[part 9 of 22: package /Cluster]
AUTOSAR XML (schema 4-3-0)
package /Cluster  (continued)
  can cluster E3V_K2CANFD: baudrate=500000, protocol-name=CAN, protocol-version=2.0, bus-off-recovery={bor-counter-l-1-to-l-2=1, bor-time-l-1=0.05, bor-time-l-2=0.2}, can-fd-baudrate=500000  (continued)
    can physical channel CHNL: comm-connectors=CN_E3V_K2CANFD  (continued)
      frame NMH_BCM1_XIX_E3V_K2CANFD: id 0x1B00000E, from SAM, frame-length=8, can-addressing-mode=EXTENDED, can-frame-rx-behavior=CAN-20, can-frame-tx-behavior=CAN-20, rx-identifier-range={lower-can-id=452984832, upper-can-id=452985855}
        nm pdu NMH_BCM1_XIX_E3V_K2CANFD: length=8, unused-bit-pattern=0
          signal NM_BCM1_CBV_AWB_XIX_NMH_BCM1_XIX_E3V_K2CANFD: start 12, 1 bit, little-endian, data-type-policy=OVERRIDE, i-signal-type=PRIMITIVE, init-value=0, base-type=BT_NM_BCM1_CBV_AWB, compu {0=Cx0_Passiver_WakeUp (CM_NM_BCM1_CBV_AWB_Cx0_Passiver_WakeUp), 1=Cx1_Aktiver_WakeUp (CM_NM_BCM1_CBV_AWB_Cx1_Aktiver_WakeUp)}, range raw 0..1, transfer-property=TRIGGERED  # Das Signal ist zu setzen, wenn das SG aktiv den Bus geweckt hat 0 = Passiver_WakeUp = SG hat das Netzwerk nicht aktiv geweckt 1 = Akitiver_WakeUp = SG hat das Netzwerk aktiv geweckt
          signal NM_BCM1_CBV_CRI_XIX_NMH_BCM1_XIX_E3V_K2CANFD: start 14, 1 bit, little-endian, data-type-policy=OVERRIDE, i-signal-type=PRIMITIVE, base-type=BT_NM_BCM1_CBV_CRI, compu {0=Cx0_NM_ohne_Clusteranforderungen (CM_NM_BCM1_CBV_CRI_Cx0_NM_ohne_Clusteranforderungen), 1=Cx1_NM_mit_Clusteranforderungen (CM_NM_BCM1_CBV_CRI_Cx1_NM_mit_Clusteranforderungen)}, range raw 0..1, transfer-property=TRIGGERED  # Das Signal ist dauerhaft gesetzt, wenn das NM-Layout Cluster- Anforderungen enthält
          signal NM_BCM1_NM_State_XIX_NMH_BCM1_XIX_E3V_K2CANFD: start 16, 6 bit, little-endian, data-type-policy=OVERRIDE, i-signal-type=PRIMITIVE, init-value=0, base-type=BT_NM_BCM1_NM_State, compu {0=Cx0_Init (CM_NM_BCM1_NM_State_Cx0_Init), 1=Cx1_NM_RM_aus_BSM (CM_NM_BCM1_NM_State_Cx1_NM_RM_aus_BSM), 2=Cx2_NM_RM_aus_PBSM (CM_NM_BCM1_NM_State_Cx2_NM_RM_aus_PBSM), 4=Cx4_NM_NO_aus_RM (CM_NM_BCM1_NM_State_Cx4_NM_NO_aus_RM), 8=Cx8_NM_NO_aus_RS (CM_NM_BCM1_NM_State_Cx8_NM_NO_aus_RS), 16=Cx10_reserved (CM_NM_BCM1_NM_State_Cx10_reserved), 32=Cx20_reserved (CM_NM_BCM1_NM_State_Cx20_reserved)}, range raw 0..32, transfer-property=TRIGGERED  # 1 = Zustand Repeat Message (<-- Bus-Sleep Mode) 2 = Zustand Repeat Message (<-- Prepare Bus-Sleep Mode) 4 = Zustand Normal Operation (<-- Repeat Message) 8 = Zustand Normal Operation (<-- Ready Sleep)
          signal NM_BCM1_Car_Wakeup_XIX_NMH_BCM1_XIX_E3V_K2CANFD: start 22, 1 bit, little-endian, data-type-policy=OVERRIDE, i-signal-type=PRIMITIVE, init-value=0, base-type=BT_NM_BCM1_Car_Wakeup, compu {0=Cx0_Inaktiv (CM_NM_BCM1_Car_Wakeup_Cx0_Inaktiv), 1=Cx1_Car_Wakeup (CM_NM_BCM1_Car_Wakeup_Cx1_Car_Wakeup)}, range raw 0..1, transfer-property=TRIGGERED  # Car Wakeup (Gateway wertet aus) MQB: -Kl.58xd, Kl.58xs, Kl.58xt eingeschaltet oder ausgeschaltet oder Dimmungssignal wurde vom Kunden geändert (nicht vom Fototransistor) -S-Kontakt wurde ein- oder ausgeschaltet -Remotestartbetrieb -Tankklappe wurde geschlossen (Drucktank) -ValetParking-Taster MQB BEV/PHEV: -Zustandswechsel_ZV -Ladesteckerentriegelung und Ladesteckerverriegelung MQB2020 & MQBw_Baseline: -KL.58x an/aus: Licht ein-/ausschalten -Beleuchtung für Schalter, Displays ein/aus -S-Kontakt an auf aus: Deaktivierung Infotainment, EPB anziehen, u.a. -S-Kontakt aus auf an: Aktivierung Infotainment u.a. - Remotestartbetrieb: angefordert (maximal 2x10 Minuten), mit HW Kl.15 ein und ZAS Kl.15 aus - Einfrierschutz: Einfrierschutz angefordert, mit HW Kl.15 ein und ZAS Kl.15 aus MLBevo: - LIN_1: Drehen Lichtdrehschalter in Stellung Standlicht - LIN_3: Visualisierung Secundärfunktionen - KL58xt Ende
          signal NM_BCM1_UDS_CC_XIX_NMH_BCM1_XIX_E3V_K2CANFD: start 23, 1 bit, little-endian, data-type-policy=OVERRIDE, i-signal-type=PRIMITIVE, init-value=0, base-type=BT_NM_BCM1_UDS_CC, compu {0=Cx0_Inaktiv (CM_NM_BCM1_UDS_CC_Cx0_Inaktiv), 1=Cx1_CC_aktiv (CM_NM_BCM1_UDS_CC_Cx1_CC_aktiv)}, range raw 0..1, transfer-property=TRIGGERED  # Funktionseinschränkung aufgrund aktivem UDS-Communication Control, siehe VW80124
          signal NM_BCM1_NM_aktiv_KL15_XIX_NMH_BCM1_XIX_E3V_K2CANFD: start 24, 1 bit, little-endian, data-type-policy=OVERRIDE, i-signal-type=PRIMITIVE, init-value=0, base-type=BT_NM_BCM1_NM_aktiv_KL15, compu {0=Cx0_Inaktiv (CM_NM_BCM1_NM_aktiv_KL15_Cx0_Inaktiv), 1=Cx1_KL15_EIN (CM_NM_BCM1_NM_aktiv_KL15_Cx1_KL15_EIN)}, range raw 0..1, transfer-property=TRIGGERED  # Steuergerät hat KL15-EIN erkannt
          signal NM_BCM1_NM_aktiv_Diagnose_XIX_NMH_BCM1_XIX_E3V_K2CANFD: start 25, 1 bit, little-endian, data-type-policy=OVERRIDE, i-signal-type=PRIMITIVE, init-value=0, base-type=BT_NM_BCM1_NM_aktiv_Diagnose, compu {0=Cx0_Init (CM_NM_BCM1_NM_aktiv_Diagnose_Cx0_Init), 1=Cx1_Diagnose_aktiv (CM_NM_BCM1_NM_aktiv_Diagnose_Cx1_Diagnose_aktiv)}, range raw 0..1, transfer-property=TRIGGERED  # Diagnose befindet sich nach VW80124 in einer NonDefaultDiagnostic-Session, z.B. ExtendedDiagnostic-Session
          signal NM_BCM1_NM_aktiv_Tmin_XIX_NMH_BCM1_XIX_E3V_K2CANFD: start 26, 1 bit, little-endian, data-type-policy=OVERRIDE, i-signal-type=PRIMITIVE, init-value=0, base-type=BT_NM_BCM1_NM_aktiv_Tmin, compu {0=Cx0_Inaktiv (CM_NM_BCM1_NM_aktiv_Tmin_Cx0_Inaktiv), 1=Cx1_Mindestaktivzeit (CM_NM_BCM1_NM_aktiv_Tmin_Cx1_Mindestaktivzeit)}, range raw 0..1, transfer-property=TRIGGERED  # Mindestaktivzeit ist noch nicht abgelaufen (bei jedem Weckereignis wird die Mindestaktivzeit neu gestartet)
          signal NM_BCM1_NM_aktiv_Aussenlicht_XIX_NMH_BCM1_XIX_E3V_K2CANFD: start 27, 1 bit, little-endian, data-type-policy=OVERRIDE, i-signal-type=PRIMITIVE, init-value=0, base-type=BT_NM_BCM1_NM_aktiv_Aussenlicht, compu {0=Cx0_Init (CM_NM_BCM1_NM_aktiv_Aussenlicht_Cx0_Init), 1=Cx1_Aussenlicht_aktiv (CM_NM_BCM1_NM_aktiv_Aussenlicht_Cx1_Aussenlicht_aktiv)}, range raw 0..1, transfer-property=TRIGGERED  # Funktionsnachlauf Außenlicht (inkl. Blinken, Warnblinken, Lichthupe)
          signal NM_BCM1_NM_aktiv_ZV_XIX_NMH_BCM1_XIX_E3V_K2CANFD: start 28, 1 bit, little-endian, data-type-policy=OVERRIDE, i-signal-type=PRIMITIVE, init-value=0, base-type=BT_NM_BCM1_NM_aktiv_ZV, compu {0=Cx0_Init (CM_NM_BCM1_NM_aktiv_ZV_Cx0_Init), 1=Cx1_ZV_aktiv (CM_NM_BCM1_NM_aktiv_ZV_Cx1_ZV_aktiv)}, range raw 0..1, transfer-property=TRIGGERED  # Funktionsnachlauf Zentralverriegelung
          signal NM_BCM1_NM_aktiv_Heizung_XIX_NMH_BCM1_XIX_E3V_K2CANFD: start 29, 1 bit, little-endian, data-type-policy=OVERRIDE, i-signal-type=PRIMITIVE, init-value=0, base-type=BT_NM_BCM1_NM_aktiv_Heizung, compu {0=Cx0_Init (CM_NM_BCM1_NM_aktiv_Heizung_Cx0_Init), 1=Cx1_Heizung_aktiv (CM_NM_BCM1_NM_aktiv_Heizung_Cx1_Heizung_aktiv)}, range raw 0..1, transfer-property=TRIGGERED  # Funktionsnachlauf Klima/Heizung
          signal NM_BCM1_NM_aktiv_Innenlicht_XIX_NMH_BCM1_XIX_E3V_K2CANFD: start 30, 1 bit, little-endian, data-type-policy=OVERRIDE, i-signal-type=PRIMITIVE, init-value=0, base-type=BT_NM_BCM1_NM_aktiv_Innenlicht, compu {0=Cx0_Init (CM_NM_BCM1_NM_aktiv_Innenlicht_Cx0_Init), 1=Cx1_Innenlicht_aktiv (CM_NM_BCM1_NM_aktiv_Innenlicht_Cx1_Innenlicht_aktiv)}, range raw 0..1, transfer-property=TRIGGERED  # Funktionsnachlauf Innenlicht (inkl. KL 58x)
          signal NM_BCM1_NM_aktiv_DWA_XIX_NMH_BCM1_XIX_E3V_K2CANFD: start 31, 1 bit, little-endian, data-type-policy=OVERRIDE, i-signal-type=PRIMITIVE, init-value=0, base-type=BT_NM_BCM1_NM_aktiv_DWA, compu {0=Cx0_Init (CM_NM_BCM1_NM_aktiv_DWA_Cx0_Init), 1=Cx1_DWA_aktiv (CM_NM_BCM1_NM_aktiv_DWA_Cx1_DWA_aktiv)}, range raw 0..1, transfer-property=TRIGGERED  # Funktionsnachlauf Diebstahlwarnanlage
          signal NM_BCM1_NM_aktiv_Funk_XIX_NMH_BCM1_XIX_E3V_K2CANFD: start 32, 1 bit, little-endian, data-type-policy=OVERRIDE, i-signal-type=PRIMITIVE, init-value=0, base-type=BT_NM_BCM1_NM_aktiv_Funk, compu {0=Cx0_Init (CM_NM_BCM1_NM_aktiv_Funk_Cx0_Init), 1=Cx1_Funk_aktiv (CM_NM_BCM1_NM_aktiv_Funk_Cx1_Funk_aktiv)}, range raw 0..1, transfer-property=TRIGGERED  # Funktionsnachlauf Funk
          signal NM_BCM1_NM_aktiv_Kessy_XIX_NMH_BCM1_XIX_E3V_K2CANFD: start 33, 1 bit, little-endian, data-type-policy=OVERRIDE, i-signal-type=PRIMITIVE, init-value=0, base-type=BT_NM_BCM1_NM_aktiv_Kessy, compu {0=Cx0_Init (CM_NM_BCM1_NM_aktiv_Kessy_Cx0_Init), 1=Cx1_Kessy_Komm_aktiv (CM_NM_BCM1_NM_aktiv_Kessy_Cx1_Kessy_Komm_aktiv)}, range raw 0..1, transfer-property=TRIGGERED  # Funktionsnachlauf Kessy
          signal NM_BCM1_NM_aktiv_TK_geschlossen_XIX_NMH_BCM1_XIX_E3V_K2CANFD: start 34, 1 bit, little-endian, data-type-policy=OVERRIDE, i-signal-type=PRIMITIVE, init-value=0, base-type=BT_NM_BCM1_NM_aktiv_TK_geschlossen, compu {0=Cx0_Init (CM_NM_BCM1_NM_aktiv_TK_geschlossen_Cx0_Init), 1=Cx1_TK_geschlossen_aktiv (CM_NM_BCM1_NM_aktiv_TK_geschlossen_Cx1_TK_geschlossen_aktiv)}, range raw 0..1, transfer-property=TRIGGERED  # Drucktank: Rückmeldung des Tankklappenstatus (Tankklappe wurde geschlossen)
          signal NM_BCM1_NM_aktiv_Applikation_XIX_NMH_BCM1_XIX_E3V_K2CANFD: start 35, 1 bit, little-endian, data-type-policy=OVERRIDE, i-signal-type=PRIMITIVE, init-value=0, base-type=BT_NM_BCM1_NM_aktiv_Applikation, compu {1=Cx1_Applikationsanforderung_CAN (CM_NM_BCM1_NM_aktiv_Applikation_Cx1_Applikationsanforderung_CAN)}, range raw 1, transfer-property=TRIGGERED  # Eine Applikationsanforderung fordert den Bus.
          signal NM_BCM1_NM_aktiv_Remotestart_XIX_NMH_BCM1_XIX_E3V_K2CANFD: start 36, 1 bit, little-endian, data-type-policy=OVERRIDE, i-signal-type=PRIMITIVE, init-value=0, base-type=BT_NM_BCM1_NM_aktiv_Remotestart, compu {0=Cx0_Init (CM_NM_BCM1_NM_aktiv_Remotestart_Cx0_Init), 1=Cx1_Remotestart_aktiv (CM_NM_BCM1_NM_aktiv_Remotestart_Cx1_Remotestart_aktiv)}, range raw 0..1, transfer-property=TRIGGERED  # Funktionsnachlauf Remotestart
          signal NM_BCM1_NM_aktiv_Remot_Door_L_Un_XIX_NMH_BCM1_XIX_E3V_K2CANFD: start 37, 1 bit, little-endian, data-type-policy=OVERRIDE, i-signal-type=PRIMITIVE, init-value=0, base-type=BT_NM_BCM1_NM_aktiv_Remot_Door_L_Un, compu {0=Cx0_Inaktiv (CM_NM_BCM1_NM_aktiv_Remot_Door_L_Un_Cx0_Inaktiv), 1=Cx1_Remote_Door_Lock_Unlock_aktiv (CM_NM_BCM1_NM_aktiv_Remot_Door_L_Un_Cx1_Remote_Door_Lock_Unlock_aktiv)}, range raw 0..1, transfer-property=TRIGGERED  # Remote Door Lock oder Unlock wird ausgefuehrt
          signal NM_BCM1_CAB_V15_XIX_NMH_BCM1_XIX_E3V_K2CANFD: start 40, 24 bit, opaque, data-type-policy=OVERRIDE, i-signal-type=ARRAY, init-value=[0b00000000, 0b00000000, 0b00000000], base-type=BT_NM_BCM1_CAB_V15, compu {0=Cx0_Init (CM_NM_BCM1_CAB_V15_Cx0_Init), 1=Cx1_CAB_01_Antrieb (CM_NM_BCM1_CAB_V15_Cx1_CAB_01_Antrieb), 2=Cx2_CAB_02_Hybrid_Laden (CM_NM_BCM1_CAB_V15_Cx2_CAB_02_Hybrid_Laden), 4=Cx4_CAB_03_Fahrwerk (CM_NM_BCM1_CAB_V15_Cx4_CAB_03_Fahrwerk), 8=Cx8_CAB_04_Fahrerassistenz (CM_NM_BCM1_CAB_V15_Cx8_CAB_04_Fahrerassistenz), 16=Cx10_CAB_05_Komfort (CM_NM_BCM1_CAB_V15_Cx10_CAB_05_Komfort), 32=Cx20_CAB_06_Anzeige (CM_NM_BCM1_CAB_V15_Cx20_CAB_06_Anzeige), 64=Cx40_CAB_07_Connect (CM_NM_BCM1_CAB_V15_Cx40_CAB_07_Connect), 128=Cx80_CAB_08_MIB (CM_NM_BCM1_CAB_V15_Cx80_CAB_08_MIB), 256=Cx100_CAB_09_Standheizung (CM_NM_BCM1_CAB_V15_Cx100_CAB_09_Standheizung), 512=Cx200_CAB_10_MDK (CM_NM_BCM1_CAB_V15_Cx200_CAB_10_MDK), 1024=Cx400_CAB_11_VLAN_Fahrerassistenz (CM_NM_BCM1_CAB_V15_Cx400_CAB_11_VLAN_Fahrerassistenz), 4096=Cx1000_CAB_13_VLAN_Connect (CM_NM_BCM1_CAB_V15_Cx1000_CAB_13_VLAN_Connect), 8192=Cx2000_CAB_14_VLAN_Infotainment (CM_NM_BCM1_CAB_V15_Cx2000_CAB_14_VLAN_Infotainment), 16384=Cx4000_CAB_15_Laden (CM_NM_BCM1_CAB_V15_Cx4000_CAB_15_Laden), 32768=Cx8000_CAB_16_Licht (CM_NM_BCM1_CAB_V15_Cx8000_CAB_16_Licht), 65536=Cx10000_CAB_17_RTM (CM_NM_BCM1_CAB_V15_Cx10000_CAB_17_RTM)}, range raw 0..65536, transfer-property=TRIGGERED  # CAB = Clusteraktivbits (V15) CAB_03_Fahrwerk Änderung Türstatus (ELock Aktivierung ü. Airbag-SG) CAB_04_Fahrerassistenz Änderung Türstatus (weckt CPD)
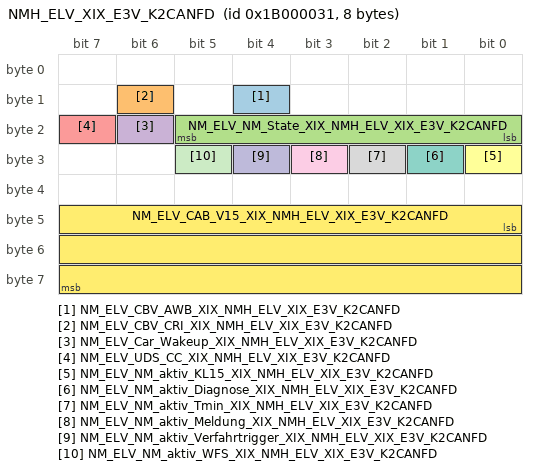
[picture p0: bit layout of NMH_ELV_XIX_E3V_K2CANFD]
      frame NMH_ELV_XIX_E3V_K2CANFD: id 0x1B000031, to SAM, frame-length=8, can-addressing-mode=EXTENDED, can-frame-rx-behavior=CAN-20, can-frame-tx-behavior=CAN-20, rx-identifier-range={lower-can-id=452984832, upper-can-id=452985855}
        nm pdu NMH_ELV_XIX_E3V_K2CANFD: length=8, unused-bit-pattern=0
          signal NM_ELV_CBV_AWB_XIX_NMH_ELV_XIX_E3V_K2CANFD: start 12, 1 bit, little-endian, data-type-policy=OVERRIDE, i-signal-type=PRIMITIVE, init-value=0, base-type=BT_NM_ELV_CBV_AWB, compu {0=Cx0_Passiver_WakeUp (CM_NM_ELV_CBV_AWB_Cx0_Passiver_WakeUp), 1=Cx1_Aktiver_WakeUp (CM_NM_ELV_CBV_AWB_Cx1_Aktiver_WakeUp)}, range raw 0..1, transfer-property=TRIGGERED  # Das Signal ist zu setzen, wenn das SG aktiv den Bus geweckt hat 0 = Passiver_WakeUp = SG hat das Netzwerk nicht aktiv geweckt 1 = Akitiver_WakeUp = SG hat das Netzwerk aktiv geweckt
          signal NM_ELV_CBV_CRI_XIX_NMH_ELV_XIX_E3V_K2CANFD: start 14, 1 bit, little-endian, data-type-policy=OVERRIDE, i-signal-type=PRIMITIVE, base-type=BT_NM_ELV_CBV_CRI, compu {0=Cx0_NM_ohne_Clusteranforderungen (CM_NM_ELV_CBV_CRI_Cx0_NM_ohne_Clusteranforderungen), 1=Cx1_NM_mit_Clusteranforderungen (CM_NM_ELV_CBV_CRI_Cx1_NM_mit_Clusteranforderungen)}, range raw 0..1, transfer-property=TRIGGERED  # Das Signal ist dauerhaft gesetzt, wenn das NM-Layout Cluster- Anforderungen enthält
          signal NM_ELV_NM_State_XIX_NMH_ELV_XIX_E3V_K2CANFD: start 16, 6 bit, little-endian, data-type-policy=OVERRIDE, i-signal-type=PRIMITIVE, init-value=0, base-type=BT_NM_ELV_NM_State, compu {0=Cx0_Init (CM_NM_ELV_NM_State_Cx0_Init), 1=Cx1_NM_RM_aus_BSM (CM_NM_ELV_NM_State_Cx1_NM_RM_aus_BSM), 2=Cx2_NM_RM_aus_PBSM (CM_NM_ELV_NM_State_Cx2_NM_RM_aus_PBSM), 4=Cx4_NM_NO_aus_RM (CM_NM_ELV_NM_State_Cx4_NM_NO_aus_RM), 8=Cx8_NM_NO_aus_RS (CM_NM_ELV_NM_State_Cx8_NM_NO_aus_RS), 16=Cx10_reserved (CM_NM_ELV_NM_State_Cx10_reserved), 32=Cx20_reserved (CM_NM_ELV_NM_State_Cx20_reserved)}, range raw 0..32, transfer-property=TRIGGERED, to SAM(timeout 2 s)  # 1 = Zustand Repeat Message (<-- Bus-Sleep Mode) 2 = Zustand Repeat Message (<-- Prepare Bus-Sleep Mode) 4 = Zustand Normal Operation (<-- Repeat Message) 8 = Zustand Normal Operation (<-- Ready Sleep)
          signal NM_ELV_Car_Wakeup_XIX_NMH_ELV_XIX_E3V_K2CANFD: start 22, 1 bit, little-endian, data-type-policy=OVERRIDE, i-signal-type=PRIMITIVE, init-value=0, base-type=BT_NM_ELV_Car_Wakeup, compu {0=Cx0_Inaktiv (CM_NM_ELV_Car_Wakeup_Cx0_Inaktiv), 1=Cx1_Car_Wakeup (CM_NM_ELV_Car_Wakeup_Cx1_Car_Wakeup)}, range raw 0..1, transfer-property=TRIGGERED  # Car Wakeup (Gateway wertet aus) ELV MQB_Gen1 -Gedrückter ZAT-Startwunsch MSG (für 2 Sekunden) -Verriegelungsbedingungen prüfen -Senden V-Signal (6 - 30 Sekunden) ELV MQB_Gen2 -Verriegelungsbedingungen prüfen -Senden V-Signal (6 - 30 Sekunden) ELV MQB2020: -Verriegelungsbedingungen prüfen -Senden V-Signal (6 - 30 Sekunden) ELV E3_1_1: -Verriegelungsbedingungen prüfen -Senden V-Signal (6 - 30 Sekunden) -Entriegelungs-Retry -bis zu 6 Entriegelungsversuche (ca. 15 Sekunden) mit Text nach 3.Versuch -Steuergerätefehler -SG-defekt, keine Entriegelung, Liegenbleiber ELV E3_1_2: -Verriegelungsbedingungen prüfen -Senden V-Signal (6 - 30 Sekunden) -Entriegelungs-Retry -bis zu 6 Entriegelungsversuche (ca. 15 Sekunden) mit Text nach 3.Versuch -Steuergerätefehler -SG-defekt, keine Entriegelung, Liegenbleiber ELV MLBevo: -Verriegelungsbedingungen prüfen -Meldung bei verspannter Lenksäule ELV MQBw_Baseline: -Verriegelungsbedingungen prüfen -Senden V-Signal (6 - 30 Sekunden) -Entriegelungs-Retry -bis zu 6 Entriegelungsversuche (ca. 15 Sekunden) mit Text nach 3.Versuch -Steuergerätefehler -SG-defekt, keine Entriegelung, Liegenbleiber
          signal NM_ELV_UDS_CC_XIX_NMH_ELV_XIX_E3V_K2CANFD: start 23, 1 bit, little-endian, data-type-policy=OVERRIDE, i-signal-type=PRIMITIVE, init-value=0, base-type=BT_NM_ELV_UDS_CC, compu {0=Cx0_Inaktiv (CM_NM_ELV_UDS_CC_Cx0_Inaktiv), 1=Cx1_CC_aktiv (CM_NM_ELV_UDS_CC_Cx1_CC_aktiv)}, range raw 0..1, transfer-property=TRIGGERED  # Funktionseinschränkung aufgrund aktivem UDS-Communication Control, siehe VW80124
          signal NM_ELV_NM_aktiv_KL15_XIX_NMH_ELV_XIX_E3V_K2CANFD: start 24, 1 bit, little-endian, data-type-policy=OVERRIDE, i-signal-type=PRIMITIVE, init-value=0, base-type=BT_NM_ELV_NM_aktiv_KL15, compu {0=Cx0_Inaktiv (CM_NM_ELV_NM_aktiv_KL15_Cx0_Inaktiv), 1=Cx1_KL15_EIN (CM_NM_ELV_NM_aktiv_KL15_Cx1_KL15_EIN)}, range raw 0..1, transfer-property=TRIGGERED  # Steuergerät hat KL15-EIN erkannt
          signal NM_ELV_NM_aktiv_Diagnose_XIX_NMH_ELV_XIX_E3V_K2CANFD: start 25, 1 bit, little-endian, data-type-policy=OVERRIDE, i-signal-type=PRIMITIVE, init-value=0, base-type=BT_NM_ELV_NM_aktiv_Diagnose, compu {0=Cx0_Init (CM_NM_ELV_NM_aktiv_Diagnose_Cx0_Init), 1=Cx1_Diagnose_aktiv (CM_NM_ELV_NM_aktiv_Diagnose_Cx1_Diagnose_aktiv)}, range raw 0..1, transfer-property=TRIGGERED  # Diagnose befindet sich nach VW80124 in einer NonDefaultDiagnostic-Session, z.B. ExtendedDiagnostic-Session
          signal NM_ELV_NM_aktiv_Tmin_XIX_NMH_ELV_XIX_E3V_K2CANFD: start 26, 1 bit, little-endian, data-type-policy=OVERRIDE, i-signal-type=PRIMITIVE, init-value=0, base-type=BT_NM_ELV_NM_aktiv_Tmin, compu {0=Cx0_Inaktiv (CM_NM_ELV_NM_aktiv_Tmin_Cx0_Inaktiv), 1=Cx1_Mindestaktivzeit (CM_NM_ELV_NM_aktiv_Tmin_Cx1_Mindestaktivzeit)}, range raw 0..1, transfer-property=TRIGGERED  # Mindestaktivzeit ist noch nicht abgelaufen (bei jedem Weckereignis wird die Mindestaktivzeit neu gestartet)
          signal NM_ELV_NM_aktiv_Meldung_XIX_NMH_ELV_XIX_E3V_K2CANFD: start 27, 1 bit, little-endian, data-type-policy=OVERRIDE, i-signal-type=PRIMITIVE, init-value=0, base-type=BT_NM_ELV_NM_aktiv_Meldung, compu {1=Cx1_Meldung_aktiv (CM_NM_ELV_NM_aktiv_Meldung_Cx1_Meldung_aktiv)}, range raw 1, transfer-property=TRIGGERED  # Fahrerinformation aktiv
          signal NM_ELV_NM_aktiv_Verfahrtrigger_XIX_NMH_ELV_XIX_E3V_K2CANFD: start 28, 1 bit, little-endian, data-type-policy=OVERRIDE, i-signal-type=PRIMITIVE, init-value=0, base-type=BT_NM_ELV_NM_aktiv_Verfahrtrigger, compu {1=Cx1_Trigger_aktiv (CM_NM_ELV_NM_aktiv_Verfahrtrigger_Cx1_Trigger_aktiv)}, range raw 1, transfer-property=TRIGGERED  # Aktiver Trigger zum Verfahren der ELV
          signal NM_ELV_NM_aktiv_WFS_XIX_NMH_ELV_XIX_E3V_K2CANFD: start 29, 1 bit, little-endian, data-type-policy=OVERRIDE, i-signal-type=PRIMITIVE, init-value=0, base-type=BT_NM_ELV_NM_aktiv_WFS, compu {1=Cx1_WFS_Komm_aktiv (CM_NM_ELV_NM_aktiv_WFS_Cx1_WFS_Komm_aktiv)}, range raw 1, transfer-property=TRIGGERED  # WFS-Kommunikation aktiv
          signal NM_ELV_CAB_V15_XIX_NMH_ELV_XIX_E3V_K2CANFD: start 40, 24 bit, opaque, data-type-policy=OVERRIDE, i-signal-type=ARRAY, init-value=[0b00000000, 0b00000000, 0b00000000], base-type=BT_NM_ELV_CAB_V15, compu {0=Cx0_Init (CM_NM_ELV_CAB_V15_Cx0_Init), 1=Cx1_CAB_01_Antrieb (CM_NM_ELV_CAB_V15_Cx1_CAB_01_Antrieb), 2=Cx2_CAB_02_Hybrid_Laden (CM_NM_ELV_CAB_V15_Cx2_CAB_02_Hybrid_Laden), 4=Cx4_CAB_03_Fahrwerk (CM_NM_ELV_CAB_V15_Cx4_CAB_03_Fahrwerk), 8=Cx8_CAB_04_Fahrerassistenz (CM_NM_ELV_CAB_V15_Cx8_CAB_04_Fahrerassistenz), 16=Cx10_CAB_05_Komfort (CM_NM_ELV_CAB_V15_Cx10_CAB_05_Komfort), 32=Cx20_CAB_06_Anzeige (CM_NM_ELV_CAB_V15_Cx20_CAB_06_Anzeige), 64=Cx40_CAB_07_Connect (CM_NM_ELV_CAB_V15_Cx40_CAB_07_Connect), 128=Cx80_CAB_08_MIB (CM_NM_ELV_CAB_V15_Cx80_CAB_08_MIB), 256=Cx100_CAB_09_Standheizung (CM_NM_ELV_CAB_V15_Cx100_CAB_09_Standheizung), 512=Cx200_CAB_10_MDK (CM_NM_ELV_CAB_V15_Cx200_CAB_10_MDK), 1024=Cx400_CAB_11_VLAN_Fahrerassistenz (CM_NM_ELV_CAB_V15_Cx400_CAB_11_VLAN_Fahrerassistenz), 4096=Cx1000_CAB_13_VLAN_Connect (CM_NM_ELV_CAB_V15_Cx1000_CAB_13_VLAN_Connect), 8192=Cx2000_CAB_14_VLAN_Infotainment (CM_NM_ELV_CAB_V15_Cx2000_CAB_14_VLAN_Infotainment), 16384=Cx4000_CAB_15_Laden (CM_NM_ELV_CAB_V15_Cx4000_CAB_15_Laden), 32768=Cx8000_CAB_16_Licht (CM_NM_ELV_CAB_V15_Cx8000_CAB_16_Licht), 65536=Cx10000_CAB_17_RTM (CM_NM_ELV_CAB_V15_Cx10000_CAB_17_RTM)}, range raw 0..65536, transfer-property=TRIGGERED  # CAB = Clusteraktivbits (V15)
      frame NMH_Gateway_XIX_E3V_K2CANFD: id 0x1B000010, to SAM, frame-length=8, can-addressing-mode=EXTENDED, can-frame-rx-behavior=CAN-20, can-frame-tx-behavior=CAN-20, rx-identifier-range={lower-can-id=452984832, upper-can-id=452985855}
        nm pdu NMH_Gateway_XIX_E3V_K2CANFD: length=8, unused-bit-pattern=0
          signal NM_Gateway_CBV_AWB_XIX_NMH_Gateway_XIX_E3V_K2CANFD: start 12, 1 bit, little-endian, data-type-policy=OVERRIDE, i-signal-type=PRIMITIVE, init-value=0, base-type=BT_NM_Gateway_CBV_AWB, compu {0=Cx0_Passiver_WakeUp (CM_NM_Gateway_CBV_AWB_Cx0_Passiver_WakeUp), 1=Cx1_Aktiver_WakeUp (CM_NM_Gateway_CBV_AWB_Cx1_Aktiver_WakeUp)}, range raw 0..1, transfer-property=TRIGGERED  # Das Signal ist zu setzen, wenn das SG aktiv den Bus geweckt hat 0 = Passiver_WakeUp = SG hat das Netzwerk nicht aktiv geweckt 1 = Akitiver_WakeUp = SG hat das Netzwerk aktiv geweckt
          signal NM_Gateway_CBV_CRI_XIX_NMH_Gateway_XIX_E3V_K2CANFD: start 14, 1 bit, little-endian, data-type-policy=OVERRIDE, i-signal-type=PRIMITIVE, base-type=BT_NM_Gateway_CBV_CRI, compu {0=Cx0_NM_ohne_Clusteranforderungen (CM_NM_Gateway_CBV_CRI_Cx0_NM_ohne_Clusteranforderungen), 1=Cx1_NM_mit_Clusteranforderungen (CM_NM_Gateway_CBV_CRI_Cx1_NM_mit_Clusteranforderungen)}, range raw 0..1, transfer-property=TRIGGERED  # Das Signal ist dauerhaft gesetzt, wenn das NM-Layout Cluster- Anforderungen enthält
          signal NM_Gateway_NM_State_XIX_NMH_Gateway_XIX_E3V_K2CANFD: start 16, 6 bit, little-endian, data-type-policy=OVERRIDE, i-signal-type=PRIMITIVE, init-value=0, base-type=BT_NM_Gateway_NM_State, compu {0=Cx0_Init (CM_NM_Gateway_NM_State_Cx0_Init), 1=Cx1_NM_RM_aus_BSM (CM_NM_Gateway_NM_State_Cx1_NM_RM_aus_BSM), 2=Cx2_NM_RM_aus_PBSM (CM_NM_Gateway_NM_State_Cx2_NM_RM_aus_PBSM), 4=Cx4_NM_NO_aus_RM (CM_NM_Gateway_NM_State_Cx4_NM_NO_aus_RM), 8=Cx8_NM_NO_aus_RS (CM_NM_Gateway_NM_State_Cx8_NM_NO_aus_RS), 16=Cx10_NM_RM_aus_RS (CM_NM_Gateway_NM_State_Cx10_NM_RM_aus_RS), 32=Cx20_NM_RM_aus_NO (CM_NM_Gateway_NM_State_Cx20_NM_RM_aus_NO)}, range raw 0..32, transfer-property=TRIGGERED, to SAM(timeout 2 s)  # 1 = Zustand Repeat Message (<-- Bus-Sleep Mode) 2 = Zustand Repeat Message (<-- Prepare Bus-Sleep Mode) 4 = Zustand Normal Operation (<-- Repeat Message) 8 = Zustand Normal Operation (<-- Ready Sleep) 16 = Zustand Repeat Message (<-- Ready Sleep) 32 = Zustand Repeat Message (<-- Normal Operation)
          signal NM_Gateway_Car_Wakeup_XIX_NMH_Gateway_XIX_E3V_K2CANFD: start 22, 1 bit, little-endian, data-type-policy=OVERRIDE, i-signal-type=PRIMITIVE, init-value=0, base-type=BT_NM_Gateway_Car_Wakeup, compu {0=Cx0_Inaktiv (CM_NM_Gateway_Car_Wakeup_Cx0_Inaktiv), 1=Cx1_Car_Wakeup (CM_NM_Gateway_Car_Wakeup_Cx1_Car_Wakeup)}, range raw 0..1, transfer-property=TRIGGERED  # Car Wakeup (Subbusmaster wertet aus) MQB: -Diagnose- oder Komponentenschutzmaster-Funktion weckt den schlafenden Subbus (z.B. MOST) E3_Volumen: - Diagnose aktiv -aktive Diagnosekommunikation am OBD-Stecker MQBw_Baseline: - Diagnose aktiv -aktive Diagnosekommunikation am OBD-Stecker
          signal NM_Gateway_UDS_CC_XIX_NMH_Gateway_XIX_E3V_K2CANFD: start 23, 1 bit, little-endian, data-type-policy=OVERRIDE, i-signal-type=PRIMITIVE, init-value=0, base-type=BT_NM_Gateway_UDS_CC, compu {0=Cx0_Inaktiv (CM_NM_Gateway_UDS_CC_Cx0_Inaktiv), 1=Cx1_CC_aktiv (CM_NM_Gateway_UDS_CC_Cx1_CC_aktiv)}, range raw 0..1, transfer-property=TRIGGERED  # Funktionseinschränkung aufgrund aktivem UDS-Communication Control, siehe VW80124
          signal NM_Gateway_NM_aktiv_KL15_XIX_NMH_Gateway_XIX_E3V_K2CANFD: start 24, 1 bit, little-endian, data-type-policy=OVERRIDE, i-signal-type=PRIMITIVE, init-value=0, base-type=BT_NM_Gateway_NM_aktiv_KL15, compu {0=Cx0_Inaktiv (CM_NM_Gateway_NM_aktiv_KL15_Cx0_Inaktiv), 1=Cx1_KL15_EIN (CM_NM_Gateway_NM_aktiv_KL15_Cx1_KL15_EIN)}, range raw 0..1, transfer-property=TRIGGERED  # Steuergerät hat KL15-EIN erkannt
          signal NM_Gateway_NM_aktiv_Diagnose_XIX_NMH_Gateway_XIX_E3V_K2CANFD: start 25, 1 bit, little-endian, data-type-policy=OVERRIDE, i-signal-type=PRIMITIVE, init-value=0, base-type=BT_NM_Gateway_NM_aktiv_Diagnose, compu {0=Cx0_Init (CM_NM_Gateway_NM_aktiv_Diagnose_Cx0_Init), 1=Cx1_Diagnose_aktiv (CM_NM_Gateway_NM_aktiv_Diagnose_Cx1_Diagnose_aktiv)}, range raw 0..1, transfer-property=TRIGGERED  # Diagnose befindet sich nach VW80124 in einer NonDefaultDiagnostic-Session, z.B. ExtendedDiagnostic-Session
          signal NM_Gateway_NM_aktiv_Tmin_XIX_NMH_Gateway_XIX_E3V_K2CANFD: start 26, 1 bit, little-endian, data-type-policy=OVERRIDE, i-signal-type=PRIMITIVE, init-value=0, base-type=BT_NM_Gateway_NM_aktiv_Tmin, compu {0=Cx0_Inaktiv (CM_NM_Gateway_NM_aktiv_Tmin_Cx0_Inaktiv), 1=Cx1_Mindestaktivzeit (CM_NM_Gateway_NM_aktiv_Tmin_Cx1_Mindestaktivzeit)}, range raw 0..1, transfer-property=TRIGGERED  # Mindestaktivzeit ist noch nicht abgelaufen (bei jedem Weckereignis wird die Mindestaktivzeit neu gestartet)
          signal NM_Gateway_NM_aktiv_Kessy_XIX_NMH_Gateway_XIX_E3V_K2CANFD: start 27, 1 bit, little-endian, data-type-policy=OVERRIDE, i-signal-type=PRIMITIVE, init-value=0, base-type=BT_NM_Gateway_NM_aktiv_Kessy, compu {0=Cx0_Inaktiv (CM_NM_Gateway_NM_aktiv_Kessy_Cx0_Inaktiv), 1=Cx1_Kessy_aktiv (CM_NM_Gateway_NM_aktiv_Kessy_Cx1_Kessy_aktiv)}, range raw 0..1, transfer-property=TRIGGERED  # Dieser Bus wird auf Grund einer Aktivität der Funktion Kessy wachgehalten
          signal NM_Gateway_NM_aktiv_Energie_XIX_NMH_Gateway_XIX_E3V_K2CANFD: start 28, 1 bit, little-endian, data-type-policy=OVERRIDE, i-signal-type=PRIMITIVE, init-value=0, base-type=BT_NM_Gateway_NM_aktiv_Energie, compu {0=Cx0_Inaktiv (CM_NM_Gateway_NM_aktiv_Energie_Cx0_Inaktiv), 1=Cx1_Energie_aktiv (CM_NM_Gateway_NM_aktiv_Energie_Cx1_Energie_aktiv)}, range raw 0..1, transfer-property=TRIGGERED  # Dieser Bus wird auf Grund einer Aktivität der Funktion EMHLR, HVEM, Dynamic Charging POI, Charging-Management-Server oder Extended Charging Monitoring wachgehalten
          signal NM_Gateway_NM_aktiv_Licht_XIX_NMH_Gateway_XIX_E3V_K2CANFD: start 29, 1 bit, little-endian, data-type-policy=OVERRIDE, i-signal-type=PRIMITIVE, init-value=0, base-type=BT_NM_Gateway_NM_aktiv_Licht, compu {0=Cx0_Inaktiv (CM_NM_Gateway_NM_aktiv_Licht_Cx0_Inaktiv), 1=Cx1_Licht_aktiv (CM_NM_Gateway_NM_aktiv_Licht_Cx1_Licht_aktiv)}, range raw 0..1, transfer-property=TRIGGERED  # Dieser Bus wird auf Grund einer Aktivität der Funktion Dimmung oder Standard Außenlicht wachgehalten
          signal NM_Gateway_NM_aktiv_USS_XIX_NMH_Gateway_XIX_E3V_K2CANFD: start 30, 1 bit, little-endian, data-type-policy=OVERRIDE, i-signal-type=PRIMITIVE, init-value=0, base-type=BT_NM_Gateway_NM_aktiv_USS, compu {0=Cx0_Inaktiv (CM_NM_Gateway_NM_aktiv_USS_Cx0_Inaktiv), 1=Cx1_USS_aktiv (CM_NM_Gateway_NM_aktiv_USS_Cx1_USS_aktiv)}, range raw 0..1, transfer-property=TRIGGERED  # Dieser Bus wird auf Grund einer Aktivität des User State Servers wachgehalten
          signal NM_Gateway_NM_aktiv_IAA_PSO_XIX_NMH_Gateway_XIX_E3V_K2CANFD: start 31, 1 bit, little-endian, data-type-policy=OVERRIDE, i-signal-type=PRIMITIVE, init-value=0, base-type=BT_NM_Gateway_NM_aktiv_IAA_PSO, compu {0=Cx0_Inaktiv (CM_NM_Gateway_NM_aktiv_IAA_PSO_Cx0_Inaktiv), 1=Cx1_Personalisierung_aktiv (CM_NM_Gateway_NM_aktiv_IAA_PSO_Cx1_Personalisierung_aktiv)}, range raw 0..1, transfer-property=TRIGGERED  # Dieser Bus wird auf Grund einer Aktivität der Personalisierung wachgehalten
          signal NM_Gateway_NM_aktiv_CAB_XIX_NMH_Gateway_XIX_E3V_K2CANFD: start 32, 1 bit, little-endian, data-type-policy=OVERRIDE, i-signal-type=PRIMITIVE, init-value=0, base-type=BT_NM_Gateway_NM_aktiv_CAB, compu {0=Cx0_Inaktiv (CM_NM_Gateway_NM_aktiv_CAB_Cx0_Inaktiv), 1=Cx1_CAB_aktiv (CM_NM_Gateway_NM_aktiv_CAB_Cx1_CAB_aktiv)}, range raw 0..1, transfer-property=TRIGGERED  # Nachlauf aufgrund Kopplung mehrerer Busse. z.B. K-CAN und K2-CAN, Clusteranforderung über CAB und Car Wakeup Anforderung.
          signal NM_Gateway_NM_aktiv_KS_XIX_NMH_Gateway_XIX_E3V_K2CANFD: start 33, 1 bit, little-endian, data-type-policy=OVERRIDE, i-signal-type=PRIMITIVE, init-value=0, base-type=BT_NM_Gateway_NM_aktiv_KS, compu {0=Cx0_Inaktiv (CM_NM_Gateway_NM_aktiv_KS_Cx0_Inaktiv), 1=Cx1_KS_aktiv (CM_NM_Gateway_NM_aktiv_KS_Cx1_KS_aktiv)}, range raw 0..1, transfer-property=TRIGGERED  # Dieser Bus wird auf Grund einer Aktivität des Komponentenschutzes wachgehalten
          signal NM_Gateway_NM_aktiv_PaCo_XIX_NMH_Gateway_XIX_E3V_K2CANFD: start 34, 1 bit, little-endian, data-type-policy=OVERRIDE, i-signal-type=PRIMITIVE, init-value=0, base-type=BT_NM_Gateway_NM_aktiv_PaCo, compu {0=Cx0_Inaktiv (CM_NM_Gateway_NM_aktiv_PaCo_Cx0_Inaktiv), 1=Cx1_PaCo_aktiv (CM_NM_Gateway_NM_aktiv_PaCo_Cx1_PaCo_aktiv)}, range raw 0..1, transfer-property=TRIGGERED  # Dieser Bus wird auf Grund einer Aktivität des Park Koordinators wachgehalten
          signal NM_Gateway_NM_aktiv_Standklima_XIX_NMH_Gateway_XIX_E3V_K2CANFD: start 35, 1 bit, little-endian, data-type-policy=OVERRIDE, i-signal-type=PRIMITIVE, init-value=0, base-type=BT_NM_Gateway_NM_aktiv_Standklima, compu {0=Cx0_Inaktiv (CM_NM_Gateway_NM_aktiv_Standklima_Cx0_Inaktiv), 1=Cx1_STK_aktiv (CM_NM_Gateway_NM_aktiv_Standklima_Cx1_STK_aktiv)}, range raw 0..1, transfer-property=TRIGGERED  # Dieser Bus wird auf Grund einer Aktivität der Standklimatisierung wachgehalten
          signal NM_Gateway_NM_aktiv_ZV_XIX_NMH_Gateway_XIX_E3V_K2CANFD: start 36, 1 bit, little-endian, data-type-policy=OVERRIDE, i-signal-type=PRIMITIVE, init-value=0, base-type=BT_NM_Gateway_NM_aktiv_ZV, compu {0=Cx0_Inaktiv (CM_NM_Gateway_NM_aktiv_ZV_Cx0_Inaktiv), 1=Cx1_ZV_aktiv (CM_NM_Gateway_NM_aktiv_ZV_Cx1_ZV_aktiv)}, range raw 0..1, transfer-property=TRIGGERED  # Dieser Bus wird auf Grund einer Aktivität der Zentralverriegelung wachgehalten
          signal NM_Gateway_NM_aktiv_RTM_XIX_NMH_Gateway_XIX_E3V_K2CANFD: start 37, 1 bit, little-endian, data-type-policy=OVERRIDE, i-signal-type=PRIMITIVE, init-value=0, base-type=BT_NM_Gateway_NM_aktiv_RTM, compu {0=Cx0_Inaktiv (CM_NM_Gateway_NM_aktiv_RTM_Cx0_Inaktiv), 1=Cx1_RTM_aktiv (CM_NM_Gateway_NM_aktiv_RTM_Cx1_RTM_aktiv)}, range raw 0..1, transfer-property=TRIGGERED  # Dieser Bus wird auf Grund einer Aktivität des Real Time Monitors wachgehalten
          signal NM_Gateway_NM_aktiv_ZM_XIX_NMH_Gateway_XIX_E3V_K2CANFD: start 38, 1 bit, little-endian, data-type-policy=OVERRIDE, i-signal-type=PRIMITIVE, init-value=0, base-type=BT_NM_Gateway_NM_aktiv_ZM, compu {0=Cx0_Inaktiv (CM_NM_Gateway_NM_aktiv_ZM_Cx0_Inaktiv), 1=Cx1_ZM_aktiv (CM_NM_Gateway_NM_aktiv_ZM_Cx1_ZM_aktiv)}, range raw 0..1, transfer-property=TRIGGERED  # Dieser Bus wird auf Grund einer Aktivität des Zeitmasters wachgehalten
          signal NM_Gateway_NM_aktiv_FoD_XIX_NMH_Gateway_XIX_E3V_K2CANFD: start 39, 1 bit, little-endian, data-type-policy=OVERRIDE, i-signal-type=PRIMITIVE, init-value=0, base-type=BT_NM_Gateway_NM_aktiv_FoD, compu {0=Cx0_Inaktiv (CM_NM_Gateway_NM_aktiv_FoD_Cx0_Inaktiv), 1=Cx1_FoD_aktiv (CM_NM_Gateway_NM_aktiv_FoD_Cx1_FoD_aktiv)}, range raw 0..1, transfer-property=TRIGGERED  # Dieser Bus wird auf Grund einer Aktivität der Function on Demand wachgehalten
          signal NM_Gateway_CAB_V15_XIX_NMH_Gateway_XIX_E3V_K2CANFD: start 40, 24 bit, opaque, data-type-policy=OVERRIDE, i-signal-type=ARRAY, init-value=[0b00000000, 0b00000000, 0b00000000], base-type=BT_NM_Gateway_CAB_V15, compu {0=Cx0_Init (CM_NM_Gateway_CAB_V15_Cx0_Init), 1=Cx1_CAB_01_Antrieb (CM_NM_Gateway_CAB_V15_Cx1_CAB_01_Antrieb), 2=Cx2_CAB_02_Hybrid_Laden (CM_NM_Gateway_CAB_V15_Cx2_CAB_02_Hybrid_Laden), 4=Cx4_CAB_03_Fahrwerk (CM_NM_Gateway_CAB_V15_Cx4_CAB_03_Fahrwerk), 8=Cx8_CAB_04_Fahrerassistenz (CM_NM_Gateway_CAB_V15_Cx8_CAB_04_Fahrerassistenz), 16=Cx10_CAB_05_Komfort (CM_NM_Gateway_CAB_V15_Cx10_CAB_05_Komfort), 32=Cx20_CAB_06_Anzeige (CM_NM_Gateway_CAB_V15_Cx20_CAB_06_Anzeige), 64=Cx40_CAB_07_Connect (CM_NM_Gateway_CAB_V15_Cx40_CAB_07_Connect), 128=Cx80_CAB_08_MIB (CM_NM_Gateway_CAB_V15_Cx80_CAB_08_MIB), 256=Cx100_CAB_09_Standheizung (CM_NM_Gateway_CAB_V15_Cx100_CAB_09_Standheizung), 512=Cx200_CAB_10_MDK (CM_NM_Gateway_CAB_V15_Cx200_CAB_10_MDK), 1024=Cx400_CAB_11_VLAN_Fahrerassistenz (CM_NM_Gateway_CAB_V15_Cx400_CAB_11_VLAN_Fahrerassistenz), 4096=Cx1000_CAB_13_VLAN_Connect (CM_NM_Gateway_CAB_V15_Cx1000_CAB_13_VLAN_Connect), 8192=Cx2000_CAB_14_VLAN_Infotainment (CM_NM_Gateway_CAB_V15_Cx2000_CAB_14_VLAN_Infotainment), 16384=Cx4000_CAB_15_Laden (CM_NM_Gateway_CAB_V15_Cx4000_CAB_15_Laden), 32768=Cx8000_CAB_16_Licht (CM_NM_Gateway_CAB_V15_Cx8000_CAB_16_Licht), 65536=Cx10000_CAB_17_RTM (CM_NM_Gateway_CAB_V15_Cx10000_CAB_17_RTM)}, range raw 0..65536, transfer-property=TRIGGERED  # CAB = Clusteraktivbits (V15)
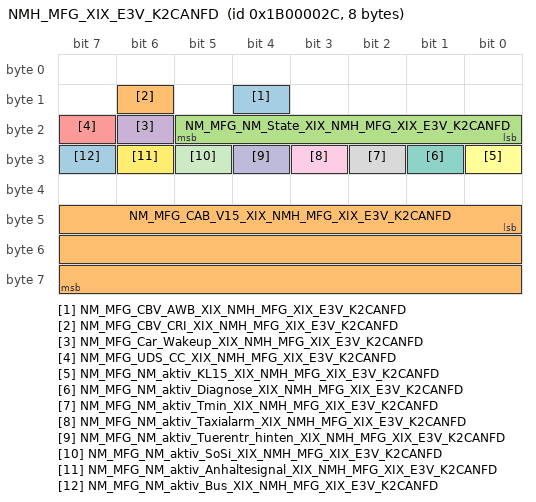
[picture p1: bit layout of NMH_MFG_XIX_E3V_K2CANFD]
      frame NMH_MFG_XIX_E3V_K2CANFD: id 0x1B00002C, to SAM, frame-length=8, can-addressing-mode=EXTENDED, can-frame-rx-behavior=CAN-20, can-frame-tx-behavior=CAN-20, rx-identifier-range={lower-can-id=452984832, upper-can-id=452985855}
        nm pdu NMH_MFG_XIX_E3V_K2CANFD: length=8, unused-bit-pattern=0
          signal NM_MFG_CBV_AWB_XIX_NMH_MFG_XIX_E3V_K2CANFD: start 12, 1 bit, little-endian, data-type-policy=OVERRIDE, i-signal-type=PRIMITIVE, init-value=0, base-type=BT_NM_MFG_CBV_AWB, compu {0=Cx0_Passiver_WakeUp (CM_NM_MFG_CBV_AWB_Cx0_Passiver_WakeUp), 1=Cx1_Aktiver_WakeUp (CM_NM_MFG_CBV_AWB_Cx1_Aktiver_WakeUp)}, range raw 0..1, transfer-property=TRIGGERED  # Das Signal ist zu setzen, wenn das SG aktiv den Bus geweckt hat 0 = Passiver_WakeUp = SG hat das Netzwerk nicht aktiv geweckt 1 = Akitiver_WakeUp = SG hat das Netzwerk aktiv geweckt
          signal NM_MFG_CBV_CRI_XIX_NMH_MFG_XIX_E3V_K2CANFD: start 14, 1 bit, little-endian, data-type-policy=OVERRIDE, i-signal-type=PRIMITIVE, base-type=BT_NM_MFG_CBV_CRI, compu {0=Cx0_NM_ohne_Clusteranforderungen (CM_NM_MFG_CBV_CRI_Cx0_NM_ohne_Clusteranforderungen), 1=Cx1_NM_mit_Clusteranforderungen (CM_NM_MFG_CBV_CRI_Cx1_NM_mit_Clusteranforderungen)}, range raw 0..1, transfer-property=TRIGGERED  # Das Signal ist dauerhaft gesetzt, wenn das NM-Layout Cluster- Anforderungen enthält
          signal NM_MFG_NM_State_XIX_NMH_MFG_XIX_E3V_K2CANFD: start 16, 6 bit, little-endian, data-type-policy=OVERRIDE, i-signal-type=PRIMITIVE, init-value=0, base-type=BT_NM_MFG_NM_State, compu {0=Cx0_Init (CM_NM_MFG_NM_State_Cx0_Init), 1=Cx1_NM_RM_aus_BSM (CM_NM_MFG_NM_State_Cx1_NM_RM_aus_BSM), 2=Cx2_NM_RM_aus_PBSM (CM_NM_MFG_NM_State_Cx2_NM_RM_aus_PBSM), 4=Cx4_NM_NO_aus_RM (CM_NM_MFG_NM_State_Cx4_NM_NO_aus_RM), 8=Cx8_NM_NO_aus_RS (CM_NM_MFG_NM_State_Cx8_NM_NO_aus_RS), 16=Cx10_reserved (CM_NM_MFG_NM_State_Cx10_reserved), 32=Cx20_reserved (CM_NM_MFG_NM_State_Cx20_reserved)}, range raw 0..32, transfer-property=TRIGGERED, to SAM(timeout 2 s)  # 1 = Zustand Repeat Message (<-- Bus-Sleep Mode) 2 = Zustand Repeat Message (<-- Prepare Bus-Sleep Mode) 4 = Zustand Normal Operation (<-- Repeat Message) 8 = Zustand Normal Operation (<-- Ready Sleep)
          signal NM_MFG_Car_Wakeup_XIX_NMH_MFG_XIX_E3V_K2CANFD: start 22, 1 bit, little-endian, data-type-policy=OVERRIDE, i-signal-type=PRIMITIVE, init-value=0, base-type=BT_NM_MFG_Car_Wakeup, compu {0=Cx0_Inaktiv (CM_NM_MFG_Car_Wakeup_Cx0_Inaktiv), 1=Cx1_Car_Wakeup (CM_NM_MFG_Car_Wakeup_Cx1_Car_Wakeup)}, range raw 0..1, transfer-property=TRIGGERED  # MQB: Steckung Ladestecker 230V Zweitbatterie erkannt. 1 sec gesendet
          signal NM_MFG_UDS_CC_XIX_NMH_MFG_XIX_E3V_K2CANFD: start 23, 1 bit, little-endian, data-type-policy=OVERRIDE, i-signal-type=PRIMITIVE, init-value=0, base-type=BT_NM_MFG_UDS_CC, compu {0=Cx0_Inaktiv (CM_NM_MFG_UDS_CC_Cx0_Inaktiv), 1=Cx1_CC_aktiv (CM_NM_MFG_UDS_CC_Cx1_CC_aktiv)}, range raw 0..1, transfer-property=TRIGGERED  # Funktionseinschränkung aufgrund aktivem UDS-Communication Control; siehe VW80124
          signal NM_MFG_NM_aktiv_KL15_XIX_NMH_MFG_XIX_E3V_K2CANFD: start 24, 1 bit, little-endian, data-type-policy=OVERRIDE, i-signal-type=PRIMITIVE, init-value=0, base-type=BT_NM_MFG_NM_aktiv_KL15, compu {0=Cx0_Inaktiv (CM_NM_MFG_NM_aktiv_KL15_Cx0_Inaktiv), 1=Cx1_KL15_EIN (CM_NM_MFG_NM_aktiv_KL15_Cx1_KL15_EIN)}, range raw 0..1, transfer-property=TRIGGERED  # Steuergerät hat KL15-EIN erkannt
          signal NM_MFG_NM_aktiv_Diagnose_XIX_NMH_MFG_XIX_E3V_K2CANFD: start 25, 1 bit, little-endian, data-type-policy=OVERRIDE, i-signal-type=PRIMITIVE, init-value=0, base-type=BT_NM_MFG_NM_aktiv_Diagnose, compu {0=Cx0_Init (CM_NM_MFG_NM_aktiv_Diagnose_Cx0_Init), 1=Cx1_Diagnose_aktiv (CM_NM_MFG_NM_aktiv_Diagnose_Cx1_Diagnose_aktiv)}, range raw 0..1, transfer-property=TRIGGERED  # Diagnose befindet sich nach VW80124 in einer NonDefaultDiagnostic-Session, z.B. ExtendedDiagnostic-Session
          signal NM_MFG_NM_aktiv_Tmin_XIX_NMH_MFG_XIX_E3V_K2CANFD: start 26, 1 bit, little-endian, data-type-policy=OVERRIDE, i-signal-type=PRIMITIVE, init-value=0, base-type=BT_NM_MFG_NM_aktiv_Tmin, compu {0=Cx0_Inaktiv (CM_NM_MFG_NM_aktiv_Tmin_Cx0_Inaktiv), 1=Cx1_Mindestaktivzeit (CM_NM_MFG_NM_aktiv_Tmin_Cx1_Mindestaktivzeit)}, range raw 0..1, transfer-property=TRIGGERED  # Mindestaktivzeit ist noch nicht abgelaufen (bei jedem Weckereignis wird die Mindestaktivzeit neu gestartet)
          signal NM_MFG_NM_aktiv_Taxialarm_XIX_NMH_MFG_XIX_E3V_K2CANFD: start 27, 1 bit, little-endian, data-type-policy=OVERRIDE, i-signal-type=PRIMITIVE, init-value=0, base-type=BT_NM_MFG_NM_aktiv_Taxialarm, compu {1=Cx1_Taxialarm_aktiv (CM_NM_MFG_NM_aktiv_Taxialarm_Cx1_Taxialarm_aktiv)}, range raw 1, transfer-property=TRIGGERED  # Aktiver Taxialarm
          signal NM_MFG_NM_aktiv_Tuerentr_hinten_XIX_NMH_MFG_XIX_E3V_K2CANFD: start 28, 1 bit, little-endian, data-type-policy=OVERRIDE, i-signal-type=PRIMITIVE, init-value=0, base-type=BT_NM_MFG_NM_aktiv_Tuerentr_hinten, compu {1=Cx1_Taster_betaetigt (CM_NM_MFG_NM_aktiv_Tuerentr_hinten_Cx1_Taster_betaetigt)}, range raw 1, transfer-property=TRIGGERED  # Taster Tuerentriegelung hinten betätigt (Taxi)
          signal NM_MFG_NM_aktiv_SoSi_XIX_NMH_MFG_XIX_E3V_K2CANFD: start 29, 1 bit, little-endian, data-type-policy=OVERRIDE, i-signal-type=PRIMITIVE, init-value=0, base-type=BT_NM_MFG_NM_aktiv_SoSi, compu {1=Cx1_SoSi_aktiv (CM_NM_MFG_NM_aktiv_SoSi_Cx1_SoSi_aktiv)}, range raw 1, transfer-property=TRIGGERED  # SoSi Lichtschaltung aktiv
          signal NM_MFG_NM_aktiv_Anhaltesignal_XIX_NMH_MFG_XIX_E3V_K2CANFD: start 30, 1 bit, little-endian, data-type-policy=OVERRIDE, i-signal-type=PRIMITIVE, init-value=0, base-type=BT_NM_MFG_NM_aktiv_Anhaltesignal, compu {1=Cx1_Anhaltesignal_aktiv (CM_NM_MFG_NM_aktiv_Anhaltesignal_Cx1_Anhaltesignal_aktiv)}, range raw 1, transfer-property=TRIGGERED  # Anhaltesignalgeber aktiv
          signal NM_MFG_NM_aktiv_Bus_XIX_NMH_MFG_XIX_E3V_K2CANFD: start 31, 1 bit, little-endian, data-type-policy=OVERRIDE, i-signal-type=PRIMITIVE, init-value=0, base-type=BT_NM_MFG_NM_aktiv_Bus, compu {1=Cx1_externer_Bus_aktiv (CM_NM_MFG_NM_aktiv_Bus_Cx1_externer_Bus_aktiv)}, range raw 1, transfer-property=TRIGGERED  # Aktive Kommunikation auf externen Bus
          signal NM_MFG_CAB_V15_XIX_NMH_MFG_XIX_E3V_K2CANFD: start 40, 24 bit, opaque, data-type-policy=OVERRIDE, i-signal-type=ARRAY, base-type=BT_NM_MFG_CAB_V15, compu {0=Cx0_Init (CM_NM_MFG_CAB_V15_Cx0_Init), 1=Cx1_CAB_01_Antrieb (CM_NM_MFG_CAB_V15_Cx1_CAB_01_Antrieb), 2=Cx2_CAB_02_Hybrid_Laden (CM_NM_MFG_CAB_V15_Cx2_CAB_02_Hybrid_Laden), 4=Cx4_CAB_03_Fahrwerk (CM_NM_MFG_CAB_V15_Cx4_CAB_03_Fahrwerk), 8=Cx8_CAB_04_Fahrerassistenz (CM_NM_MFG_CAB_V15_Cx8_CAB_04_Fahrerassistenz), 16=Cx10_CAB_05_Komfort (CM_NM_MFG_CAB_V15_Cx10_CAB_05_Komfort), 32=Cx20_CAB_06_Anzeige (CM_NM_MFG_CAB_V15_Cx20_CAB_06_Anzeige), 64=Cx40_CAB_07_Connect (CM_NM_MFG_CAB_V15_Cx40_CAB_07_Connect), 128=Cx80_CAB_08_MIB (CM_NM_MFG_CAB_V15_Cx80_CAB_08_MIB), 256=Cx100_CAB_09_Standheizung (CM_NM_MFG_CAB_V15_Cx100_CAB_09_Standheizung), 512=Cx200_CAB_10_MDK (CM_NM_MFG_CAB_V15_Cx200_CAB_10_MDK), 1024=Cx400_CAB_11_VLAN_Fahrerassistenz (CM_NM_MFG_CAB_V15_Cx400_CAB_11_VLAN_Fahrerassistenz), 4096=Cx1000_CAB_13_VLAN_Connect (CM_NM_MFG_CAB_V15_Cx1000_CAB_13_VLAN_Connect), 8192=Cx2000_CAB_14_VLAN_Infotainment (CM_NM_MFG_CAB_V15_Cx2000_CAB_14_VLAN_Infotainment), 16384=Cx4000_CAB_15_Laden (CM_NM_MFG_CAB_V15_Cx4000_CAB_15_Laden), 32768=Cx8000_CAB_16_Licht (CM_NM_MFG_CAB_V15_Cx8000_CAB_16_Licht), 65536=Cx10000_CAB_17_RTM (CM_NM_MFG_CAB_V15_Cx10000_CAB_17_RTM)}, range raw 0..65536, transfer-property=TRIGGERED  # CAB = Clusteraktivbits (V15)
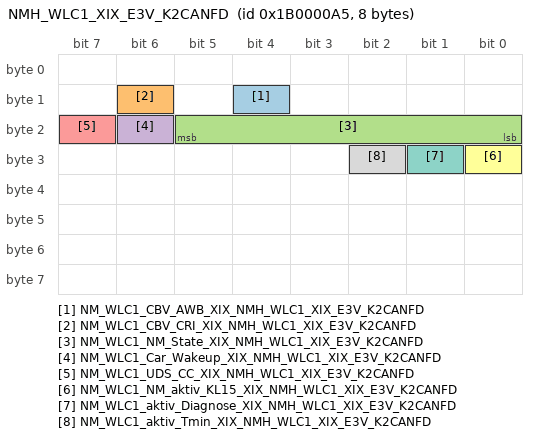
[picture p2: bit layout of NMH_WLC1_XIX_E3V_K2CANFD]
      frame NMH_WLC1_XIX_E3V_K2CANFD: id 0x1B0000A5, to SAM, frame-length=8, can-addressing-mode=EXTENDED, can-frame-rx-behavior=CAN-20, can-frame-tx-behavior=CAN-20, rx-identifier-range={lower-can-id=452984832, upper-can-id=452985855}
        nm pdu NMH_WLC1_XIX_E3V_K2CANFD: length=8, unused-bit-pattern=0
          signal NM_WLC1_CBV_AWB_XIX_NMH_WLC1_XIX_E3V_K2CANFD: start 12, 1 bit, little-endian, data-type-policy=OVERRIDE, i-signal-type=PRIMITIVE, init-value=0, base-type=BT_NM_WLC1_CBV_AWB, compu {0=Cx0_Passiver_WakeUp (CM_NM_WLC1_CBV_AWB_Cx0_Passiver_WakeUp), 1=Cx1_Aktiver_WakeUp (CM_NM_WLC1_CBV_AWB_Cx1_Aktiver_WakeUp)}, range raw 0..1, transfer-property=TRIGGERED  # Das Signal ist zu setzen, wenn das SG aktiv den Bus geweckt hat 0 = Passiver_WakeUp = SG hat das Netzwerk nicht aktiv geweckt 1 = Akitiver_WakeUp = SG hat das Netzwerk aktiv geweckt
          signal NM_WLC1_CBV_CRI_XIX_NMH_WLC1_XIX_E3V_K2CANFD: start 14, 1 bit, little-endian, data-type-policy=OVERRIDE, i-signal-type=PRIMITIVE, base-type=BT_NM_WLC1_CBV_CRI, compu {0=Cx0_NM_ohne_Clusteranforderungen (CM_NM_WLC1_CBV_CRI_Cx0_NM_ohne_Clusteranforderungen), 1=Cx1_NM_mit_Clusteranforderungen (CM_NM_WLC1_CBV_CRI_Cx1_NM_mit_Clusteranforderungen)}, range raw 0..1, transfer-property=TRIGGERED  # Das Signal ist dauerhaft gesetzt, wenn das NM-Layout Cluster- Anforderungen enthält
          signal NM_WLC1_NM_State_XIX_NMH_WLC1_XIX_E3V_K2CANFD: start 16, 6 bit, little-endian, data-type-policy=OVERRIDE, i-signal-type=PRIMITIVE, init-value=0, base-type=BT_NM_WLC1_NM_State, compu {0=Cx0_Init (CM_NM_WLC1_NM_State_Cx0_Init), 1=Cx1_NM_RM_aus_BSM (CM_NM_WLC1_NM_State_Cx1_NM_RM_aus_BSM), 2=Cx2_NM_RM_aus_PBSM (CM_NM_WLC1_NM_State_Cx2_NM_RM_aus_PBSM), 4=Cx4_NM_NO_aus_RM (CM_NM_WLC1_NM_State_Cx4_NM_NO_aus_RM), 8=Cx8_NM_NO_aus_RS (CM_NM_WLC1_NM_State_Cx8_NM_NO_aus_RS), 16=Cx10_reserved (CM_NM_WLC1_NM_State_Cx10_reserved), 32=Cx20_reserved (CM_NM_WLC1_NM_State_Cx20_reserved)}, range raw 0..32, transfer-property=TRIGGERED, to SAM(timeout 2 s)  # 1 = Zustand Repeat Message (<-- Bus-Sleep Mode) 2 = Zustand Repeat Message (<-- Prepare Bus-Sleep Mode) 4 = Zustand Normal Operation (<-- Repeat Message) 8 = Zustand Normal Operation (<-- Ready Sleep)
          signal NM_WLC1_Car_Wakeup_XIX_NMH_WLC1_XIX_E3V_K2CANFD: start 22, 1 bit, little-endian, data-type-policy=OVERRIDE, i-signal-type=PRIMITIVE, init-value=0, base-type=BT_NM_WLC1_Car_Wakeup, compu {0=Cx0_Inaktiv (CM_NM_WLC1_Car_Wakeup_Cx0_Inaktiv), 1=Cx1_Car_Wakeup (CM_NM_WLC1_Car_Wakeup_Cx1_Car_Wakeup)}, range raw 0..1, transfer-property=TRIGGERED  # Car Wakeup (Gateway wertet aus)
          signal NM_WLC1_UDS_CC_XIX_NMH_WLC1_XIX_E3V_K2CANFD: start 23, 1 bit, little-endian, data-type-policy=OVERRIDE, i-signal-type=PRIMITIVE, init-value=0, base-type=BT_NM_WLC1_UDS_CC, compu {0=Cx0_Inaktiv (CM_NM_WLC1_UDS_CC_Cx0_Inaktiv), 1=Cx1_CC_aktiv (CM_NM_WLC1_UDS_CC_Cx1_CC_aktiv)}, range raw 0..1, transfer-property=TRIGGERED  # Funktionseinschränkung aufgrund aktivem UDS-Communication Control, siehe VW80124
          signal NM_WLC1_NM_aktiv_KL15_XIX_NMH_WLC1_XIX_E3V_K2CANFD: start 24, 1 bit, little-endian, data-type-policy=OVERRIDE, i-signal-type=PRIMITIVE, init-value=0, base-type=BT_NM_WLC1_NM_aktiv_KL15, compu {0=Cx0_Inaktiv (CM_NM_WLC1_NM_aktiv_KL15_Cx0_Inaktiv), 1=Cx1_KL15_EIN (CM_NM_WLC1_NM_aktiv_KL15_Cx1_KL15_EIN)}, range raw 0..1, transfer-property=TRIGGERED  # Steuergerät hat KL15-EIN erkannt
          signal NM_WLC1_aktiv_Diagnose_XIX_NMH_WLC1_XIX_E3V_K2CANFD: start 25, 1 bit, little-endian, data-type-policy=OVERRIDE, i-signal-type=PRIMITIVE, init-value=0, base-type=BT_NM_WLC1_aktiv_Diagnose, compu {0=Cx0_Init (CM_NM_WLC1_aktiv_Diagnose_Cx0_Init), 1=Cx1_Diagnose_aktiv (CM_NM_WLC1_aktiv_Diagnose_Cx1_Diagnose_aktiv)}, range raw 0..1, transfer-property=TRIGGERED  # Diagnose befindet sich nach VW80124 in einer NonDefaultDiagnostic-Session, z.B. ExtendedDiagnostic-Session
          signal NM_WLC1_aktiv_Tmin_XIX_NMH_WLC1_XIX_E3V_K2CANFD: start 26, 1 bit, little-endian, data-type-policy=OVERRIDE, i-signal-type=PRIMITIVE, init-value=0, base-type=BT_NM_WLC1_aktiv_Tmin, compu {0=Cx0_Inaktiv (CM_NM_WLC1_aktiv_Tmin_Cx0_Inaktiv), 1=Cx1_Mindestaktivzeit (CM_NM_WLC1_aktiv_Tmin_Cx1_Mindestaktivzeit)}, range raw 0..1, transfer-property=TRIGGERED  # Mindestaktivzeit ist noch nicht abgelaufen (bei jedem Weckereignis wird die Mindestaktivzeit neu gestartet)
      frame OBDC_BCM1_Req_FD_XIX_E3V_K2CANFD: id 0x1C40020E, to SAM, frame-length=64, can-addressing-mode=EXTENDED, can-frame-rx-behavior=CAN-FD, can-frame-tx-behavior=CAN-FD
        n pdu OBDC_BCM1_Req_FD_XIX_E3V_K2CANFD: length=64
      frame OBDC_BCM1_Resp_FD_XIX_E3V_K2CANFD: id 0x1C42020E, from SAM, frame-length=64, can-addressing-mode=EXTENDED, can-frame-rx-behavior=CAN-FD, can-frame-tx-behavior=CAN-FD
        n pdu OBDC_BCM1_Resp_FD_XIX_E3V_K2CANFD: length=64
      frame OBDC_Funktionaler_Req_All_FD_XIX_E3V_K2CANFD: id 0x1C410200, to SAM, frame-length=64, can-addressing-mode=EXTENDED, can-frame-rx-behavior=CAN-FD, can-frame-tx-behavior=CAN-FD
        n pdu OBDC_Funktionaler_Req_All_FD_XIX_E3V_K2CANFD: length=64
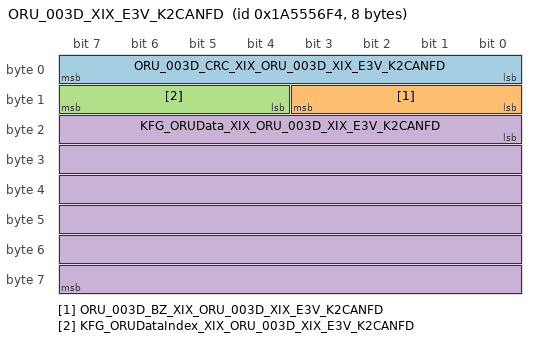
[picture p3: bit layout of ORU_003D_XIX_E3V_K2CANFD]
      frame ORU_003D_XIX_E3V_K2CANFD: id 0x1A5556F4, to SAM, frame-length=8, can-addressing-mode=EXTENDED, can-frame-rx-behavior=CAN-FD, can-frame-tx-behavior=CAN-FD
        pdu ORU_003D_XIX_E3V_K2CANFD_E2E: length=8, transmission-mode-true-timing=event-controlled-timing={number-of-repetitions=0, repetition-period=0.0}, unused-bit-pattern=0  # Fuer die Botschaft ist das Cyclic-Timing 0.5 zu verwenden.
          signal ORU_003D_CRC_XIX_ORU_003D_XIX_E3V_K2CANFD: start 0, 8 bit, little-endian, data-type-policy=OVERRIDE, i-signal-type=PRIMITIVE, init-value=0, base-type=BT_ORU_003D_CRC, compu {phys=raw for raw 0..255}, range phys 0..255, raw 0..255, to SAM(timeout 5 s)  # Für MLB: Berechnung siehe Lastenheft "Kommunikationsabsicherung für FlexRay und CAN" Ab MQB und MLBevo: Berechnung siehe Lastenheft "End-to-End Kommunikationsabsicherung" Endwerte siehe Begleitdokument "S-PDU Kennungsfolgen"
          signal ORU_003D_BZ_XIX_ORU_003D_XIX_E3V_K2CANFD: start 8, 4 bit, little-endian, data-type-policy=OVERRIDE, i-signal-type=PRIMITIVE, init-value=0, base-type=BT_ORU_003D_BZ, compu {phys=raw for raw 0..15}, range phys 0..15, raw 0..15, to SAM(timeout 5 s)  # 4bit Botschaftszähler, wird mit jeder Sendebotschaft inkrementiert
          signal KFG_ORUDataIndex_XIX_ORU_003D_XIX_E3V_K2CANFD: start 12, 4 bit, little-endian, data-type-policy=OVERRIDE, i-signal-type=PRIMITIVE, init-value=0, base-type=BT_KFG_ORUDataIndex, compu {phys=raw for raw 0..15}, range phys 0..15, raw 0..15, to SAM(timeout 5 s)  # Data index of the last 6 Bytes
          signal KFG_ORUData_XIX_ORU_003D_XIX_E3V_K2CANFD: start 16, 48 bit, little-endian, data-type-policy=OVERRIDE, i-signal-type=PRIMITIVE, init-value=0, base-type=BT_KFG_ORUData, compu {phys=raw for raw 0..281474976710655}, range phys 0..281474976710655, raw 0..281474976710655, to SAM(timeout 5 s)  # ORU information multiplexed - diagnostic address (2 bytes) - HW-part no (11 bytes) - HW version no. (3 bytes) - SW version no. (4 bytes) - IVD-P Value (64 bytes) need to be sent in combination with ORUDataIndex
          mapping SG_ORU_003D_XIX_E3V_K2CANFD: i-signal-group=SG_ORU_003D_XIX_E3V_K2CANFD, transfer-property=TRIGGERED-WITHOUT-REPETITION
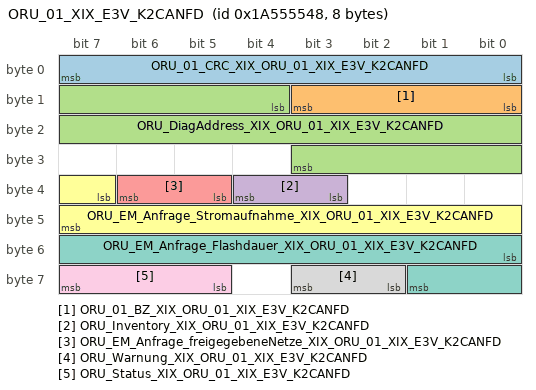
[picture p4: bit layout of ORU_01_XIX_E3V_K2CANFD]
      frame ORU_01_XIX_E3V_K2CANFD: id 0x1A555548, to SAM, frame-length=8, can-addressing-mode=EXTENDED, can-frame-rx-behavior=CAN-FD, can-frame-tx-behavior=CAN-FD
        pdu ORU_01_XIX_E3V_K2CANFD: length=8, minimum-delay=0.1, transmission-mode-true-timing={cyclic-timing={time-offset=0.0, time-period=0.5}, event-controlled-timing={number-of-repetitions=0, repetition-period=0.0}}, unused-bit-pattern=0
          signal ORU_01_CRC_XIX_ORU_01_XIX_E3V_K2CANFD: start 0, 8 bit, little-endian, data-type-policy=OVERRIDE, i-signal-type=PRIMITIVE, base-type=BT_ORU_01_CRC, compu {phys=raw for raw 0..255}, range phys 0..255, raw 0..255, transfer-property=PENDING
          signal ORU_01_BZ_XIX_ORU_01_XIX_E3V_K2CANFD: start 8, 4 bit, little-endian, data-type-policy=OVERRIDE, i-signal-type=PRIMITIVE, base-type=BT_ORU_01_BZ, compu {phys=raw for raw 0..15}, range phys 0..15, raw 0..15, transfer-property=PENDING
          signal ORU_DiagAddress_XIX_ORU_01_XIX_E3V_K2CANFD: start 12, 16 bit, little-endian, data-type-policy=OVERRIDE, i-signal-type=PRIMITIVE, init-value=0, base-type=BT_ORU_DiagAddress, compu {phys=raw for raw 0..65535}, range phys 0..65535, raw 0..65535, transfer-property=PENDING, to SAM(timeout 5 s)  # Diagnostic address of next ECU to be updated
          signal ORU_Inventory_XIX_ORU_01_XIX_E3V_K2CANFD: start 35, 2 bit, little-endian, data-type-policy=OVERRIDE, i-signal-type=PRIMITIVE, init-value=0, base-type=BT_ORU_Inventory, compu {0=Cx0_Init (CM_ORU_Inventory_Cx0_Init), 1=Cx1_Inventory_Erstellung_nicht_aktiv (CM_ORU_Inventory_Cx1_Inventory_Erstellung_nicht_aktiv), 2=Cx2_Inventory_Erstellung_aktiv (CM_ORU_Inventory_Cx2_Inventory_Erstellung_aktiv)}, range raw 0..2, transfer-property=PENDING  # Signal zur Anzeige, ob die Inventory Erstellung durch ORU aktiv ist. 0 = Init 1 = ORU Inventory Erstellung ist nicht aktiv 2 = ORU Inventory Erstellung ist aktiv
          signal ORU_EM_Anfrage_freigegebeneNetze_XIX_ORU_01_XIX_E3V_K2CANFD: start 37, 2 bit, little-endian, data-type-policy=OVERRIDE, i-signal-type=PRIMITIVE, init-value=0, base-type=BT_ORU_EM_Anfrage_freigegebeneNetze, compu {0=Cx0_only_12V (CM_ORU_EM_Anfrage_freigegebeneNetze_Cx0_only_12V), 1=Cx1_networks_48V_and_12V (CM_ORU_EM_Anfrage_freigegebeneNetze_Cx1_networks_48V_and_12V), 2=Cx2_networks_HV_and_12V (CM_ORU_EM_Anfrage_freigegebeneNetze_Cx2_networks_HV_and_12V), 3=Cx3_networks_HV_and_48V_and_12V (CM_ORU_EM_Anfrage_freigegebeneNetze_Cx3_networks_HV_and_48V_and_12V)}, range raw 0..3, transfer-property=TRIGGERED-ON-CHANGE-WITHOUT-REPETITION  # Meldung der während eines konkreten Online Remote Updates freigegebenen Netze (12V, 48V, HV)
          signal ORU_EM_Anfrage_Stromaufnahme_XIX_ORU_01_XIX_E3V_K2CANFD: start 39, 9 bit, little-endian, data-type-policy=OVERRIDE, i-signal-type=PRIMITIVE, init-value=0, base-type=BT_ORU_EM_Anfrage_Stromaufnahme, compu {phys=raw*0.1 for raw 0..511; unit Unit_Amper}, range phys 0..51.1 Unit_Amper, raw 0..511, unit=Unit_Amper, transfer-property=TRIGGERED-ON-CHANGE-WITHOUT-REPETITION  # Meldung der voraussichtlichen durchschnittlichen Stromaufnahme eines konkreten Online Remote Updates an das NVEM
          signal ORU_EM_Anfrage_Flashdauer_XIX_ORU_01_XIX_E3V_K2CANFD: start 48, 10 bit, little-endian, data-type-policy=OVERRIDE, i-signal-type=PRIMITIVE, init-value=0, base-type=BT_ORU_EM_Anfrage_Flashdauer, compu {phys=raw*10 for raw 0..1023; unit Unit_Secon}, range phys 0..10230 Unit_Secon, raw 0..1023, unit=Unit_Secon, transfer-property=TRIGGERED-ON-CHANGE-WITHOUT-REPETITION  # Anfrage an das Energiemanagement, ob ein konkretes Online Remote Update durchgeführt werden kann - Flashdauer in 10s.
          signal ORU_Warnung_XIX_ORU_01_XIX_E3V_K2CANFD: start 58, 2 bit, little-endian, data-type-policy=OVERRIDE, i-signal-type=PRIMITIVE, init-value=0, base-type=BT_ORU_Warnung, compu {0=Cx0_keine_Anzeige (CM_ORU_Warnung_Cx0_keine_Anzeige), 1=Cx1_Update_unvollstaendig_Prio1 (CM_ORU_Warnung_Cx1_Update_unvollstaendig_Prio1), 2=Cx2_Update_fehlgeschlagen_Prio1 (CM_ORU_Warnung_Cx2_Update_fehlgeschlagen_Prio1), 3=Cx3_reserviert (CM_ORU_Warnung_Cx3_reserviert)}, range raw 0..3, transfer-property=TRIGGERED-ON-CHANGE-WITHOUT-REPETITION  # Wenn durch Störungen der Funktion Online Remote Update nicht sichergestellt ist, dass vor Kunde keine Funktionseinschränkungen auftreten, muss der Benutzer des Fahrzeugs entsprechend gewarnt werden.
          signal ORU_Status_XIX_ORU_01_XIX_E3V_K2CANFD: start 61, 3 bit, little-endian, data-type-policy=OVERRIDE, i-signal-type=PRIMITIVE, init-value=0, base-type=BT_ORU_Status, compu {0=Cx0_IDLE (CM_ORU_Status_Cx0_IDLE), 1=Cx1_PENDING (CM_ORU_Status_Cx1_PENDING), 2=Cx2_PREPARATION (CM_ORU_Status_Cx2_PREPARATION), 3=Cx3_PREPARATION_HV (CM_ORU_Status_Cx3_PREPARATION_HV), 4=Cx4_RUNNING (CM_ORU_Status_Cx4_RUNNING), 5=Cx5_RUNNING_HV (CM_ORU_Status_Cx5_RUNNING_HV), 6=Cx6_PENDING_NOTREADY (CM_ORU_Status_Cx6_PENDING_NOTREADY), 7=Cx7_FAILURE_POWERTRAIN_DISABLED (CM_ORU_Status_Cx7_FAILURE_POWERTRAIN_DISABLED)}, range raw 0..7, transfer-property=TRIGGERED-ON-CHANGE-WITHOUT-REPETITION, to SAM(timeout 5 s)  # Verteilung des internen ORU Zustandes
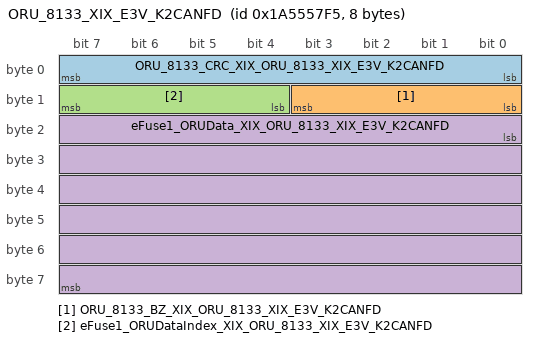
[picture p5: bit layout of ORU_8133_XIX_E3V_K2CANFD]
      frame ORU_8133_XIX_E3V_K2CANFD: id 0x1A5557F5, to SAM, frame-length=8, can-addressing-mode=EXTENDED, can-frame-rx-behavior=CAN-FD, can-frame-tx-behavior=CAN-FD
        pdu ORU_8133_XIX_E3V_K2CANFD_E2E: length=8, transmission-mode-true-timing=event-controlled-timing={number-of-repetitions=0, repetition-period=0.0}, unused-bit-pattern=0  # Fuer die Botschaft ist das Cyclic-Timing 0.5 zu verwenden.
          signal ORU_8133_CRC_XIX_ORU_8133_XIX_E3V_K2CANFD: start 0, 8 bit, little-endian, data-type-policy=OVERRIDE, i-signal-type=PRIMITIVE, init-value=0, base-type=BT_ORU_8133_CRC, compu {phys=raw for raw 0..255}, range phys 0..255, raw 0..255, to SAM(timeout 5 s)  # Für MLB: Berechnung siehe Lastenheft "Kommunikationsabsicherung für FlexRay und CAN" Ab MQB und MLBevo: Berechnung siehe Lastenheft "End-to-End Kommunikationsabsicherung" Endwerte siehe Begleitdokument "S-PDU Kennungsfolgen"
          signal ORU_8133_BZ_XIX_ORU_8133_XIX_E3V_K2CANFD: start 8, 4 bit, little-endian, data-type-policy=OVERRIDE, i-signal-type=PRIMITIVE, init-value=0, base-type=BT_ORU_8133_BZ, compu {phys=raw for raw 0..15}, range phys 0..15, raw 0..15, to SAM(timeout 5 s)  # 4bit Botschaftszähler, wird mit jeder Sendebotschaft inkrementiert
          signal eFuse1_ORUDataIndex_XIX_ORU_8133_XIX_E3V_K2CANFD: start 12, 4 bit, little-endian, data-type-policy=OVERRIDE, i-signal-type=PRIMITIVE, base-type=BT_eFuse1_ORUDataIndex, compu {phys=raw for raw 0..15}, range phys 0..15, raw 0..15, to SAM(timeout 5 s)  # Data index of the last 6 Bytes
          signal eFuse1_ORUData_XIX_ORU_8133_XIX_E3V_K2CANFD: start 16, 48 bit, little-endian, data-type-policy=OVERRIDE, i-signal-type=PRIMITIVE, base-type=BT_eFuse1_ORUData, compu {phys=raw for raw 0..281474976710655}, range phys 0..281474976710655, raw 0..281474976710655, to SAM(timeout 5 s)  # "ORU information multiplexed - diagnostic address (2 bytes) - HW-part no (11 bytes) - HW version no. (3 bytes) - SW version no. (4 bytes) - IVD-P Value (64 bytes) need to be sent in combination with ORUDataIndex"
          mapping SG_ORU_8133_XIX_E3V_K2CANFD: i-signal-group=SG_ORU_8133_XIX_E3V_K2CANFD, transfer-property=TRIGGERED-WITHOUT-REPETITION
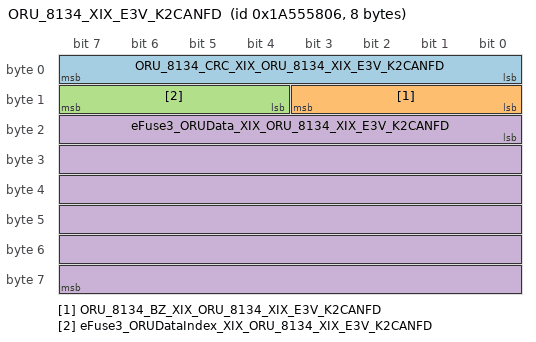
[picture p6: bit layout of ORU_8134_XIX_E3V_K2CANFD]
      frame ORU_8134_XIX_E3V_K2CANFD: id 0x1A555806, to SAM, frame-length=8, can-addressing-mode=EXTENDED, can-frame-rx-behavior=CAN-FD, can-frame-tx-behavior=CAN-FD
        pdu ORU_8134_XIX_E3V_K2CANFD_E2E: length=8, transmission-mode-true-timing=event-controlled-timing={number-of-repetitions=0, repetition-period=0.0}, unused-bit-pattern=0  # Fuer die Botschaft ist das Cyclic-Timing 0.5 zu verwenden.
          signal ORU_8134_CRC_XIX_ORU_8134_XIX_E3V_K2CANFD: start 0, 8 bit, little-endian, data-type-policy=OVERRIDE, i-signal-type=PRIMITIVE, init-value=0, base-type=BT_ORU_8134_CRC, compu {phys=raw for raw 0..255}, range phys 0..255, raw 0..255, to SAM(timeout 5 s)  # Für MLB: Berechnung siehe Lastenheft "Kommunikationsabsicherung für FlexRay und CAN" Ab MQB und MLBevo: Berechnung siehe Lastenheft "End-to-End Kommunikationsabsicherung" Endwerte siehe Begleitdokument "S-PDU Kennungsfolgen"
          signal ORU_8134_BZ_XIX_ORU_8134_XIX_E3V_K2CANFD: start 8, 4 bit, little-endian, data-type-policy=OVERRIDE, i-signal-type=PRIMITIVE, init-value=0, base-type=BT_ORU_8134_BZ, compu {phys=raw for raw 0..15}, range phys 0..15, raw 0..15, to SAM(timeout 5 s)  # 4bit Botschaftszähler, wird mit jeder Sendebotschaft inkrementiert
          signal eFuse3_ORUDataIndex_XIX_ORU_8134_XIX_E3V_K2CANFD: start 12, 4 bit, little-endian, data-type-policy=OVERRIDE, i-signal-type=PRIMITIVE, base-type=BT_eFuse3_ORUDataIndex, compu {phys=raw for raw 0..15}, range phys 0..15, raw 0..15, to SAM(timeout 5 s)  # Data index of the last 6 Bytes
          signal eFuse3_ORUData_XIX_ORU_8134_XIX_E3V_K2CANFD: start 16, 48 bit, little-endian, data-type-policy=OVERRIDE, i-signal-type=PRIMITIVE, base-type=BT_eFuse3_ORUData, compu {phys=raw for raw 0..281474976710655}, range phys 0..281474976710655, raw 0..281474976710655, to SAM(timeout 5 s)  # "ORU information multiplexed - diagnostic address (2 bytes) - HW-part no (11 bytes) - HW version no. (3 bytes) - SW version no. (4 bytes) - IVD-P Value (64 bytes) need to be sent in combination with ORUDataIndex"
          mapping SG_ORU_8134_XIX_E3V_K2CANFD: i-signal-group=SG_ORU_8134_XIX_E3V_K2CANFD, transfer-property=TRIGGERED-WITHOUT-REPETITION
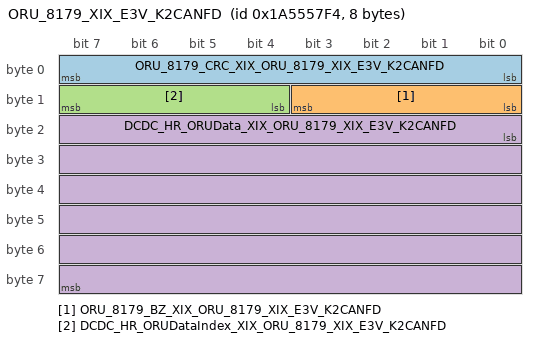
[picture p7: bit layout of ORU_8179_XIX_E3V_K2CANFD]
      frame ORU_8179_XIX_E3V_K2CANFD: id 0x1A5557F4, to SAM, frame-length=8, can-addressing-mode=EXTENDED, can-frame-rx-behavior=CAN-FD, can-frame-tx-behavior=CAN-FD
        pdu ORU_8179_XIX_E3V_K2CANFD_E2E: length=8, transmission-mode-true-timing=event-controlled-timing={number-of-repetitions=0, repetition-period=0.0}, unused-bit-pattern=0  # Fuer die Botschaft ist das Cyclic-Timing 0.5 zu verwenden.
          signal ORU_8179_CRC_XIX_ORU_8179_XIX_E3V_K2CANFD: start 0, 8 bit, little-endian, data-type-policy=OVERRIDE, i-signal-type=PRIMITIVE, init-value=0, base-type=BT_ORU_8179_CRC, compu {phys=raw for raw 0..255}, range phys 0..255, raw 0..255, to SAM(timeout 5 s)  # Für MLB: Berechnung siehe Lastenheft "Kommunikationsabsicherung für FlexRay und CAN" Ab MQB und MLBevo: Berechnung siehe Lastenheft "End-to-End Kommunikationsabsicherung" Endwerte siehe Begleitdokument "S-PDU Kennungsfolgen"
          signal ORU_8179_BZ_XIX_ORU_8179_XIX_E3V_K2CANFD: start 8, 4 bit, little-endian, data-type-policy=OVERRIDE, i-signal-type=PRIMITIVE, init-value=0, base-type=BT_ORU_8179_BZ, compu {phys=raw for raw 0..15}, range phys 0..15, raw 0..15, to SAM(timeout 5 s)  # 4bit Botschaftszähler, wird mit jeder Sendebotschaft inkrementiert
          signal DCDC_HR_ORUDataIndex_XIX_ORU_8179_XIX_E3V_K2CANFD: start 12, 4 bit, little-endian, data-type-policy=OVERRIDE, i-signal-type=PRIMITIVE, init-value=0, base-type=BT_DCDC_HR_ORUDataIndex, compu {phys=raw for raw 0..15}, range phys 0..15, raw 0..15, to SAM(timeout 5 s)  # Data index of the last 6 Bytes
          signal DCDC_HR_ORUData_XIX_ORU_8179_XIX_E3V_K2CANFD: start 16, 48 bit, little-endian, data-type-policy=OVERRIDE, i-signal-type=PRIMITIVE, init-value=0, base-type=BT_DCDC_HR_ORUData, compu {phys=raw for raw 0..281474976710655}, range phys 0..281474976710655, raw 0..281474976710655, to SAM(timeout 5 s)  # ORU information multiplexed - diagnostic address (2 bytes) - HW-part no (11 bytes) - HW version no. (3 bytes) - SW version no. (4 bytes) - IVD-P Value (64 bytes) need to be sent in combination with ORUDataIndex
          mapping SG_ORU_8179_XIX_E3V_K2CANFD: i-signal-group=SG_ORU_8179_XIX_E3V_K2CANFD, transfer-property=TRIGGERED-WITHOUT-REPETITION
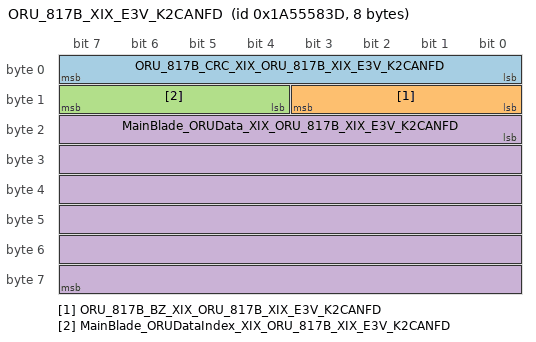
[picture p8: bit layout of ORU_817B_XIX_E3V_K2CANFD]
      frame ORU_817B_XIX_E3V_K2CANFD: id 0x1A55583D, to SAM, frame-length=8, can-addressing-mode=EXTENDED, can-frame-rx-behavior=CAN-FD, can-frame-tx-behavior=CAN-FD
        pdu ORU_817B_XIX_E3V_K2CANFD_E2E: length=8, transmission-mode-true-timing=event-controlled-timing={number-of-repetitions=0, repetition-period=0.0}, unused-bit-pattern=0  # Fuer die Botschaft ist das Cyclic-Timing 0.5 zu verwenden.
          signal ORU_817B_CRC_XIX_ORU_817B_XIX_E3V_K2CANFD: start 0, 8 bit, little-endian, data-type-policy=OVERRIDE, i-signal-type=PRIMITIVE, init-value=0, base-type=BT_ORU_817B_CRC, compu {phys=raw for raw 0..255}, range phys 0..255, raw 0..255, to SAM(timeout 5 s)  # Für MLB: Berechnung siehe Lastenheft "Kommunikationsabsicherung für FlexRay und CAN" Ab MQB und MLBevo: Berechnung siehe Lastenheft "End-to-End Kommunikationsabsicherung" Endwerte siehe Begleitdokument "S-PDU Kennungsfolgen"
          signal ORU_817B_BZ_XIX_ORU_817B_XIX_E3V_K2CANFD: start 8, 4 bit, little-endian, data-type-policy=OVERRIDE, i-signal-type=PRIMITIVE, init-value=0, base-type=BT_ORU_817B_BZ, compu {phys=raw for raw 0..15}, range phys 0..15, raw 0..15, to SAM(timeout 5 s)  # 4bit Botschaftszähler, wird mit jeder Sendebotschaft inkrementiert
          signal MainBlade_ORUDataIndex_XIX_ORU_817B_XIX_E3V_K2CANFD: start 12, 4 bit, little-endian, data-type-policy=OVERRIDE, i-signal-type=PRIMITIVE, init-value=0, base-type=BT_MainBlade_ORUDataIndex, compu {phys=raw for raw 0..15}, range phys 0..15, raw 0..15, to SAM(timeout 5 s)  # Data index of the last 6 Bytes
          signal MainBlade_ORUData_XIX_ORU_817B_XIX_E3V_K2CANFD: start 16, 48 bit, little-endian, data-type-policy=OVERRIDE, i-signal-type=PRIMITIVE, init-value=0, base-type=BT_MainBlade_ORUData, compu {phys=raw for raw 0..281474976710655}, range phys 0..281474976710655, raw 0..281474976710655, to SAM(timeout 5 s)  # "ORU information multiplexed - diagnostic address (2 bytes) - HW-part no (11 bytes) - HW version no. (3 bytes) - SW version no. (4 bytes) - IVD-P Value (64 bytes) need to be sent in combination with ORUDataIndex"
          mapping SG_ORU_817B_XIX_E3V_K2CANFD: i-signal-group=SG_ORU_817B_XIX_E3V_K2CANFD, transfer-property=TRIGGERED-WITHOUT-REPETITION
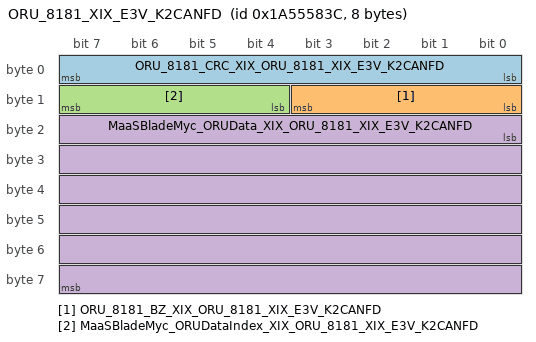
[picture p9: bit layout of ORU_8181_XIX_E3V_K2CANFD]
      frame ORU_8181_XIX_E3V_K2CANFD: id 0x1A55583C, to SAM, frame-length=8, can-addressing-mode=EXTENDED, can-frame-rx-behavior=CAN-FD, can-frame-tx-behavior=CAN-FD
        pdu ORU_8181_XIX_E3V_K2CANFD_E2E: length=8, transmission-mode-true-timing=event-controlled-timing={number-of-repetitions=0, repetition-period=0.0}, unused-bit-pattern=0  # Fuer die Botschaft ist das Cyclic-Timing 0.5 zu verwenden.
          signal ORU_8181_CRC_XIX_ORU_8181_XIX_E3V_K2CANFD: start 0, 8 bit, little-endian, data-type-policy=OVERRIDE, i-signal-type=PRIMITIVE, init-value=0, base-type=BT_ORU_8181_CRC, compu {phys=raw for raw 0..255}, range phys 0..255, raw 0..255, to SAM(timeout 5 s)  # Für MLB: Berechnung siehe Lastenheft "Kommunikationsabsicherung für FlexRay und CAN" Ab MQB und MLBevo: Berechnung siehe Lastenheft "End-to-End Kommunikationsabsicherung" Endwerte siehe Begleitdokument "S-PDU Kennungsfolgen"
          signal ORU_8181_BZ_XIX_ORU_8181_XIX_E3V_K2CANFD: start 8, 4 bit, little-endian, data-type-policy=OVERRIDE, i-signal-type=PRIMITIVE, init-value=0, base-type=BT_ORU_8181_BZ, compu {phys=raw for raw 0..15}, range phys 0..15, raw 0..15, to SAM(timeout 5 s)  # 4bit Botschaftszähler, wird mit jeder Sendebotschaft inkrementiert
          signal MaaSBladeMyc_ORUDataIndex_XIX_ORU_8181_XIX_E3V_K2CANFD: start 12, 4 bit, little-endian, data-type-policy=OVERRIDE, i-signal-type=PRIMITIVE, init-value=0, base-type=BT_MaaSBladeMyc_ORUDataIndex, compu {phys=raw for raw 0..15}, range phys 0..15, raw 0..15, to SAM(timeout 5 s)  # Data index of the last 6 Bytes
          signal MaaSBladeMyc_ORUData_XIX_ORU_8181_XIX_E3V_K2CANFD: start 16, 48 bit, little-endian, data-type-policy=OVERRIDE, i-signal-type=PRIMITIVE, init-value=0, base-type=BT_MaaSBladeMyc_ORUData, compu {phys=raw for raw 0..281474976710655}, range phys 0..281474976710655, raw 0..281474976710655, to SAM(timeout 5 s)  # "ORU information multiplexed - diagnostic address (2 bytes) - HW-part no (11 bytes) - HW version no. (3 bytes) - SW version no. (4 bytes) - IVD-P Value (64 bytes) need to be sent in combination with ORUDataIndex"
          mapping SG_ORU_8181_XIX_E3V_K2CANFD: i-signal-group=SG_ORU_8181_XIX_E3V_K2CANFD, transfer-property=TRIGGERED-WITHOUT-REPETITION
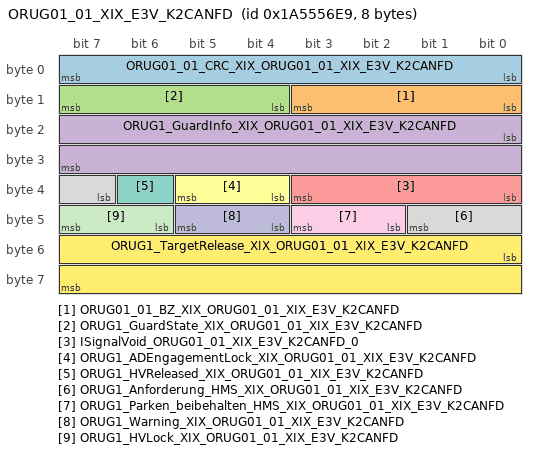
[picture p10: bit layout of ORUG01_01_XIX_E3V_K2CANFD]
      frame ORUG01_01_XIX_E3V_K2CANFD: id 0x1A5556E9, to SAM, frame-length=8, can-addressing-mode=EXTENDED, can-frame-rx-behavior=CAN-FD, can-frame-tx-behavior=CAN-FD
        pdu ORUG01_01_XIX_E3V_K2CANFD_E2E: length=8, transmission-mode-true-timing=event-controlled-timing={number-of-repetitions=0, repetition-period=0.0}, unused-bit-pattern=0  # Fuer die Botschaft ist das Cyclic-Timing 0.5 zu verwenden.
          signal ORUG01_01_CRC_XIX_ORUG01_01_XIX_E3V_K2CANFD: start 0, 8 bit, little-endian, data-type-policy=OVERRIDE, i-signal-type=PRIMITIVE, base-type=BT_ORUG01_01_CRC, compu {phys=raw for raw 0..255}, range phys 0..255, raw 0..255, to SAM(timeout 5 s)  # Für MLB: Berechnung siehe Lastenheft "Kommunikationsabsicherung für FlexRay und CAN" Ab MQB und MLBevo: Berechnung siehe Lastenheft "End-to-End Kommunikationsabsicherung" Endwerte siehe Begleitdokument "S-PDU Kennungsfolgen"
          signal ORUG01_01_BZ_XIX_ORUG01_01_XIX_E3V_K2CANFD: start 8, 4 bit, little-endian, data-type-policy=OVERRIDE, i-signal-type=PRIMITIVE, init-value=0, base-type=BT_ORUG01_01_BZ, compu {phys=raw for raw 0..15}, range phys 0..15, raw 0..15, to SAM(timeout 5 s)  # 4bit Botschaftszähler, wird mit jeder Sendebotschaft inkrementiert
          signal ORUG1_GuardState_XIX_ORUG01_01_XIX_E3V_K2CANFD: start 12, 4 bit, little-endian, data-type-policy=OVERRIDE, i-signal-type=PRIMITIVE, init-value=0, base-type=BT_ORUG1_GuardState, compu {0=Cx0_Idle (CM_ORUG1_GuardState_Cx0_Idle), 1=Cx1_DataErr (CM_ORUG1_GuardState_Cx1_DataErr), 2=Cx2_CountErr (CM_ORUG1_GuardState_Cx2_CountErr), 3=Cx3_Collecting (CM_ORUG1_GuardState_Cx3_Collecting), 4=Cx4_HwVerErr (CM_ORUG1_GuardState_Cx4_HwVerErr), 5=Cx5_Waiting (CM_ORUG1_GuardState_Cx5_Waiting), 6=Cx6_Ready (CM_ORUG1_GuardState_Cx6_Ready)}, range raw 0..6  # Idle = ORU guards are in Idle state DataErr = check of Metadata not succsessful CountErr = no. of ECUs differs between data and vehicle Collecting = data collection from ECUs is incomplete HwVerErr = wrong HW version foundWaiting = one or more ECU needs to be updated Ready = all safety rel ECUs reached their target SW
          signal ORUG1_GuardInfo_XIX_ORUG01_01_XIX_E3V_K2CANFD: start 16, 16 bit, little-endian, data-type-policy=OVERRIDE, i-signal-type=PRIMITIVE, init-value=0, base-type=BT_ORUG1_GuardInfo, compu {0=Cx0_Idle (CM_ORUG1_GuardInfo_Cx0_Idle), 1=Cx1_VehicleLockActive (CM_ORUG1_GuardInfo_Cx1_VehicleLockActive), 2=Cx2_HMSLocked (CM_ORUG1_GuardInfo_Cx2_HMSLocked), 4=Cx4_KLSLocked (CM_ORUG1_GuardInfo_Cx4_KLSLocked), 8=Cx8_PWRaLocked (CM_ORUG1_GuardInfo_Cx8_PWRaLocked), 16=Cx10_PWRcLocked (CM_ORUG1_GuardInfo_Cx10_PWRcLocked), 32=Cx20_HVLockActive (CM_ORUG1_GuardInfo_Cx20_HVLockActive), 64=Cx40_BCMeLocked (CM_ORUG1_GuardInfo_Cx40_BCMeLocked), 128=Cx80_OCCLocked (CM_ORUG1_GuardInfo_Cx80_OCCLocked), 256=Cx100_DCDCLocked (CM_ORUG1_GuardInfo_Cx100_DCDCLocked), 512=Cx200_WarningsSuppressed (CM_ORUG1_GuardInfo_Cx200_WarningsSuppressed), 1024=Cx400_CrashDetected (CM_ORUG1_GuardInfo_Cx400_CrashDetected), 2048=Cx800_Buffer1Blocked (CM_ORUG1_GuardInfo_Cx800_Buffer1Blocked), 4096=Cx1000_Buffer2Blocked (CM_ORUG1_GuardInfo_Cx1000_Buffer2Blocked), 8192=Cx2000_Buffer3Blocked (CM_ORUG1_GuardInfo_Cx2000_Buffer3Blocked), 16384=Cx4000_reserved (CM_ORUG1_GuardInfo_Cx4000_reserved)}, range raw 0..16384  # Information on locking failures
          signal ISignalVoid_ORUG01_01_XIX_E3V_K2CANFD_0: start 32, 4 bit, little-endian, system signal SignalVoid_ORUG01_01_0, data-type-policy=OVERRIDE, i-signal-type=PRIMITIVE, base-type=BT_SignalVoid
          signal ORUG1_ADEngagementLock_XIX_ORUG01_01_XIX_E3V_K2CANFD: start 36, 2 bit, little-endian, data-type-policy=OVERRIDE, i-signal-type=PRIMITIVE, init-value=0, base-type=BT_ORUG1_ADEngagementLock, invalid-value=Invalid_ORUG1_ADEngagementLock_XIX_ORUG01_01_XIX_E3V_K2CANFD:3, compu {0=Cx0_Idle (CM_ORUG1_ADEngagementLock_Cx0_Idle), 1=Cx1_ActiveLock (CM_ORUG1_ADEngagementLock_Cx1_ActiveLock), 2=Cx2_ReleaseLock (CM_ORUG1_ADEngagementLock_Cx2_ReleaseLock), 3=Cx3_Fehler (CM_ORUG1_ADEngagementLock_Cx3_Fehler)}, range raw 0..3  # Request to lock disengaged AD-system
          signal ORUG1_HVReleased_XIX_ORUG01_01_XIX_E3V_K2CANFD: start 38, 1 bit, little-endian, data-type-policy=OVERRIDE, i-signal-type=PRIMITIVE, init-value=0, base-type=BT_ORUG1_HVReleased, compu {0=Cx0_HVECUNotReleased (CM_ORUG1_HVReleased_Cx0_HVECUNotReleased), 1=Cx1_HVECUReleased (CM_ORUG1_HVReleased_Cx1_HVECUReleased)}, range raw 0..1, to SAM(timeout 5 s)  # Combination of the two status fixation state of HV to be de-energized is active and no crash has occured.
          signal ORUG1_Anforderung_HMS_XIX_ORUG01_01_XIX_E3V_K2CANFD: start 39, 3 bit, little-endian, data-type-policy=OVERRIDE, i-signal-type=PRIMITIVE, init-value=0, base-type=BT_ORUG1_Anforderung_HMS, compu {0=Cx0_keine_Anforderung (CM_ORUG1_Anforderung_HMS_Cx0_keine_Anforderung), 1=Cx1_halten (CM_ORUG1_Anforderung_HMS_Cx1_halten), 2=Cx2_parken (CM_ORUG1_Anforderung_HMS_Cx2_parken), 3=Cx3_halten_Standby (CM_ORUG1_Anforderung_HMS_Cx3_halten_Standby), 4=Cx4_anfahren (CM_ORUG1_Anforderung_HMS_Cx4_anfahren), 5=Cx5_Loesen_ueber_Rampe (CM_ORUG1_Anforderung_HMS_Cx5_Loesen_ueber_Rampe), 6=Cx6_Parken_mit_P (CM_ORUG1_Anforderung_HMS_Cx6_Parken_mit_P), 7=Cx7_HMS_uebernehmen (CM_ORUG1_Anforderung_HMS_Cx7_HMS_uebernehmen)}, range raw 0..7  # Request to gain park status to HMS
          signal ORUG1_Parken_beibehalten_HMS_XIX_ORUG01_01_XIX_E3V_K2CANFD: start 42, 2 bit, little-endian, data-type-policy=OVERRIDE, i-signal-type=PRIMITIVE, init-value=0, base-type=BT_ORUG1_Parken_beibehalten_HMS, invalid-value=Invalid_ORUG1_Parken_beibehalten_HMS_XIX_ORUG01_01_XIX_E3V_K2CANFD:3, compu {0=Cx0_Parken_nicht_beibehalten (CM_ORUG1_Parken_beibehalten_HMS_Cx0_Parken_nicht_beibehalten), 1=Cx1_Parken_beibehalten (CM_ORUG1_Parken_beibehalten_HMS_Cx1_Parken_beibehalten), 2=Cx2_Init (CM_ORUG1_Parken_beibehalten_HMS_Cx2_Init), 3=Cx3_Fehler (CM_ORUG1_Parken_beibehalten_HMS_Cx3_Fehler)}, range raw 0..3  # Request to keep park status to HMS
          signal ORUG1_Warning_XIX_ORUG01_01_XIX_E3V_K2CANFD: start 44, 2 bit, little-endian, data-type-policy=OVERRIDE, i-signal-type=PRIMITIVE, init-value=0, base-type=BT_ORUG1_Warning, compu {0=Cx0_Idle (CM_ORUG1_Warning_Cx0_Idle), 1=Cx1_Yellow (CM_ORUG1_Warning_Cx1_Yellow), 2=Cx2_Red (CM_ORUG1_Warning_Cx2_Red), 3=Cx3_Suppress (CM_ORUG1_Warning_Cx3_Suppress)}, range raw 0..3  # Suppress warning on HMI during ORU update
          signal ORUG1_HVLock_XIX_ORUG01_01_XIX_E3V_K2CANFD: start 46, 2 bit, little-endian, data-type-policy=OVERRIDE, i-signal-type=PRIMITIVE, init-value=0, base-type=BT_ORUG1_HVLock, compu {0=Cx0_Idle (CM_ORUG1_HVLock_Cx0_Idle), 1=Cx1_ActivateLock (CM_ORUG1_HVLock_Cx1_ActivateLock), 2=Cx2_ReleaseLock (CM_ORUG1_HVLock_Cx2_ReleaseLock)}, range raw 0..2  # Request to lock HV-System to be de-energized
          signal ORUG1_TargetRelease_XIX_ORUG01_01_XIX_E3V_K2CANFD: start 48, 16 bit, little-endian, data-type-policy=OVERRIDE, i-signal-type=PRIMITIVE, init-value=0, base-type=BT_ORUG1_TargetRelease, compu {phys=raw for raw 0..65535}, range phys 0..65535, raw 0..65535, to SAM(timeout 5 s)  # Diagnostic address of ECU released to be updated
          mapping SG_ORUG01_01_XIX_E3V_K2CANFD: i-signal-group=SG_ORUG01_01_XIX_E3V_K2CANFD, transfer-property=TRIGGERED-WITHOUT-REPETITION
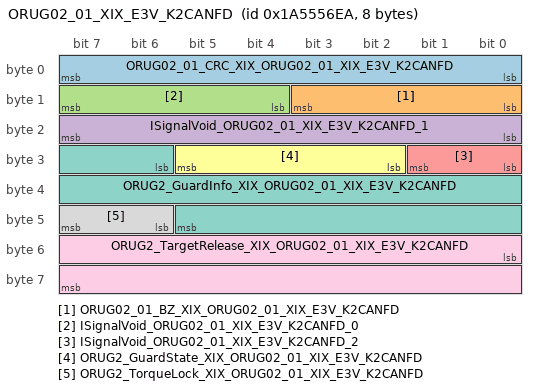
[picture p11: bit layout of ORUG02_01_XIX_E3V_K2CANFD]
      frame ORUG02_01_XIX_E3V_K2CANFD: id 0x1A5556EA, from SAM, frame-length=8, can-addressing-mode=EXTENDED, can-frame-rx-behavior=CAN-FD, can-frame-tx-behavior=CAN-FD
        pdu ORUG02_01_XIX_E3V_K2CANFD_E2E: length=8, transmission-mode-true-timing=event-controlled-timing={number-of-repetitions=0, repetition-period=0.0}, unused-bit-pattern=0  # Fuer die Botschaft ist das Cyclic-Timing 0.5 zu verwenden.
          signal ORUG02_01_CRC_XIX_ORUG02_01_XIX_E3V_K2CANFD: start 0, 8 bit, little-endian, data-type-policy=OVERRIDE, i-signal-type=PRIMITIVE, init-value=0, base-type=BT_ORUG02_01_CRC, compu {phys=raw for raw 0..255}, range phys 0..255, raw 0..255  # Für MLB: Berechnung siehe Lastenheft "Kommunikationsabsicherung für FlexRay und CAN" Ab MQB und MLBevo: Berechnung siehe Lastenheft "End-to-End Kommunikationsabsicherung" Endwerte siehe Begleitdokument "S-PDU Kennungsfolgen"
          signal ORUG02_01_BZ_XIX_ORUG02_01_XIX_E3V_K2CANFD: start 8, 4 bit, little-endian, data-type-policy=OVERRIDE, i-signal-type=PRIMITIVE, init-value=0, base-type=BT_ORUG02_01_BZ, compu {phys=raw for raw 0..15}, range phys 0..15, raw 0..15  # 4bit Botschaftszähler, wird mit jeder Sendebotschaft inkrementiert
          signal ISignalVoid_ORUG02_01_XIX_E3V_K2CANFD_0: start 12, 4 bit, little-endian, system signal SignalVoid_ORUG02_01_0, data-type-policy=OVERRIDE, i-signal-type=PRIMITIVE, base-type=BT_SignalVoid
          signal ISignalVoid_ORUG02_01_XIX_E3V_K2CANFD_1: start 16, 8 bit, little-endian, system signal SignalVoid_ORUG02_01_1, data-type-policy=OVERRIDE, i-signal-type=PRIMITIVE, base-type=BT_SignalVoid
          signal ISignalVoid_ORUG02_01_XIX_E3V_K2CANFD_2: start 24, 2 bit, little-endian, system signal SignalVoid_ORUG02_01_2, data-type-policy=OVERRIDE, i-signal-type=PRIMITIVE, base-type=BT_SignalVoid
          signal ORUG2_GuardState_XIX_ORUG02_01_XIX_E3V_K2CANFD: start 26, 4 bit, little-endian, data-type-policy=OVERRIDE, i-signal-type=PRIMITIVE, init-value=0, base-type=BT_ORUG2_GuardState, compu {0=Cx0_Idle (CM_ORUG2_GuardState_Cx0_Idle), 1=Cx1_DataErr (CM_ORUG2_GuardState_Cx1_DataErr), 2=Cx2_CountErr (CM_ORUG2_GuardState_Cx2_CountErr), 3=Cx3_Collecting (CM_ORUG2_GuardState_Cx3_Collecting), 4=Cx4_HwVerErr (CM_ORUG2_GuardState_Cx4_HwVerErr), 5=Cx5_Waiting (CM_ORUG2_GuardState_Cx5_Waiting), 6=Cx6_Ready (CM_ORUG2_GuardState_Cx6_Ready)}, range raw 0..6  # Idle = ORU guards are in Idle state DataErr = check of Metadata not succsessful CountErr = no. of ECUs differs between data and vehicle Collecting = data collection from ECUs is incomplete HwVerErr = wrong HW version found Waiting = one or more ECU needs to be updated Ready = all safety rel. ECUs reached their target SW
          signal ORUG2_GuardInfo_XIX_ORUG02_01_XIX_E3V_K2CANFD: start 30, 16 bit, little-endian, data-type-policy=OVERRIDE, i-signal-type=PRIMITIVE, init-value=0, base-type=BT_ORUG2_GuardInfo, compu {0=Cx0_Idle (CM_ORUG2_GuardInfo_Cx0_Idle), 1=Cx1_VehicleLockActive (CM_ORUG2_GuardInfo_Cx1_VehicleLockActive), 2=Cx2_HMSLocked (CM_ORUG2_GuardInfo_Cx2_HMSLocked), 4=Cx4_KLSLocked (CM_ORUG2_GuardInfo_Cx4_KLSLocked), 8=Cx8_PWRaLocked (CM_ORUG2_GuardInfo_Cx8_PWRaLocked), 16=Cx10_PWRcLocked (CM_ORUG2_GuardInfo_Cx10_PWRcLocked), 32=Cx20_HVLockActive (CM_ORUG2_GuardInfo_Cx20_HVLockActive), 64=Cx40_BCMeLocked (CM_ORUG2_GuardInfo_Cx40_BCMeLocked), 128=Cx80_OCCLocked (CM_ORUG2_GuardInfo_Cx80_OCCLocked), 256=Cx100_DCDCLocked (CM_ORUG2_GuardInfo_Cx100_DCDCLocked), 512=Cx200_WarningsSuppressed (CM_ORUG2_GuardInfo_Cx200_WarningsSuppressed), 1024=Cx400_CrashDetected (CM_ORUG2_GuardInfo_Cx400_CrashDetected), 2048=Cx800_Buffer1Blocked (CM_ORUG2_GuardInfo_Cx800_Buffer1Blocked), 4096=Cx1000_Buffer2Blocked (CM_ORUG2_GuardInfo_Cx1000_Buffer2Blocked), 8192=Cx2000_Buffer3Blocked (CM_ORUG2_GuardInfo_Cx2000_Buffer3Blocked), 16384=Cx4000_reserved (CM_ORUG2_GuardInfo_Cx4000_reserved)}, range raw 0..16384  # Released = no lock is active VehLocked = vehicle lock is active HVVehLocked = HV-System is locked
          signal ORUG2_TorqueLock_XIX_ORUG02_01_XIX_E3V_K2CANFD: start 46, 2 bit, little-endian, data-type-policy=OVERRIDE, i-signal-type=PRIMITIVE, init-value=0, base-type=BT_ORUG2_TorqueLock, compu {0=Cx0_Idle (CM_ORUG2_TorqueLock_Cx0_Idle), 1=Cx1_ActivateLock (CM_ORUG2_TorqueLock_Cx1_ActivateLock), 2=Cx2_ReleaseLock (CM_ORUG2_TorqueLock_Cx2_ReleaseLock)}, range raw 0..2  # Request HV system to prevent bringing torque on the EMotor
          signal ORUG2_TargetRelease_XIX_ORUG02_01_XIX_E3V_K2CANFD: start 48, 16 bit, little-endian, data-type-policy=OVERRIDE, i-signal-type=PRIMITIVE, init-value=0, base-type=BT_ORUG2_TargetRelease, compu {phys=raw for raw 0..65535}, range phys 0..65535, raw 0..65535  # Diagnostic address of ECU released to be updated
          mapping SG_ORUG02_01_XIX_E3V_K2CANFD: i-signal-group=SG_ORUG02_01_XIX_E3V_K2CANFD, transfer-property=TRIGGERED-WITHOUT-REPETITION
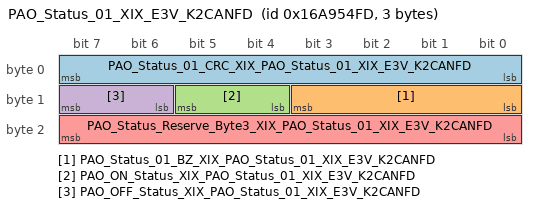
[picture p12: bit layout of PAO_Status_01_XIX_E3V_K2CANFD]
      frame PAO_Status_01_XIX_E3V_K2CANFD: id 0x16A954FD, from SAM, frame-length=3, can-addressing-mode=EXTENDED, can-frame-rx-behavior=CAN-FD, can-frame-tx-behavior=CAN-FD
        pdu PAO_Status_01_XIX_E3V_K2CANFD: length=3, transmission-mode-true-timing=cyclic-timing={time-offset=0.0, time-period=0.24}, unused-bit-pattern=0
          signal PAO_Status_01_CRC_XIX_PAO_Status_01_XIX_E3V_K2CANFD: start 0, 8 bit, little-endian, data-type-policy=OVERRIDE, i-signal-type=PRIMITIVE, base-type=BT_PAO_Status_01_CRC, compu {phys=raw for raw 0..255}, range phys 0..255, raw 0..255, transfer-property=PENDING  # Für MLB: Berechnung siehe Lastenheft "Kommunikationsabsicherung für FlexRay und CAN" Ab MQB und MLBevo: Berechnung siehe Lastenheft "End-to-End Kommunikationsabsicherung" Endwerte siehe Begleitdokument "S-PDU Kennungsfolgen"
          signal PAO_Status_01_BZ_XIX_PAO_Status_01_XIX_E3V_K2CANFD: start 8, 4 bit, little-endian, data-type-policy=OVERRIDE, i-signal-type=PRIMITIVE, base-type=BT_PAO_Status_01_BZ, compu {phys=raw for raw 0..15}, range phys 0..15, raw 0..15, transfer-property=PENDING  # 4bit Botschaftszähler, wird mit jeder Sendebotschaft inkrementiert
          signal PAO_ON_Status_XIX_PAO_Status_01_XIX_E3V_K2CANFD: start 12, 2 bit, little-endian, data-type-policy=OVERRIDE, i-signal-type=PRIMITIVE, init-value=0, base-type=BT_PAO_ON_Status, compu {0=Cx0_LED_aus (CM_PAO_ON_Status_Cx0_LED_aus), 1=Cx1_LED_an (CM_PAO_ON_Status_Cx1_LED_an), 2=Cx2_LED_blinkt (CM_PAO_ON_Status_Cx2_LED_blinkt), 3=Cx3_LED_defekt (CM_PAO_ON_Status_Cx3_LED_defekt)}, range raw 0..3, transfer-property=PENDING  # Istwert für LED "ON" in Anzeige Passenger Airbag On/Off
          signal PAO_OFF_Status_XIX_PAO_Status_01_XIX_E3V_K2CANFD: start 14, 2 bit, little-endian, data-type-policy=OVERRIDE, i-signal-type=PRIMITIVE, init-value=0, base-type=BT_PAO_OFF_Status, compu {0=Cx0_LED_aus (CM_PAO_OFF_Status_Cx0_LED_aus), 1=Cx1_LED_an (CM_PAO_OFF_Status_Cx1_LED_an), 2=Cx2_LED_blinkt (CM_PAO_OFF_Status_Cx2_LED_blinkt), 3=Cx3_LED_defekt (CM_PAO_OFF_Status_Cx3_LED_defekt)}, range raw 0..3, transfer-property=PENDING  # Istwert für LED "OFF" in Anzeige Passenger Airbag On/Off
          signal PAO_Status_Reserve_Byte3_XIX_PAO_Status_01_XIX_E3V_K2CANFD: start 16, 8 bit, little-endian, data-type-policy=OVERRIDE, i-signal-type=PRIMITIVE, init-value=0, base-type=BT_PAO_Status_Reserve_Byte3, transfer-property=PENDING  # Zweck: Befüllen der reservierten Bitpositionen mit 0 (wg. LIN-Teilnehmer)
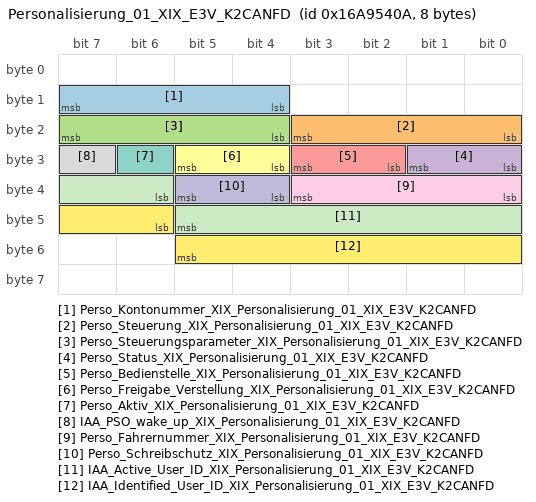
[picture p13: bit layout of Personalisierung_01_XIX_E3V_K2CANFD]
      frame Personalisierung_01_XIX_E3V_K2CANFD: id 0x16A9540A, to SAM, frame-length=8, can-addressing-mode=EXTENDED, can-frame-rx-behavior=CAN-FD, can-frame-tx-behavior=CAN-FD
        pdu Personalisierung_01_XIX_E3V_K2CANFD: length=8, minimum-delay=0.05, transmission-mode-true-timing={cyclic-timing={time-offset=0.0, time-period=1.0}, event-controlled-timing={number-of-repetitions=3, repetition-period=0.2}}, unused-bit-pattern=0
          signal Perso_Kontonummer_XIX_Personalisierung_01_XIX_E3V_K2CANFD: start 12, 4 bit, little-endian, data-type-policy=OVERRIDE, i-signal-type=PRIMITIVE, init-value=0, base-type=BT_Perso_Kontonummer, compu {0=Cx0_kein_Benutzerkonto (CM_Perso_Kontonummer_Cx0_kein_Benutzerkonto), 1=Cx1_Benutzerkonto_1 (CM_Perso_Kontonummer_Cx1_Benutzerkonto_1), 2=Cx2_Benutzerkonto_2 (CM_Perso_Kontonummer_Cx2_Benutzerkonto_2), 3=Cx3_Benutzerkonto_3 (CM_Perso_Kontonummer_Cx3_Benutzerkonto_3), 4=Cx4_Benutzerkonto_4 (CM_Perso_Kontonummer_Cx4_Benutzerkonto_4), 5=Cx5_Benutzerkonto_5 (CM_Perso_Kontonummer_Cx5_Benutzerkonto_5), 6=Cx6_Benutzerkonto_6 (CM_Perso_Kontonummer_Cx6_Benutzerkonto_6), 7=Cx7_Benutzerkonto_7 (CM_Perso_Kontonummer_Cx7_Benutzerkonto_7)}, range raw 0..7, transfer-property=TRIGGERED-ON-CHANGE, to SAM(timeout 5 s)  # Signal gibt die jewels aktuelle Kontonummer für die Personalisierung an. Nicht für AU736 und AU48x.
          signal Perso_Steuerung_XIX_Personalisierung_01_XIX_E3V_K2CANFD: start 16, 4 bit, little-endian, data-type-policy=OVERRIDE, i-signal-type=PRIMITIVE, init-value=0, base-type=BT_Perso_Steuerung, compu {0=Cx0_keine_Steuerung (CM_Perso_Steuerung_Cx0_keine_Steuerung), 1=Cx1_Reset_alle_Konten (CM_Perso_Steuerung_Cx1_Reset_alle_Konten), 2=Cx2_Reset_aktives_Konto (CM_Perso_Steuerung_Cx2_Reset_aktives_Konto), 3=Cx3_Kopiere_aktives_Konto_nach (CM_Perso_Steuerung_Cx3_Kopiere_aktives_Konto_nach), 4=Cx4_Wiederherstellen_aktives_Konto (CM_Perso_Steuerung_Cx4_Wiederherstellen_aktives_Konto), 5=Cx5_Aktivieren_aktives_Konto (CM_Perso_Steuerung_Cx5_Aktivieren_aktives_Konto), 6=Cx6_Reset_Konto (CM_Perso_Steuerung_Cx6_Reset_Konto), 7=Cx7_Reset_alle_Fahrer (CM_Perso_Steuerung_Cx7_Reset_alle_Fahrer), 8=Cx8_Reset_aktiver_Fahrer (CM_Perso_Steuerung_Cx8_Reset_aktiver_Fahrer), 9=Cx9_Reset_Fahrer (CM_Perso_Steuerung_Cx9_Reset_Fahrer)}, range raw 0..9, transfer-property=TRIGGERED-ON-CHANGE, to SAM(timeout 5 s)  # Signal gibt einen Steuerungsbefehl an die Funktionsteilnehmer der Personalisierung. Nicht für AU736 und AU49x.
          signal Perso_Steuerungsparameter_XIX_Personalisierung_01_XIX_E3V_K2CANFD: start 20, 4 bit, little-endian, data-type-policy=OVERRIDE, i-signal-type=PRIMITIVE, init-value=0, base-type=BT_Perso_Steuerungsparameter, compu {0=Cx0_kein_Parameter (CM_Perso_Steuerungsparameter_Cx0_kein_Parameter), 1=Cx1_Benutzerkonto_1 (CM_Perso_Steuerungsparameter_Cx1_Benutzerkonto_1), 2=Cx2_Benutzerkonto_2 (CM_Perso_Steuerungsparameter_Cx2_Benutzerkonto_2), 3=Cx3_Benutzerkonto_3 (CM_Perso_Steuerungsparameter_Cx3_Benutzerkonto_3), 4=Cx4_Benutzerkonto_4 (CM_Perso_Steuerungsparameter_Cx4_Benutzerkonto_4), 5=Cx5_Benutzerkonto_5 (CM_Perso_Steuerungsparameter_Cx5_Benutzerkonto_5), 6=Cx6_Benutzerkonto_6 (CM_Perso_Steuerungsparameter_Cx6_Benutzerkonto_6), 7=Cx7_Benutzerkonto_7 (CM_Perso_Steuerungsparameter_Cx7_Benutzerkonto_7)}, range raw 0..7, transfer-property=TRIGGERED-ON-CHANGE, to SAM(timeout 5 s)  # Signal gibt einen Parameter zum Steuerungsbefehl (Signal Perso_Steuerung) für die Personalisierung an. Nicht für AU736 und AU49x.
          signal Perso_Status_XIX_Personalisierung_01_XIX_E3V_K2CANFD: start 24, 2 bit, little-endian, data-type-policy=OVERRIDE, i-signal-type=PRIMITIVE, init-value=0, base-type=BT_Perso_Status, compu {0=Cx0_deaktiviert (CM_Perso_Status_Cx0_deaktiviert), 1=Cx1_PSO_1x_aktiviert (CM_Perso_Status_Cx1_PSO_1x_aktiviert), 2=Cx2_PSO_2x_aktiviert (CM_Perso_Status_Cx2_PSO_2x_aktiviert)}, range raw 0..2, transfer-property=TRIGGERED-WITHOUT-REPETITION, to SAM(timeout 5 s)  # Codierstatus der Personalisierung Nicht für AU736 und AU49x.
          signal Perso_Bedienstelle_XIX_Personalisierung_01_XIX_E3V_K2CANFD: start 26, 2 bit, little-endian, data-type-policy=OVERRIDE, i-signal-type=PRIMITIVE, init-value=0, base-type=BT_Perso_Bedienstelle, compu {0=Cx0_Init (CM_Perso_Bedienstelle_Cx0_Init), 1=Cx1_Kombiinstrument (CM_Perso_Bedienstelle_Cx1_Kombiinstrument), 2=Cx2_ABT (CM_Perso_Bedienstelle_Cx2_ABT)}, range raw 0..2, transfer-property=TRIGGERED-ON-CHANGE  # Signal zeigt an, über welche Bedienstelle die Umschaltung des Benutzerkontos gestartet wurden.
          signal Perso_Freigabe_Verstellung_XIX_Personalisierung_01_XIX_E3V_K2CANFD: start 28, 2 bit, little-endian, data-type-policy=OVERRIDE, i-signal-type=PRIMITIVE, init-value=0, base-type=BT_Perso_Freigabe_Verstellung, compu {0=Cx0_Init (CM_Perso_Freigabe_Verstellung_Cx0_Init), 1=Cx1_freigegeben (CM_Perso_Freigabe_Verstellung_Cx1_freigegeben)}, range raw 0..1, transfer-property=TRIGGERED-ON-CHANGE  # Signal zeigt an, ob die Ergonomiefunktionen nach Umschaltung des Benutzerkontos verfahren dürfen.
          signal Perso_Aktiv_XIX_Personalisierung_01_XIX_E3V_K2CANFD: start 30, 1 bit, little-endian, data-type-policy=OVERRIDE, i-signal-type=PRIMITIVE, init-value=0, base-type=BT_Perso_Aktiv, compu {0=Cx0_deaktiviert (CM_Perso_Aktiv_Cx0_deaktiviert), 1=Cx1_aktiviert (CM_Perso_Aktiv_Cx1_aktiviert)}, range raw 0..1, transfer-property=TRIGGERED-ON-CHANGE  # Status Personalisierung für den Fahrer aktiviert/ deaktiviert (via HMI)
          signal IAA_PSO_wake_up_XIX_Personalisierung_01_XIX_E3V_K2CANFD: start 31, 1 bit, little-endian, data-type-policy=OVERRIDE, i-signal-type=PRIMITIVE, init-value=0, base-type=BT_IAA_PSO_wake_up, compu {0=Cx0_wake_up_inactive (CM_IAA_PSO_wake_up_Cx0_wake_up_inactive), 1=Cx1_wake_up_active (CM_IAA_PSO_wake_up_Cx1_wake_up_active)}, range raw 0..1, transfer-property=TRIGGERED-ON-CHANGE  # Signal zum Wake_up der IAA und PSO Komponenten im Kombi und in der OCU
          signal Perso_Fahrernummer_XIX_Personalisierung_01_XIX_E3V_K2CANFD: start 32, 4 bit, little-endian, data-type-policy=OVERRIDE, i-signal-type=PRIMITIVE, init-value=0, base-type=BT_Perso_Fahrernummer, compu {0=Cx0_kein_Fahrer (CM_Perso_Fahrernummer_Cx0_kein_Fahrer), 1=Cx1_Fahrer_1 (CM_Perso_Fahrernummer_Cx1_Fahrer_1), 2=Cx2_Fahrer_2 (CM_Perso_Fahrernummer_Cx2_Fahrer_2), 3=Cx3_Fahrer_3 (CM_Perso_Fahrernummer_Cx3_Fahrer_3), 4=Cx4_Fahrer_4 (CM_Perso_Fahrernummer_Cx4_Fahrer_4), 5=Cx5_Fahrer_5 (CM_Perso_Fahrernummer_Cx5_Fahrer_5), 6=Cx6_Fahrer_6 (CM_Perso_Fahrernummer_Cx6_Fahrer_6), 7=Cx7_Fahrer_7 (CM_Perso_Fahrernummer_Cx7_Fahrer_7)}, range raw 0..7, transfer-property=TRIGGERED-ON-CHANGE  # Signal gibt die jewels aktuelle Nummer des Fahrers für die Personalisierung an. Nicht für AU736 und AU48x.
          signal Perso_Schreibschutz_XIX_Personalisierung_01_XIX_E3V_K2CANFD: start 36, 2 bit, little-endian, data-type-policy=OVERRIDE, i-signal-type=PRIMITIVE, init-value=0, base-type=BT_Perso_Schreibschutz, compu {0=Cx0_Schreibschutz_deaktiviert (CM_Perso_Schreibschutz_Cx0_Schreibschutz_deaktiviert), 1=Cx1_Schreibschutz_aktiviert (CM_Perso_Schreibschutz_Cx1_Schreibschutz_aktiviert)}, range raw 0..1, transfer-property=TRIGGERED-ON-CHANGE  # Signal zeigt an, ob der Schreibschutz der Personalisierung aktiv ist.
          signal IAA_Active_User_ID_XIX_Personalisierung_01_XIX_E3V_K2CANFD: start 38, 8 bit, little-endian, data-type-policy=OVERRIDE, i-signal-type=PRIMITIVE, init-value=0, base-type=BT_IAA_Active_User_ID, compu {phys=raw for raw 0..255; unit Unit_None}, range phys 0..255 Unit_None, raw 0..255, unit=Unit_None, transfer-property=TRIGGERED-ON-CHANGE  # Signal gibt die IAA Nutzer ID des aktiven IAA Nutzers an.
          signal IAA_Identified_User_ID_XIX_Personalisierung_01_XIX_E3V_K2CANFD: start 46, 8 bit, little-endian, data-type-policy=OVERRIDE, i-signal-type=PRIMITIVE, init-value=0, base-type=BT_IAA_Identified_User_ID, compu {phys=raw for raw 0..255; unit Unit_None}, range phys 0..255 Unit_None, raw 0..255, unit=Unit_None, transfer-property=TRIGGERED-ON-CHANGE  # Signal gibt die IAA Nutzer ID des vom BCM identifizierten IAA Nutzers an
      frame PreCrash_02_XIX_E3V_K2CANFD: id 0x13F, to SAM, frame-length=8, can-addressing-mode=STANDARD, can-frame-rx-behavior=CAN-FD, can-frame-tx-behavior=CAN-FD
        pdu PreCrash_02_XIX_E3V_K2CANFD: length=8, minimum-delay=0.02, transmission-mode-true-timing={cyclic-timing={time-offset=0.0, time-period=0.2}, event-controlled-timing={number-of-repetitions=0, repetition-period=0.0}}, unused-bit-pattern=0
          signal PreCrash_Charisma_FahrPr_XIX_PreCrash_02_XIX_E3V_K2CANFD: start 12, 4 bit, little-endian, data-type-policy=OVERRIDE, i-signal-type=PRIMITIVE, init-value=0, base-type=BT_PreCrash_Charisma_FahrPr, compu {0=Cx0_keine_Funktion (CM_PreCrash_Charisma_FahrPr_Cx0_keine_Funktion), 1=Cx1_Programm_1 (CM_PreCrash_Charisma_FahrPr_Cx1_Programm_1), 2=Cx2_Programm_2 (CM_PreCrash_Charisma_FahrPr_Cx2_Programm_2), 3=Cx3_Programm_3 (CM_PreCrash_Charisma_FahrPr_Cx3_Programm_3), 4=Cx4_Programm_4 (CM_PreCrash_Charisma_FahrPr_Cx4_Programm_4), 5=Cx5_Programm_5 (CM_PreCrash_Charisma_FahrPr_Cx5_Programm_5), 6=Cx6_Programm_6 (CM_PreCrash_Charisma_FahrPr_Cx6_Programm_6), 7=Cx7_Programm_7 (CM_PreCrash_Charisma_FahrPr_Cx7_Programm_7), 8=Cx8_Programm_8 (CM_PreCrash_Charisma_FahrPr_Cx8_Programm_8), 9=Cx9_Programm_9 (CM_PreCrash_Charisma_FahrPr_Cx9_Programm_9), 10=Cxa_Programm_10 (CM_PreCrash_Charisma_FahrPr_Cxa_Programm_10), 11=Cxb_Programm_11 (CM_PreCrash_Charisma_FahrPr_Cxb_Programm_11), 12=Cxc_Programm_12 (CM_PreCrash_Charisma_FahrPr_Cxc_Programm_12), 13=Cxd_Programm_13 (CM_PreCrash_Charisma_FahrPr_Cxd_Programm_13), 14=Cxe_Programm_14 (CM_PreCrash_Charisma_FahrPr_Cxe_Programm_14), 15=Cxf_Programm_15 (CM_PreCrash_Charisma_FahrPr_Cxf_Programm_15)}, range raw 0..15, transfer-property=PENDING  # Aktuell eingestelltes Fahrprogramm der Funktion PreCrash
          signal PreCrash_Charisma_Status_XIX_PreCrash_02_XIX_E3V_K2CANFD: start 16, 2 bit, little-endian, data-type-policy=OVERRIDE, i-signal-type=PRIMITIVE, init-value=0, base-type=BT_PreCrash_Charisma_Status, compu {0=Cx0_Init (CM_PreCrash_Charisma_Status_Cx0_Init), 1=Cx1_verfuegbar (CM_PreCrash_Charisma_Status_Cx1_verfuegbar), 2=Cx2_nicht_verfuegbar (CM_PreCrash_Charisma_Status_Cx2_nicht_verfuegbar), 3=Cx3_asynchron_durch_Fahrerwunsch (CM_PreCrash_Charisma_Status_Cx3_asynchron_durch_Fahrerwunsch)}, range raw 0..3, transfer-property=PENDING  # Verfügbarkeit der Funktion PreCrash für die Ansteuerung durch den Charisma_Koordinator
          signal PreCrash_Schiebedach_schliessen_XIX_PreCrash_02_XIX_E3V_K2CANFD: start 18, 1 bit, little-endian, data-type-policy=OVERRIDE, i-signal-type=PRIMITIVE, init-value=0, base-type=BT_PreCrash_Schiebedach_schliessen, compu {0=Cx0_keine_Schliessung (CM_PreCrash_Schiebedach_schliessen_Cx0_keine_Schliessung), 1=Cx1_Schliessung_angefordert (CM_PreCrash_Schiebedach_schliessen_Cx1_Schliessung_angefordert)}, range raw 0..1, transfer-property=TRIGGERED-ON-CHANGE-WITHOUT-REPETITION  # Anforderung Schiebedach schließen durch die Funktion PreCrash
          signal PreCrash_Fenster_schliessen_XIX_PreCrash_02_XIX_E3V_K2CANFD: start 19, 1 bit, little-endian, data-type-policy=OVERRIDE, i-signal-type=PRIMITIVE, init-value=0, base-type=BT_PreCrash_Fenster_schliessen, compu {0=Cx0_keine_Schliessung (CM_PreCrash_Fenster_schliessen_Cx0_keine_Schliessung), 1=Cx1_Schliessung_angefordert (CM_PreCrash_Fenster_schliessen_Cx1_Schliessung_angefordert)}, range raw 0..1, transfer-property=TRIGGERED-ON-CHANGE-WITHOUT-REPETITION, to SAM(timeout 2 s)  # Anforderung Seitenscheiben schließen durch die Funktion PreCrash
          signal PreCrash_Blinken_XIX_PreCrash_02_XIX_E3V_K2CANFD: start 20, 3 bit, little-endian, data-type-policy=OVERRIDE, i-signal-type=PRIMITIVE, init-value=0, base-type=BT_PreCrash_Blinken, compu {0=Cx0_keine_Blinkanforderung (CM_PreCrash_Blinken_Cx0_keine_Blinkanforderung), 1=Cx1_Warnblinken (CM_PreCrash_Blinken_Cx1_Warnblinken), 2=Cx2_RECAS_Blinken (CM_PreCrash_Blinken_Cx2_RECAS_Blinken), 3=Cx3_Notbremsblinken (CM_PreCrash_Blinken_Cx3_Notbremsblinken)}, range raw 0..3, transfer-property=TRIGGERED-ON-CHANGE-WITHOUT-REPETITION  # Safety Computer übermittelt Blinkverhalten bei einer PreCrash-Auslösung an den BCM2
          signal SC_PreSense_FCWP_XIX_PreCrash_02_XIX_E3V_K2CANFD: start 23, 1 bit, little-endian, data-type-policy=OVERRIDE, i-signal-type=PRIMITIVE, init-value=0, base-type=BT_SC_PreSense_FCWP, compu {0=Cx0_Warnung_gilt_fuer_Objekte (CM_SC_PreSense_FCWP_Cx0_Warnung_gilt_fuer_Objekte), 1=Cx1_Warnung_gitl_fuer_Fussgaenger (CM_SC_PreSense_FCWP_Cx1_Warnung_gitl_fuer_Fussgaenger)}, range raw 0..1, transfer-property=TRIGGERED-ON-CHANGE-WITHOUT-REPETITION  # Mitteilung an das NightVision, auf welche Art von Objekt eine Warnung angefordert wird
          signal PreCrash_Tueren_Verriegeln_XIX_PreCrash_02_XIX_E3V_K2CANFD: start 24, 1 bit, little-endian, data-type-policy=OVERRIDE, i-signal-type=PRIMITIVE, init-value=0, base-type=BT_PreCrash_Tueren_Verriegeln, compu {0=Cx0_keine_Anforderung (CM_PreCrash_Tueren_Verriegeln_Cx0_keine_Anforderung), 1=Cx1_Tueren_Verriegeln (CM_PreCrash_Tueren_Verriegeln_Cx1_Tueren_Verriegeln)}, range raw 0..1, transfer-property=TRIGGERED-ON-CHANGE-WITHOUT-REPETITION  # Anforderung Türen Verriegeln durch die Funktion PreCrash
          signal PreCrash_FS_Laengsverstellung_XIX_PreCrash_02_XIX_E3V_K2CANFD: start 25, 1 bit, little-endian, data-type-policy=OVERRIDE, i-signal-type=PRIMITIVE, init-value=0, base-type=BT_PreCrash_FS_Laengsverstellung, compu {0=Cx0_nicht_angefordert (CM_PreCrash_FS_Laengsverstellung_Cx0_nicht_angefordert), 1=Cx1_angefordert (CM_PreCrash_FS_Laengsverstellung_Cx1_angefordert)}, range raw 0..1, transfer-property=TRIGGERED-ON-CHANGE-WITHOUT-REPETITION  # Ansteuerung der Laengsverstellung des Fahrersitzes durch die PreCrash-Funktionen
          signal PreCrash_Anforderung_AFR_XIX_PreCrash_02_XIX_E3V_K2CANFD: start 26, 3 bit, little-endian, data-type-policy=OVERRIDE, i-signal-type=PRIMITIVE, init-value=7, base-type=BT_PreCrash_Anforderung_AFR, compu {0=Cx0_keine_Anforderung (CM_PreCrash_Anforderung_AFR_Cx0_keine_Anforderung), 1=Cx1_linke_Seite (CM_PreCrash_Anforderung_AFR_Cx1_linke_Seite), 2=Cx2_rechte_Seite (CM_PreCrash_Anforderung_AFR_Cx2_rechte_Seite), 3=Cx3_Vorderachse (CM_PreCrash_Anforderung_AFR_Cx3_Vorderachse), 4=Cx4_Hinterachse (CM_PreCrash_Anforderung_AFR_Cx4_Hinterachse), 5=Cx5_Vorwarnung (CM_PreCrash_Anforderung_AFR_Cx5_Vorwarnung), 7=Cx7_Init (CM_PreCrash_Anforderung_AFR_Cx7_Init)}, range raw 0..7, transfer-property=TRIGGERED-ON-CHANGE-WITHOUT-REPETITION  # Anforderungen der Funktion PrecrashSeite an Fahrwerksregelung
          signal SC_PreCrash_LED_XIX_PreCrash_02_XIX_E3V_K2CANFD: start 29, 2 bit, little-endian, data-type-policy=OVERRIDE, i-signal-type=PRIMITIVE, init-value=0, base-type=BT_SC_PreCrash_LED, compu {0=Cx0_keine_Anzeige (CM_SC_PreCrash_LED_Cx0_keine_Anzeige), 1=Cx1_Stufe_1_glimmen (CM_SC_PreCrash_LED_Cx1_Stufe_1_glimmen), 2=Cx2_Stufe_2_leuchten (CM_SC_PreCrash_LED_Cx2_Stufe_2_leuchten), 3=Cx3_Stufe_3_blinken (CM_SC_PreCrash_LED_Cx3_Stufe_3_blinken)}, range raw 0..3, transfer-property=TRIGGERED-ON-CHANGE-WITHOUT-REPETITION  # Ansteuerung LED-Leiste im Kombi durch SC
          signal PreCrash_FS_Pneumatik_ansteuern_XIX_PreCrash_02_XIX_E3V_K2CANFD: start 31, 1 bit, little-endian, data-type-policy=OVERRIDE, i-signal-type=PRIMITIVE, init-value=0, base-type=BT_PreCrash_FS_Pneumatik_ansteuern, compu {0=Cx0_keine_Anforderung (CM_PreCrash_FS_Pneumatik_ansteuern_Cx0_keine_Anforderung), 1=Cx1_Pneumatik_ansteuern (CM_PreCrash_FS_Pneumatik_ansteuern_Cx1_Pneumatik_ansteuern)}, range raw 0..1, transfer-property=TRIGGERED-ON-CHANGE-WITHOUT-REPETITION, to SAM(timeout 2 s)  # Ansteuerung des Fahrersitzes durch die PreCrash-Funktionen
          signal PreCrash_BFS_Pneumatik_ansteuern_XIX_PreCrash_02_XIX_E3V_K2CANFD: start 32, 1 bit, little-endian, data-type-policy=OVERRIDE, i-signal-type=PRIMITIVE, init-value=0, base-type=BT_PreCrash_BFS_Pneumatik_ansteuern, compu {0=Cx0_keine_Anforderung (CM_PreCrash_BFS_Pneumatik_ansteuern_Cx0_keine_Anforderung), 1=Cx1_Pneumatik_ansteuern (CM_PreCrash_BFS_Pneumatik_ansteuern_Cx1_Pneumatik_ansteuern)}, range raw 0..1, transfer-property=TRIGGERED-ON-CHANGE-WITHOUT-REPETITION, to SAM(timeout 2 s)  # Ansteuerung des Beifahrersitzes durch die PreCrash-Funktionen
          signal PreCrash_Fo_Pneumatik_ansteuern_XIX_PreCrash_02_XIX_E3V_K2CANFD: start 33, 1 bit, little-endian, data-type-policy=OVERRIDE, i-signal-type=PRIMITIVE, init-value=0, base-type=BT_PreCrash_Fo_Pneumatik_ansteuern, compu {0=Cx0_keine_Anforderung (CM_PreCrash_Fo_Pneumatik_ansteuern_Cx0_keine_Anforderung), 1=Cx1_Pneumatik_ansteuern (CM_PreCrash_Fo_Pneumatik_ansteuern_Cx1_Pneumatik_ansteuern)}, range raw 0..1, transfer-property=TRIGGERED-ON-CHANGE-WITHOUT-REPETITION  # Ansteuerung der Fondsitze durch die PreCrash-Funktionen
          signal PreCrash_FS_Sitzlehne_verfahren_XIX_PreCrash_02_XIX_E3V_K2CANFD: start 34, 3 bit, little-endian, data-type-policy=OVERRIDE, i-signal-type=PRIMITIVE, init-value=0, base-type=BT_PreCrash_FS_Sitzlehne_verfahren, compu {0=Cx0_keine_Anforderung (CM_PreCrash_FS_Sitzlehne_verfahren_Cx0_keine_Anforderung), 1=Cx1_reserviert (CM_PreCrash_FS_Sitzlehne_verfahren_Cx1_reserviert), 2=Cx2_reserviert (CM_PreCrash_FS_Sitzlehne_verfahren_Cx2_reserviert), 3=Cx3_Sitzlehnenkopf_in_pos_xRichtung_verfahrenvor (CM_PreCrash_FS_Sitzlehne_verfahren_Cx3_Sitzlehnenkopf_in_pos_xRichtung_verfahrenvor), 4=Cx4_Sitzlehnenkopf_in_neg_xRichtung_verfahrenzurueck (CM_PreCrash_FS_Sitzlehne_verfahren_Cx4_Sitzlehnenkopf_in_neg_xRichtung_verfahrenzurueck), 6=Cx6_reserviert (CM_PreCrash_FS_Sitzlehne_verfahren_Cx6_reserviert), 7=Cx7_Lehnenkopfverstellung_ansteuern (CM_PreCrash_FS_Sitzlehne_verfahren_Cx7_Lehnenkopfverstellung_ansteuern)}, range raw 0..7, transfer-property=TRIGGERED-ON-CHANGE-WITHOUT-REPETITION  # Ansteuerung des Fahrersitzes durch die PreCrash-Funktionen Wert 0x06 und 0x07 für vereinfachte Ansteuerung Sitzlehne
          signal PreCrash_BFS_Sitzlehne_verfahren_XIX_PreCrash_02_XIX_E3V_K2CANFD: start 37, 3 bit, little-endian, data-type-policy=OVERRIDE, i-signal-type=PRIMITIVE, init-value=0, base-type=BT_PreCrash_BFS_Sitzlehne_verfahren, compu {0=Cx0_keine_Anforderung (CM_PreCrash_BFS_Sitzlehne_verfahren_Cx0_keine_Anforderung), 1=Cx1_reserviert (CM_PreCrash_BFS_Sitzlehne_verfahren_Cx1_reserviert), 2=Cx2_reserviert (CM_PreCrash_BFS_Sitzlehne_verfahren_Cx2_reserviert), 3=Cx3_Sitzlehnenkopf_in_pos_xRichtung_verfahrenvor (CM_PreCrash_BFS_Sitzlehne_verfahren_Cx3_Sitzlehnenkopf_in_pos_xRichtung_verfahrenvor), 4=Cx4_Sitzlehnenkopf_in_neg_xRichtung_verfahrenzurueck (CM_PreCrash_BFS_Sitzlehne_verfahren_Cx4_Sitzlehnenkopf_in_neg_xRichtung_verfahrenzurueck), 6=Cx6_reserviert (CM_PreCrash_BFS_Sitzlehne_verfahren_Cx6_reserviert), 7=Cx7_Lehnenkopfverstellung_ansteuern (CM_PreCrash_BFS_Sitzlehne_verfahren_Cx7_Lehnenkopfverstellung_ansteuern)}, range raw 0..7, transfer-property=TRIGGERED-ON-CHANGE-WITHOUT-REPETITION  # Ansteuerung des Beifahrersitzes durch die PreCrash-Funktionen Wert 0x06 und 0x07 für vereinfachte Ansteuerung Sitzlehne
          signal PreCrash_Fo_Sitzlehne_verfahren_XIX_PreCrash_02_XIX_E3V_K2CANFD: start 40, 3 bit, little-endian, data-type-policy=OVERRIDE, i-signal-type=PRIMITIVE, init-value=0, base-type=BT_PreCrash_Fo_Sitzlehne_verfahren, compu {0=Cx0_keine_Anforderung (CM_PreCrash_Fo_Sitzlehne_verfahren_Cx0_keine_Anforderung), 1=Cx1_reserviert (CM_PreCrash_Fo_Sitzlehne_verfahren_Cx1_reserviert), 2=Cx2_reserviert (CM_PreCrash_Fo_Sitzlehne_verfahren_Cx2_reserviert), 3=Cx3_Sitzlehnenkopf_in_pos_xRichtung_verfahrenvor (CM_PreCrash_Fo_Sitzlehne_verfahren_Cx3_Sitzlehnenkopf_in_pos_xRichtung_verfahrenvor), 4=Cx4_Sitzlehnenkopf_in_neg_xRichtung_verfahrenzurueck (CM_PreCrash_Fo_Sitzlehne_verfahren_Cx4_Sitzlehnenkopf_in_neg_xRichtung_verfahrenzurueck)}, range raw 0..4, transfer-property=TRIGGERED-ON-CHANGE-WITHOUT-REPETITION  # Ansteuerung des Fondsitzes durch die PreCrash-Funktionen
          signal PreCrash_FS_KSV_verfahren_XIX_PreCrash_02_XIX_E3V_K2CANFD: start 43, 4 bit, little-endian, data-type-policy=OVERRIDE, i-signal-type=PRIMITIVE, init-value=0, base-type=BT_PreCrash_FS_KSV_verfahren, compu {0=Cx0_keine_Anforderung (CM_PreCrash_FS_KSV_verfahren_Cx0_keine_Anforderung), 1=Cx1_in_pos_xRichtung_verfahren (CM_PreCrash_FS_KSV_verfahren_Cx1_in_pos_xRichtung_verfahren), 2=Cx2_in_neg_xRichung_verfahren (CM_PreCrash_FS_KSV_verfahren_Cx2_in_neg_xRichung_verfahren), 3=Cx3_in_pos_zRichtung_verfahren (CM_PreCrash_FS_KSV_verfahren_Cx3_in_pos_zRichtung_verfahren), 4=Cx4_in_neg_zRichtung_verfahren (CM_PreCrash_FS_KSV_verfahren_Cx4_in_neg_zRichtung_verfahren), 5=Cx5_in_pos_xRichtung_und_neg_zRichtung_verfahren (CM_PreCrash_FS_KSV_verfahren_Cx5_in_pos_xRichtung_und_neg_zRichtung_verfahren), 6=Cx6_in_pos_x_Richtung_und_pos_zRichtung_verfahren (CM_PreCrash_FS_KSV_verfahren_Cx6_in_pos_x_Richtung_und_pos_zRichtung_verfahren), 7=Cx7_in_neg_xRichtung_und_neg_zRichtung_verfahren (CM_PreCrash_FS_KSV_verfahren_Cx7_in_neg_xRichtung_und_neg_zRichtung_verfahren), 8=Cx8_in_neg_xRichtung_und_pos_zRichtung_verfahren (CM_PreCrash_FS_KSV_verfahren_Cx8_in_neg_xRichtung_und_pos_zRichtung_verfahren), 9=Cx9_Kopfstuetze_ansteuern (CM_PreCrash_FS_KSV_verfahren_Cx9_Kopfstuetze_ansteuern)}, range raw 0..9, transfer-property=TRIGGERED-ON-CHANGE-WITHOUT-REPETITION  # Ansteuerung der Kopfstuetze Fahrerseite durch die PreCrash-Funktionen Signalwert 0x09 für vereinfachte Ansteuerung mit Logik im Sitz-SG (MQB37W)
          signal PreCrash_BFS_KSV_verfahren_XIX_PreCrash_02_XIX_E3V_K2CANFD: start 47, 4 bit, little-endian, data-type-policy=OVERRIDE, i-signal-type=PRIMITIVE, init-value=0, base-type=BT_PreCrash_BFS_KSV_verfahren, compu {0=Cx0_keine_Anforderung (CM_PreCrash_BFS_KSV_verfahren_Cx0_keine_Anforderung), 1=Cx1_in_pos_xRichtung_verfahren (CM_PreCrash_BFS_KSV_verfahren_Cx1_in_pos_xRichtung_verfahren), 2=Cx2_in_neg_xRichung_verfahren (CM_PreCrash_BFS_KSV_verfahren_Cx2_in_neg_xRichung_verfahren), 3=Cx3_in_pos_zRichtung_verfahren (CM_PreCrash_BFS_KSV_verfahren_Cx3_in_pos_zRichtung_verfahren), 4=Cx4_in_neg_zRichtung_verfahren (CM_PreCrash_BFS_KSV_verfahren_Cx4_in_neg_zRichtung_verfahren), 5=Cx5_in_pos_xRichtung_und_neg_zRichtung_verfahren (CM_PreCrash_BFS_KSV_verfahren_Cx5_in_pos_xRichtung_und_neg_zRichtung_verfahren), 6=Cx6_in_pos_x_Richtung_und_pos_zRichtung_verfahren (CM_PreCrash_BFS_KSV_verfahren_Cx6_in_pos_x_Richtung_und_pos_zRichtung_verfahren), 7=Cx7_in_neg_xRichtung_und_neg_zRichtung_verfahren (CM_PreCrash_BFS_KSV_verfahren_Cx7_in_neg_xRichtung_und_neg_zRichtung_verfahren), 8=Cx8_in_neg_xRichtung_und_pos_zRichtung_verfahren (CM_PreCrash_BFS_KSV_verfahren_Cx8_in_neg_xRichtung_und_pos_zRichtung_verfahren), 9=Cx9_Kopfstuetze_ansteuern (CM_PreCrash_BFS_KSV_verfahren_Cx9_Kopfstuetze_ansteuern)}, range raw 0..9, transfer-property=TRIGGERED-ON-CHANGE-WITHOUT-REPETITION  # Ansteuerung der Kopfstuetze Beifahrerseite durch die Funktion PreCrash Signalwert 0x09 für vereinfachte Ansteuerung mit Logik im Sitz-SG (MQB37W)
          signal PreCrash_Fo_KSV_verfahren_XIX_PreCrash_02_XIX_E3V_K2CANFD: start 51, 4 bit, little-endian, data-type-policy=OVERRIDE, i-signal-type=PRIMITIVE, init-value=0, base-type=BT_PreCrash_Fo_KSV_verfahren, compu {0=Cx0_keine_Anforderung (CM_PreCrash_Fo_KSV_verfahren_Cx0_keine_Anforderung), 1=Cx1_in_pos_xRichtung_verfahren (CM_PreCrash_Fo_KSV_verfahren_Cx1_in_pos_xRichtung_verfahren), 2=Cx2_in_neg_xRichung_verfahren (CM_PreCrash_Fo_KSV_verfahren_Cx2_in_neg_xRichung_verfahren), 3=Cx3_in_pos_zRichtung_verfahren (CM_PreCrash_Fo_KSV_verfahren_Cx3_in_pos_zRichtung_verfahren), 4=Cx4_in_neg_zRichtung_verfahren (CM_PreCrash_Fo_KSV_verfahren_Cx4_in_neg_zRichtung_verfahren), 5=Cx5_in_pos_xRichtung_und_neg_zRichtung_verfahren (CM_PreCrash_Fo_KSV_verfahren_Cx5_in_pos_xRichtung_und_neg_zRichtung_verfahren), 6=Cx6_in_pos_x_Richtung_und_pos_zRichtung_verfahren (CM_PreCrash_Fo_KSV_verfahren_Cx6_in_pos_x_Richtung_und_pos_zRichtung_verfahren), 7=Cx7_in_neg_xRichtung_und_neg_zRichtung_verfahren (CM_PreCrash_Fo_KSV_verfahren_Cx7_in_neg_xRichtung_und_neg_zRichtung_verfahren), 8=Cx8_in_neg_xRichtung_und_pos_zRichtung_verfahren (CM_PreCrash_Fo_KSV_verfahren_Cx8_in_neg_xRichtung_und_pos_zRichtung_verfahren)}, range raw 0..8, transfer-property=TRIGGERED-ON-CHANGE-WITHOUT-REPETITION  # Ansteuerung der Kopfstuetzen im Fond durch die PreCrash-Funktionen
          signal PreCrash_BFS_Laengsverstellung_XIX_PreCrash_02_XIX_E3V_K2CANFD: start 55, 1 bit, little-endian, data-type-policy=OVERRIDE, i-signal-type=PRIMITIVE, init-value=0, base-type=BT_PreCrash_BFS_Laengsverstellung, compu {0=Cx0_nicht_angefordert (CM_PreCrash_BFS_Laengsverstellung_Cx0_nicht_angefordert), 1=Cx1_angefordert (CM_PreCrash_BFS_Laengsverstellung_Cx1_angefordert)}, range raw 0..1, transfer-property=TRIGGERED-ON-CHANGE-WITHOUT-REPETITION  # Ansteuerung der Laengsverstellung des Beifahrersitzes durch die PreCrash-Funktionen
          signal SC_PreCrash_Warnung_XIX_PreCrash_02_XIX_E3V_K2CANFD: start 56, 4 bit, little-endian, data-type-policy=OVERRIDE, i-signal-type=PRIMITIVE, init-value=0, base-type=BT_SC_PreCrash_Warnung, compu {0=Cx0_keine_Anzeige (CM_SC_PreCrash_Warnung_Cx0_keine_Anzeige), 1=Cx1_latente_Vorwarnung (CM_SC_PreCrash_Warnung_Cx1_latente_Vorwarnung), 2=Cx2_Vorwarnung (CM_SC_PreCrash_Warnung_Cx2_Vorwarnung), 3=Cx3_Akutwarnung (CM_SC_PreCrash_Warnung_Cx3_Akutwarnung), 4=Cx4_Eingriff (CM_SC_PreCrash_Warnung_Cx4_Eingriff), 5=Cx5_Fahreruebernahmeaufforderung (CM_SC_PreCrash_Warnung_Cx5_Fahreruebernahmeaufforderung), 6=Cx6_Abbiegewarnung (CM_SC_PreCrash_Warnung_Cx6_Abbiegewarnung), 7=Cx7_Basiseingriff (CM_SC_PreCrash_Warnung_Cx7_Basiseingriff), 8=Cx8_Heckeingriff (CM_SC_PreCrash_Warnung_Cx8_Heckeingriff)}, range raw 0..8, transfer-property=TRIGGERED-ON-CHANGE-WITHOUT-REPETITION  # Safety Computer übermittelt Warnung der PreCrash Funktionen an Kombi
          signal SC_PreCrash_Texte_XIX_PreCrash_02_XIX_E3V_K2CANFD: start 60, 4 bit, little-endian, data-type-policy=OVERRIDE, i-signal-type=PRIMITIVE, init-value=0, base-type=BT_SC_PreCrash_Texte, compu {0=Cx0_keine_Anzeige (CM_SC_PreCrash_Texte_Cx0_keine_Anzeige), 1=Cx1_Systemstoerung (CM_SC_PreCrash_Texte_Cx1_Systemstoerung), 2=Cx2_keine_Sensorsicht (CM_SC_PreCrash_Texte_Cx2_keine_Sensorsicht), 3=Cx3_Demomodus (CM_SC_PreCrash_Texte_Cx3_Demomodus), 4=Cx4_System_aus (CM_SC_PreCrash_Texte_Cx4_System_aus), 5=Cx5_Anhaengerbetrieb (CM_SC_PreCrash_Texte_Cx5_Anhaengerbetrieb), 6=Cx6_ESC_aus (CM_SC_PreCrash_Texte_Cx6_ESC_aus), 7=Cx7_zurzeit_eingeschraenkt (CM_SC_PreCrash_Texte_Cx7_zurzeit_eingeschraenkt), 8=Cx8_zurzeit_eingeschraenkt_ESP_Aus (CM_SC_PreCrash_Texte_Cx8_zurzeit_eingeschraenkt_ESP_Aus), 9=Cx9_Initialisierung (CM_SC_PreCrash_Texte_Cx9_Initialisierung)}, range raw 0..9, transfer-property=TRIGGERED-ON-CHANGE-WITHOUT-REPETITION  # Safety Computer übermittelt Systemstatus der PreCrash Funktionen an Kombi
      frame RCTA_01_XIX_E3V_K2CANFD: id 0x2B7, to SAM, frame-length=8, can-addressing-mode=STANDARD, can-frame-rx-behavior=CAN-FD, can-frame-tx-behavior=CAN-FD
        pdu RCTA_01_XIX_E3V_K2CANFD: length=8, transmission-mode-true-timing=cyclic-timing={time-offset=0.0, time-period=0.3}, unused-bit-pattern=0  # Rear Cross Traffic Assist
          signal RCTA_01_CRC_XIX_RCTA_01_XIX_E3V_K2CANFD: start 0, 8 bit, little-endian, data-type-policy=OVERRIDE, i-signal-type=PRIMITIVE, base-type=BT_RCTA_01_CRC, compu {phys=raw for raw 0..255}, range phys 0..255, raw 0..255, transfer-property=PENDING  # Für MLB: "Berechnung siehe Lastenheft "Kommunikationsabsicherung für FlexRay und CAN"" Ab MQB und MLBevo: "Berechnung siehe Lastenheft "End-to-End Kommunikationsabsicherung"" Endwerte siehe Begleitdokument "S-PDU Kennungsfolgen"
          signal RCTA_01_BZ_XIX_RCTA_01_XIX_E3V_K2CANFD: start 8, 4 bit, little-endian, data-type-policy=OVERRIDE, i-signal-type=PRIMITIVE, base-type=BT_RCTA_01_BZ, compu {phys=raw for raw 0..15}, range phys 0..15, raw 0..15, transfer-property=PENDING  # 4bit-Botschaftszaehler, wird in jeder Sendebotschaft inkrementiert
          signal RCTA_PaCo_MainState_XIX_RCTA_01_XIX_E3V_K2CANFD: start 12, 3 bit, little-endian, data-type-policy=OVERRIDE, i-signal-type=PRIMITIVE, init-value=0, base-type=BT_RCTA_PaCo_MainState, invalid-value=Invalid_RCTA_PaCo_MainState_XIX_RCTA_01_XIX_E3V_K2CANFD:7, compu {0=Cx0_Init (CM_RCTA_PaCo_MainState_Cx0_Init), 1=Cx1_InOperation_NoError (CM_RCTA_PaCo_MainState_Cx1_InOperation_NoError), 7=Cx7_Fehler (CM_RCTA_PaCo_MainState_Cx7_Fehler)}, range raw 0..7, transfer-property=PENDING  # Hauptzustand der Kundenfunktion RCTA 0 Init: RCTA befindet sich in der Initialisierung 1 InOperation_NoError: RCTA befindet sich im Betrieb ohne Fehler 7 Fehler: RCTA befindet sich im Fehlerzustand
          signal RCTA_Status_FoD_XIX_RCTA_01_XIX_E3V_K2CANFD: start 22, 2 bit, little-endian, data-type-policy=OVERRIDE, i-signal-type=PRIMITIVE, init-value=0, base-type=BT_RCTA_Status_FoD, compu {0=Cx0_Init (CM_RCTA_Status_FoD_Cx0_Init), 1=Cx1_keine_FoD_Freischaltung (CM_RCTA_Status_FoD_Cx1_keine_FoD_Freischaltung), 2=Cx2_FoD_Freischaltung (CM_RCTA_Status_FoD_Cx2_FoD_Freischaltung)}, range raw 0..2, transfer-property=PENDING  # RCTA Funktionsstatus für FoD
          signal RCTA_PaCo_BrakeIntervention_XIX_RCTA_01_XIX_E3V_K2CANFD: start 24, 2 bit, little-endian, data-type-policy=OVERRIDE, i-signal-type=PRIMITIVE, init-value=0, base-type=BT_RCTA_PaCo_BrakeIntervention, compu {0=Cx0_Inactive (CM_RCTA_PaCo_BrakeIntervention_Cx0_Inactive), 1=Cx1_Active (CM_RCTA_PaCo_BrakeIntervention_Cx1_Active)}, range raw 0..1, transfer-property=PENDING  # Signalisierung, ob die Kundenfunktion RCTA einen Bremseingriff ansteuert. 0 Inactive: RCTA steuert derzeit keinen Bremseingriff an 1 Active: RCTA steuert derzeit einen Bremseingriff an
          signal RCTA_PaCo_UnavailableReason_XIX_RCTA_01_XIX_E3V_K2CANFD: start 26, 3 bit, little-endian, data-type-policy=OVERRIDE, i-signal-type=PRIMITIVE, init-value=0, base-type=BT_RCTA_PaCo_UnavailableReason, compu {0=Cx0_No_Reason (CM_RCTA_PaCo_UnavailableReason_Cx0_No_Reason), 1=Cx1_Trailer_Hitched (CM_RCTA_PaCo_UnavailableReason_Cx1_Trailer_Hitched)}, range raw 0..1, transfer-property=PENDING  # Signalisierung der Ursachen für die Nicht-Verfügbarkeit von RCTA 0 No_Reason: Die RCTA-Funktion steht zur Verfügung oder es gibt keinen spezifischen Grund für die Nicht-Verfügbarkeit 1 Trailer_Hitched: Die RCTA-Funktion steht derzeit nicht zur Verfügung, weil ein Anhänger gesteckt ist
          signal RCTA_Modus_XIX_RCTA_01_XIX_E3V_K2CANFD: start 31, 3 bit, little-endian, data-type-policy=OVERRIDE, i-signal-type=PRIMITIVE, init-value=0, base-type=BT_RCTA_Modus, compu {0=Cx0_kein_Fehler_verfuegbar (CM_RCTA_Modus_Cx0_kein_Fehler_verfuegbar), 1=Cx1_Eingriffsmute (CM_RCTA_Modus_Cx1_Eingriffsmute), 2=Cx2_eingeschraenkt_Verfuegbar_pata2_Warnruck_etc (CM_RCTA_Modus_Cx2_eingeschraenkt_Verfuegbar_pata2_Warnruck_etc), 3=Cx3_Anhaengerbetrieb (CM_RCTA_Modus_Cx3_Anhaengerbetrieb), 4=Cx4_Init_nicht_codiert (CM_RCTA_Modus_Cx4_Init_nicht_codiert), 5=Cx5_keine_Sensorsicht_Blindheit (CM_RCTA_Modus_Cx5_keine_Sensorsicht_Blindheit), 6=Cx6_zur_Zeit_nicht_verfuegbar_temp_Fehler (CM_RCTA_Modus_Cx6_zur_Zeit_nicht_verfuegbar_temp_Fehler), 7=Cx7_Systemstoerung_dauer_Fehler (CM_RCTA_Modus_Cx7_Systemstoerung_dauer_Fehler)}, range raw 0..7, transfer-property=PENDING  # gibt die Verfügbarkeit der RCTA Modus an
          signal RCTA_Kritikalitaetslevel_rechts_XIX_RCTA_01_XIX_E3V_K2CANFD: start 34, 3 bit, little-endian, data-type-policy=OVERRIDE, i-signal-type=PRIMITIVE, init-value=0, base-type=BT_RCTA_Kritikalitaetslevel_rechts, compu {0=Cx0_unkritisch (CM_RCTA_Kritikalitaetslevel_rechts_Cx0_unkritisch), 1=Cx1_Kritikalitaetslevel_1 (CM_RCTA_Kritikalitaetslevel_rechts_Cx1_Kritikalitaetslevel_1), 2=Cx2_Kritikalitaetslevel_2 (CM_RCTA_Kritikalitaetslevel_rechts_Cx2_Kritikalitaetslevel_2), 3=Cx3_Kritikalitaetslevel_3 (CM_RCTA_Kritikalitaetslevel_rechts_Cx3_Kritikalitaetslevel_3), 4=Cx4_Kritikalitaetslevel_4 (CM_RCTA_Kritikalitaetslevel_rechts_Cx4_Kritikalitaetslevel_4), 5=Cx5_Kritikalitaetslevel_5 (CM_RCTA_Kritikalitaetslevel_rechts_Cx5_Kritikalitaetslevel_5), 6=Cx6_reserviert (CM_RCTA_Kritikalitaetslevel_rechts_Cx6_reserviert), 7=Cx7_nicht_bewertbar (CM_RCTA_Kritikalitaetslevel_rechts_Cx7_nicht_bewertbar)}, range raw 0..7, transfer-property=PENDING, to SAM(timeout 3 s)  # Mit dem Signal wird das Kritikalitätslevel der Funktion RCTA dargestellt. Je höher das Kritikalitätslevel ist, je höher die Crashwahrscheinlichkeit. Die Kritikalität ist nicht bewertbar, wenn - die Funktion im Anhängerbetrieb ist - die Sensorsicht blockiert ist - das System im Fehler ist
          signal RCTA_Kritikalitaetslevel_links_XIX_RCTA_01_XIX_E3V_K2CANFD: start 37, 3 bit, little-endian, data-type-policy=OVERRIDE, i-signal-type=PRIMITIVE, init-value=0, base-type=BT_RCTA_Kritikalitaetslevel_links, compu {0=Cx0_unkritisch (CM_RCTA_Kritikalitaetslevel_links_Cx0_unkritisch), 1=Cx1_Kritikalitaetslevel_1 (CM_RCTA_Kritikalitaetslevel_links_Cx1_Kritikalitaetslevel_1), 2=Cx2_Kritikalitaetslevel_2 (CM_RCTA_Kritikalitaetslevel_links_Cx2_Kritikalitaetslevel_2), 3=Cx3_Kritikalitaetslevel_3 (CM_RCTA_Kritikalitaetslevel_links_Cx3_Kritikalitaetslevel_3), 4=Cx4_Kritikalitaetslevel_4 (CM_RCTA_Kritikalitaetslevel_links_Cx4_Kritikalitaetslevel_4), 5=Cx5_Kritikalitaetslevel_5 (CM_RCTA_Kritikalitaetslevel_links_Cx5_Kritikalitaetslevel_5), 6=Cx6_reserviert (CM_RCTA_Kritikalitaetslevel_links_Cx6_reserviert), 7=Cx7_nicht_bewertbar (CM_RCTA_Kritikalitaetslevel_links_Cx7_nicht_bewertbar)}, range raw 0..7, transfer-property=PENDING, to SAM(timeout 3 s)  # Mit dem Signal wird das Kritikalitätslevel der Funktion RCTA dargestellt. Je höher das Kritikalitätslevel ist, je höher die Crashwahrscheinlichkeit. Die Kritikalität ist nicht bewertbar, wenn - die Funktion im Anhängerbetrieb ist - die Sensorsicht blockiert ist - das System im Fehler ist
          signal RCTA_Info_rechts_XIX_RCTA_01_XIX_E3V_K2CANFD: start 40, 3 bit, little-endian, data-type-policy=OVERRIDE, i-signal-type=PRIMITIVE, init-value=0, base-type=BT_RCTA_Info_rechts, compu {0=Cx0_RCTA_hat_rechts_nichts_erkannt (CM_RCTA_Info_rechts_Cx0_RCTA_hat_rechts_nichts_erkannt), 1=Cx1_RCTA_hat_rechts_blind_erkannt (CM_RCTA_Info_rechts_Cx1_RCTA_hat_rechts_blind_erkannt), 2=Cx2_RCTA_hat_rechts_frei_erkannt (CM_RCTA_Info_rechts_Cx2_RCTA_hat_rechts_frei_erkannt), 3=Cx3_RCTA_hat_rechts_unkritisch_erkannt (CM_RCTA_Info_rechts_Cx3_RCTA_hat_rechts_unkritisch_erkannt), 4=Cx4_RCTA_hat_rechts_relevant_aber_unkritisch_erkannt (CM_RCTA_Info_rechts_Cx4_RCTA_hat_rechts_relevant_aber_unkritisch_erkannt), 5=Cx5_RCTA_hat_rechts_kritisch_erkannt (CM_RCTA_Info_rechts_Cx5_RCTA_hat_rechts_kritisch_erkannt), 6=Cx6_RCTA_hat_rechts_sehr_kritisch_erkannt (CM_RCTA_Info_rechts_Cx6_RCTA_hat_rechts_sehr_kritisch_erkannt), 7=Cx7_RCTA_meldet_rechts_Kollision_steht_bevor (CM_RCTA_Info_rechts_Cx7_RCTA_meldet_rechts_Kollision_steht_bevor)}, range raw 0..7, transfer-property=PENDING  # Hinweis: In Zukunft das Signal RCTA_Kritikalitätslevel_rechts anstatt RCTA_Info_rechts verwenden! Das alte RCTA_Info wird aufgeteilt in RCTA_Info_links und RCTA_Info_rechts. Damit sollen Richtungsblinken oder ähnliches aufgrund der RCTA-Funtkion möglich gemacht werden. Dieser Parameter ist eine zusätzliche Information zu RCTA. Andere Systeme können hier Informationen aus RCTA erlangen. Hier ist kodiert, ob RCTA eine Gefahr erkennt und wie gefährdend die erkannte Situation ist. Es ist hier nicht kodiert, ob die Gefahr von links oder von rechts droht. Sondern die höchste Gefahr links oder rechts bestimmt die höchste Gefahr für das Gesamtfahrzeug. Die Informationen gliedern sich in folgende Stufen: - nichts erkannt - blind erkannt - frei erkannt. - unkritisch erkannt - relevant erkannt - kritisch erkannt - sehr kritisch erkannt - Kollision steht bevor
          signal RCTA_Anforderung_HMS_XIX_RCTA_01_XIX_E3V_K2CANFD: start 43, 3 bit, little-endian, data-type-policy=OVERRIDE, i-signal-type=PRIMITIVE, init-value=0, base-type=BT_RCTA_Anforderung_HMS, compu {0=Cx0_keine_Anforderung (CM_RCTA_Anforderung_HMS_Cx0_keine_Anforderung) (keine Anforderung), 1=Cx1_halten (CM_RCTA_Anforderung_HMS_Cx1_halten), 2=Cx2_parken (CM_RCTA_Anforderung_HMS_Cx2_parken), 3=Cx3_Halten_Standby (CM_RCTA_Anforderung_HMS_Cx3_Halten_Standby) (Halten Standby), 4=Cx4_anfahren (CM_RCTA_Anforderung_HMS_Cx4_anfahren), 5=Cx5_loesen_ueber_Rampe (CM_RCTA_Anforderung_HMS_Cx5_loesen_ueber_Rampe)}, range raw 0..5, transfer-property=PENDING  # Nach einer Notbremsung durch RCTA muss das Fahrzeug halten. Deshalb ist eine HMS-Anforderung mit der Notbremsung erforderlich.
          signal RCTA_Bremsruck_Anforderung_XIX_RCTA_01_XIX_E3V_K2CANFD: start 46, 1 bit, little-endian, data-type-policy=OVERRIDE, i-signal-type=PRIMITIVE, init-value=0, base-type=BT_RCTA_Bremsruck_Anforderung, compu {0=Cx0_nicht_angefordert (CM_RCTA_Bremsruck_Anforderung_Cx0_nicht_angefordert), 1=Cx1_angefordert (CM_RCTA_Bremsruck_Anforderung_Cx1_angefordert)}, range raw 0..1, transfer-property=PENDING  # Hinweis: In Zukunft das Signal RCTA_Anf_Warnruck anstatt RCTA_Bremsruck_Anforderung verwenden! RCTA_Bremsruck_Anforderung ist die Anforderung an das Bremssystem einen kurzen Bremsruck auszuführen. Mit dem Signal "RCTA_Bremsruck_Freigabe" zusammen wird der Ruck ausgeführt. Dadurch soll der Fahrer auf eine mögliche Kollision hingewiesen und zum Bremsen animiert werden.
          signal RCTA_Bremsruck_Freigabe_XIX_RCTA_01_XIX_E3V_K2CANFD: start 47, 1 bit, little-endian, data-type-policy=OVERRIDE, i-signal-type=PRIMITIVE, init-value=0, base-type=BT_RCTA_Bremsruck_Freigabe, compu {0=Cx0_keine_Freigabe (CM_RCTA_Bremsruck_Freigabe_Cx0_keine_Freigabe), 1=Cx1_Freigabe (CM_RCTA_Bremsruck_Freigabe_Cx1_Freigabe)}, range raw 0..1, transfer-property=PENDING  # Hinweis: In Zukunft das Signal RCTA_Anf_Warnruck anstatt RCTA_Bremsruck_Freigabe verwenden! RCTA_Bremsruck_Freigabe ist die eigentliche Auforderung (mit dem Signal "RCTA_Bremsruck_Anforderung") an das Bremssystem einen kurzen Bremsruck auszuführen. Dadurch soll der Fahrer auf eine mögliche Kollision hingewiesen und zum Bremsen animiert werden.
          signal RCTA_Info_links_XIX_RCTA_01_XIX_E3V_K2CANFD: start 48, 3 bit, little-endian, data-type-policy=OVERRIDE, i-signal-type=PRIMITIVE, init-value=0, base-type=BT_RCTA_Info_links, compu {0=Cx0_RCTA_hat_links_nichts_erkannt (CM_RCTA_Info_links_Cx0_RCTA_hat_links_nichts_erkannt), 1=Cx1_RCTA_hat_links_blind_erkannt (CM_RCTA_Info_links_Cx1_RCTA_hat_links_blind_erkannt), 2=Cx2_RCTA_hat_links_frei_erkannt (CM_RCTA_Info_links_Cx2_RCTA_hat_links_frei_erkannt), 3=Cx3_RCTA_hat_links_unkritisch_erkannt (CM_RCTA_Info_links_Cx3_RCTA_hat_links_unkritisch_erkannt), 4=Cx4_RCTA_hat_links_relevant_aber_unkritisch_erkannt (CM_RCTA_Info_links_Cx4_RCTA_hat_links_relevant_aber_unkritisch_erkannt), 5=Cx5_RCTA_hat_links_kritisch_erkannt (CM_RCTA_Info_links_Cx5_RCTA_hat_links_kritisch_erkannt), 6=Cx6_RCTA_hat_links_sehr_kritisch_erkannt (CM_RCTA_Info_links_Cx6_RCTA_hat_links_sehr_kritisch_erkannt), 7=Cx7_RCTA_meldet_links_Kollision_steht_bevor (CM_RCTA_Info_links_Cx7_RCTA_meldet_links_Kollision_steht_bevor)}, range raw 0..7, transfer-property=PENDING  # Hinweis: In Zukunft das Signal RCTA_Kritikalitätslevel_links anstatt RCTA_Info_links verwenden! Das alte RCTA_Info wird aufgeteilt in RCTA_Info_links und RCTA_Info_rechts. Damit sollen Richtungsblinken oder ähnliches aufgrund der RCTA-Funtkion möglich gemacht werden. Dieser Parameter ist eine zusätzliche Information zu RCTA. Andere Systeme können hier Informationen aus RCTA erlangen. Hier ist kodiert, ob RCTA eine Gefahr erkennt und wie gefährdend die erkannte Situation ist. Es ist hier nicht kodiert, ob die Gefahr von links oder von rechts droht. Sondern die höchste Gefahr links oder rechts bestimmt die höchste Gefahr für das Gesamtfahrzeug. Die Informationen gliedern sich in folgende Stufen: - nichts erkannt - blind erkannt - frei erkannt. - unkritisch erkannt - relevant erkannt - kritisch erkannt - sehr kritisch erkannt - Kollision steht bevor
          signal RCTA_PaCo_BrakingPossible_XIX_RCTA_01_XIX_E3V_K2CANFD: start 51, 1 bit, little-endian, data-type-policy=OVERRIDE, i-signal-type=PRIMITIVE, init-value=0, base-type=BT_RCTA_PaCo_BrakingPossible, compu {0=Cx0_Not_Possible (CM_RCTA_PaCo_BrakingPossible_Cx0_Not_Possible), 1=Cx1_Possible (CM_RCTA_PaCo_BrakingPossible_Cx1_Possible)}, range raw 0..1, transfer-property=PENDING  # Signalisierung, ob ein Bremseingriff seitens der Kundenfunktion RCTA möglich ist 0 Not_Possible: Aus Sicht von RCTA ist derzeit keine Unterstützung des Fahrers durch Bremseingriff möglich 1 Possible: Aus Sicht von RCTA ist derzeit eine Unterstützung des Fahrers durch Bremseingriff möglich
          signal RCTA_Status_XIX_RCTA_01_XIX_E3V_K2CANFD: start 52, 2 bit, little-endian, data-type-policy=OVERRIDE, i-signal-type=PRIMITIVE, init-value=0, base-type=BT_RCTA_Status, invalid-value=Invalid_RCTA_Status_XIX_RCTA_01_XIX_E3V_K2CANFD:3, compu {0=Cx0_Aus (CM_RCTA_Status_Cx0_Aus), 1=Cx1_Passiv (CM_RCTA_Status_Cx1_Passiv), 2=Cx2_Aktiv (CM_RCTA_Status_Cx2_Aktiv), 3=Cx3_Fehler (CM_RCTA_Status_Cx3_Fehler)}, range raw 0..3, transfer-property=PENDING  # RCTA_Status ist die Rückmeldung, ob das System überhaupt aktiv ist. Mögliche Zustände sind: Das System ist aus; Das System ist nur passiv (läuft, ist aber ohne Funktionalität); Das System ist aktiv; Das System ist fehlerhaft
          signal RCTA_Warnton_XIX_RCTA_01_XIX_E3V_K2CANFD: start 54, 1 bit, little-endian, data-type-policy=OVERRIDE, i-signal-type=PRIMITIVE, init-value=0, base-type=BT_RCTA_Warnton, compu {0=Cx0_Aus (CM_RCTA_Warnton_Cx0_Aus), 1=Cx1_Ein (CM_RCTA_Warnton_Cx1_Ein)}, range raw 0..1, transfer-property=PENDING  # Ansteuerung APS Tongeber für Warnton von RCTA. (Dauerton)
          signal RCTA_Notbremsung_Freigabe_XIX_RCTA_01_XIX_E3V_K2CANFD: start 55, 1 bit, little-endian, data-type-policy=OVERRIDE, i-signal-type=PRIMITIVE, init-value=0, base-type=BT_RCTA_Notbremsung_Freigabe, compu {0=Cx0_keine_Freigabe (CM_RCTA_Notbremsung_Freigabe_Cx0_keine_Freigabe), 1=Cx1_Freigabe (CM_RCTA_Notbremsung_Freigabe_Cx1_Freigabe)}, range raw 0..1, transfer-property=PENDING  # RCTA_Notbremsung_Freigabe ist die eigentliche Auforderung (mit dem Signal "Notbremsung_Anforderung_Wert") an das Bremssystem eine Notfallbremsung einzuleiten. Dadurch sollen größere Schäden am Fahrzeug vermieden werden.
          signal RCTA_Notbremsung_Anforderung_XIX_RCTA_01_XIX_E3V_K2CANFD: start 56, 8 bit, little-endian, data-type-policy=OVERRIDE, i-signal-type=PRIMITIVE, init-value=0, base-type=BT_RCTA_Notbremsung_Anforderung, invalid-value=Invalid_RCTA_Notbremsung_Anforderung_XIX_RCTA_01_XIX_E3V_K2CANFD:255, compu {0=Cx0_Init (CM_RCTA_Notbremsung_Anforderung_Cx0_Init), phys=raw*0.078-19.812 for raw 1..254, 255=Cxff_Fehler (CM_RCTA_Notbremsung_Anforderung_Cxff_Fehler); unit Unit_MeterPerSeconSquar}, range phys -19.734..0 Unit_MeterPerSeconSquar, raw 0..255, unit=Unit_MeterPerSeconSquar, transfer-property=PENDING  # RCTA_Notbremsung_Anforderung ist die Anforderung der Funktion RCTA an das Bremssystem. Mit dem Signal "Notbremsung_Freigabe" zusammen wird die Bremsung eingeleitet. Dadurch sollen größere Schäden am Fahrzeug verhindert werden.
      frame Rear_View_01_XIX_E3V_K2CANFD: id 0x6AF, to SAM, frame-length=8, can-addressing-mode=STANDARD, can-frame-rx-behavior=CAN-FD, can-frame-tx-behavior=CAN-FD
        pdu Rear_View_01_XIX_E3V_K2CANFD: length=8, minimum-delay=0.05, transmission-mode-true-timing={cyclic-timing={time-offset=0.0, time-period=1.0}, event-controlled-timing={number-of-repetitions=0, repetition-period=0.0}}, unused-bit-pattern=0
          signal RV_Video_on_XIX_Rear_View_01_XIX_E3V_K2CANFD: start 0, 1 bit, little-endian, data-type-policy=OVERRIDE, i-signal-type=PRIMITIVE, init-value=0, base-type=BT_RV_Video_on, compu {0=Cx0_Kamerabild_wird_nicht_angezeigt (CM_RV_Video_on_Cx0_Kamerabild_wird_nicht_angezeigt) (Kamerabild wird nicht angezeigt), 1=Cx1_Kamerabild_wird_angezeigt (CM_RV_Video_on_Cx1_Kamerabild_wird_angezeigt) (Kamerabild wird angezeigt)}, range raw 0..1, transfer-property=TRIGGERED-ON-CHANGE-WITHOUT-REPETITION  # Anzeige Kamerabild
          signal RV_Dark_Screen_XIX_Rear_View_01_XIX_E3V_K2CANFD: start 1, 1 bit, little-endian, data-type-policy=OVERRIDE, i-signal-type=PRIMITIVE, init-value=0, base-type=BT_RV_Dark_Screen, compu {0=Cx0_Kamerabild_nicht_verdunkeln (CM_RV_Dark_Screen_Cx0_Kamerabild_nicht_verdunkeln) (Kamerabild nicht verdunkeln), 1=Cx1_Kamerabild_verdunkeln (CM_RV_Dark_Screen_Cx1_Kamerabild_verdunkeln) (Kamerabild verdunkeln)}, range raw 0..1, transfer-property=TRIGGERED-ON-CHANGE-WITHOUT-REPETITION  # Verdunkelungsanforderung Kamerabild
          signal RV_HMI_Mode_XIX_Rear_View_01_XIX_E3V_K2CANFD: start 2, 2 bit, little-endian, data-type-policy=OVERRIDE, i-signal-type=PRIMITIVE, init-value=0, base-type=BT_RV_HMI_Mode, compu {0=Cx0_Parkluecke_Modus_1 (CM_RV_HMI_Mode_Cx0_Parkluecke_Modus_1) (Parkluecke (Modus 1)), 1=Cx1_Parallel_zur_Strasse_Modus_2 (CM_RV_HMI_Mode_Cx1_Parallel_zur_Strasse_Modus_2) (Parallel zur Straße (Modus 2)), 2=Cx2_reserviert (CM_RV_HMI_Mode_Cx2_reserviert), 3=Cx3_Kalibrierung_nur_Diagnose (CM_RV_HMI_Mode_Cx3_Kalibrierung_nur_Diagnose) (Kalibrierung (nur Diagnose))}, range raw 0..3, transfer-property=TRIGGERED-ON-CHANGE-WITHOUT-REPETITION  # Aktueller Wert für den HMI-Modus
          signal RV_GL_side_XIX_Rear_View_01_XIX_E3V_K2CANFD: start 4, 2 bit, little-endian, data-type-policy=OVERRIDE, i-signal-type=PRIMITIVE, init-value=0, base-type=BT_RV_GL_side, compu {0=Cx0_Guidelines_abgeschaltet (CM_RV_GL_side_Cx0_Guidelines_abgeschaltet), 1=Cx1_Guidelines_Anzeige_rechte_Seite (CM_RV_GL_side_Cx1_Guidelines_Anzeige_rechte_Seite), 2=Cx2_Guiedelines_Anzeige_linke_Seite (CM_RV_GL_side_Cx2_Guiedelines_Anzeige_linke_Seite), 3=Cx3_Guiedelines_Anzeige_beide_Seiten (CM_RV_GL_side_Cx3_Guiedelines_Anzeige_beide_Seiten)}, range raw 0..3, transfer-property=TRIGGERED-ON-CHANGE-WITHOUT-REPETITION
          signal RV_System_aktiv_XIX_Rear_View_01_XIX_E3V_K2CANFD: start 6, 1 bit, little-endian, data-type-policy=OVERRIDE, i-signal-type=PRIMITIVE, init-value=0, base-type=BT_RV_System_aktiv, compu {0=Cx0_System_nicht_betriebsbereit (CM_RV_System_aktiv_Cx0_System_nicht_betriebsbereit) (System nicht betriebsbereit), 1=Cx1_System_betriebsbereit (CM_RV_System_aktiv_Cx1_System_betriebsbereit) (System betriebsbereit)}, range raw 0..1, transfer-property=TRIGGERED-ON-CHANGE-WITHOUT-REPETITION  # Systemstatus (Initialisierungsphase)
          signal RV_Reinigung_Anf_XIX_Rear_View_01_XIX_E3V_K2CANFD: start 7, 1 bit, little-endian, data-type-policy=OVERRIDE, i-signal-type=PRIMITIVE, init-value=0, base-type=BT_RV_Reinigung_Anf, compu {0=Cx0_nicht_reinigen (CM_RV_Reinigung_Anf_Cx0_nicht_reinigen), 1=Cx1_reinigen (CM_RV_Reinigung_Anf_Cx1_reinigen)}, range raw 0..1, transfer-property=TRIGGERED-ON-CHANGE-WITHOUT-REPETITION, to SAM(timeout 5 s)  # Anforderung Reinigung der Rückfahrkamera
          signal RV_Settings_enabled_XIX_Rear_View_01_XIX_E3V_K2CANFD: start 8, 1 bit, little-endian, data-type-policy=OVERRIDE, i-signal-type=PRIMITIVE, init-value=0, base-type=BT_RV_Settings_enabled, compu {0=Cx0_Menu_Einstellungen_nicht_aktiviert (CM_RV_Settings_enabled_Cx0_Menu_Einstellungen_nicht_aktiviert) (Menu "Einstellungen" nicht aktiviert), 1=Cx1_Menu_Einstellungen_aktiviert (CM_RV_Settings_enabled_Cx1_Menu_Einstellungen_aktiviert) (Menu "Einstellungen" aktiviert)}, range raw 0..1, transfer-property=TRIGGERED-ON-CHANGE-WITHOUT-REPETITION  # Menü "Einstellungen"
          signal RV_Menu_Item_XIX_Rear_View_01_XIX_E3V_K2CANFD: start 9, 2 bit, little-endian, data-type-policy=OVERRIDE, i-signal-type=PRIMITIVE, init-value=0, base-type=BT_RV_Menu_Item, compu {0=Cx0_HMI_Mode_als_ausgewaehlt_markiert (CM_RV_Menu_Item_Cx0_HMI_Mode_als_ausgewaehlt_markiert) (HMI Mode als ausgewaehlt markiert), 1=Cx1_Helligkeit_als_ausgewaehlt_markiert (CM_RV_Menu_Item_Cx1_Helligkeit_als_ausgewaehlt_markiert) (Helligkeit als ausgewaehlt markiert), 2=Cx2_Kontrast_als_ausgewaehlt_markiert (CM_RV_Menu_Item_Cx2_Kontrast_als_ausgewaehlt_markiert) (Kontrast als ausgewaehlt markiert), 3=Cx3_Farbsaettigung_als_ausgewaehlt_markiert (CM_RV_Menu_Item_Cx3_Farbsaettigung_als_ausgewaehlt_markiert) (Farbsaettigung als ausgewaehlt markiert)}, range raw 0..3, transfer-property=TRIGGERED-ON-CHANGE-WITHOUT-REPETITION  # Ausgewähltes Menü-Item
          signal SV_Video_on_XIX_Rear_View_01_XIX_E3V_K2CANFD: start 11, 1 bit, little-endian, data-type-policy=OVERRIDE, i-signal-type=PRIMITIVE, init-value=0, base-type=BT_SV_Video_on, compu {0=Cx0_SideView_aus_nicht_verbaut (CM_SV_Video_on_Cx0_SideView_aus_nicht_verbaut) (SideView_aus_/_nicht_verbaut), 1=Cx1_SideView_an (CM_SV_Video_on_Cx1_SideView_an)}, range raw 0..1, transfer-property=TRIGGERED-ON-CHANGE-WITHOUT-REPETITION  # Aufschaltaufforderung SideView
          signal RV_Calib_Fehler_XIX_Rear_View_01_XIX_E3V_K2CANFD: start 12, 1 bit, little-endian, data-type-policy=OVERRIDE, i-signal-type=PRIMITIVE, init-value=0, base-type=BT_RV_Calib_Fehler, compu {0=Cx0_Kalibrierung_i_O (CM_RV_Calib_Fehler_Cx0_Kalibrierung_i_O) (Kalibrierung_i.O.), 1=Cx1_RearView_nicht_kalibriert (CM_RV_Calib_Fehler_Cx1_RearView_nicht_kalibriert)}, range raw 0..1, transfer-property=TRIGGERED-ON-CHANGE-WITHOUT-REPETITION
          signal RV_GL_Trailer_connect_XIX_Rear_View_01_XIX_E3V_K2CANFD: start 13, 1 bit, little-endian, data-type-policy=OVERRIDE, i-signal-type=PRIMITIVE, init-value=0, base-type=BT_RV_GL_Trailer_connect, compu {0=Cx0_Guidelines_werden_angezeigt (CM_RV_GL_Trailer_connect_Cx0_Guidelines_werden_angezeigt), 1=Cx1_Guidelines_wegen_angekoppeltem_Anhaenger_deaktiviert (CM_RV_GL_Trailer_connect_Cx1_Guidelines_wegen_angekoppeltem_Anhaenger_deaktiviert) (Guidelines_wegen_angekoppeltem_Anhänger_deaktiviert)}, range raw 0..1, transfer-property=TRIGGERED-ON-CHANGE-WITHOUT-REPETITION
          signal RV_GL_Trunk_open_XIX_Rear_View_01_XIX_E3V_K2CANFD: start 14, 1 bit, little-endian, data-type-policy=OVERRIDE, i-signal-type=PRIMITIVE, init-value=0, base-type=BT_RV_GL_Trunk_open, compu {0=Cx0_Guidelines_werden_angezeigt (CM_RV_GL_Trunk_open_Cx0_Guidelines_werden_angezeigt), 1=Cx1_Guidelines_wegen_geoeffneter_Heckklappe_deaktiviert (CM_RV_GL_Trunk_open_Cx1_Guidelines_wegen_geoeffneter_Heckklappe_deaktiviert) (Guidelines_wegen_geöffneter_Heckklappe_deaktiviert)}, range raw 0..1, transfer-property=TRIGGERED-ON-CHANGE-WITHOUT-REPETITION
          signal RV_GL_LWS_Fehler_XIX_Rear_View_01_XIX_E3V_K2CANFD: start 15, 1 bit, little-endian, data-type-policy=OVERRIDE, i-signal-type=PRIMITIVE, init-value=0, base-type=BT_RV_GL_LWS_Fehler, compu {0=Cx0_Guidelines_werden_angezeigt (CM_RV_GL_LWS_Fehler_Cx0_Guidelines_werden_angezeigt), 1=Cx1_Guidelines_wegen_nicht_kalibriertem_Lenkwinkelsensor_deaktiviert (CM_RV_GL_LWS_Fehler_Cx1_Guidelines_wegen_nicht_kalibriertem_Lenkwinkelsensor_deaktiviert)}, range raw 0..1, transfer-property=TRIGGERED-ON-CHANGE-WITHOUT-REPETITION
          signal RV_Helligkeit_XIX_Rear_View_01_XIX_E3V_K2CANFD: start 16, 7 bit, little-endian, data-type-policy=OVERRIDE, i-signal-type=PRIMITIVE, init-value=0, base-type=BT_RV_Helligkeit, compu {phys=raw for raw 0..100; unit Unit_PerCent}, range phys 0..100 Unit_PerCent, raw 0..100, unit=Unit_PerCent, transfer-property=TRIGGERED-ON-CHANGE-WITHOUT-REPETITION  # Istwert fuer Helligkeit (in Prozent)
          signal ZFAS_Umfeldbeleuchtung_Anf_XIX_Rear_View_01_XIX_E3V_K2CANFD: start 23, 1 bit, little-endian, data-type-policy=OVERRIDE, i-signal-type=PRIMITIVE, init-value=0, base-type=BT_ZFAS_Umfeldbeleuchtung_Anf, compu {0=Cx0_nicht_angefordert (CM_ZFAS_Umfeldbeleuchtung_Anf_Cx0_nicht_angefordert), 1=Cx1_angefordert (CM_ZFAS_Umfeldbeleuchtung_Anf_Cx1_angefordert)}, range raw 0..1, transfer-property=TRIGGERED-ON-CHANGE-WITHOUT-REPETITION  # Anforderung für die Aktivierung einer Umfeldbeleuchtung zur Unterstützung des Umfeldkamerasystems bei Dunkelheit
          signal RV_Kontrast_XIX_Rear_View_01_XIX_E3V_K2CANFD: start 24, 7 bit, little-endian, data-type-policy=OVERRIDE, i-signal-type=PRIMITIVE, init-value=0, base-type=BT_RV_Kontrast, compu {phys=raw for raw 0..100; unit Unit_PerCent}, range phys 0..100 Unit_PerCent, raw 0..100, unit=Unit_PerCent, transfer-property=TRIGGERED-ON-CHANGE-WITHOUT-REPETITION  # Istwert fuer Kontrast (in Prozent)
          signal FoD_DTC_RearView_XIX_Rear_View_01_XIX_E3V_K2CANFD: start 31, 1 bit, little-endian, data-type-policy=OVERRIDE, i-signal-type=PRIMITIVE, init-value=0, base-type=BT_FoD_DTC_RearView, compu {0=Cx0_kein_DTC (CM_FoD_DTC_RearView_Cx0_kein_DTC), 1=Cx1_RVC_DTC_vorhanden (CM_FoD_DTC_RearView_Cx1_RVC_DTC_vorhanden)}, range raw 0..1, transfer-property=PENDING  # Function on Demand DTC for RearView
          signal RV_Farbe_XIX_Rear_View_01_XIX_E3V_K2CANFD: start 32, 7 bit, little-endian, data-type-policy=OVERRIDE, i-signal-type=PRIMITIVE, init-value=0, base-type=BT_RV_Farbe, compu {phys=raw for raw 0..100; unit Unit_PerCent}, range phys 0..100 Unit_PerCent, raw 0..100, unit=Unit_PerCent, transfer-property=TRIGGERED-ON-CHANGE-WITHOUT-REPETITION  # Istwert fuer Farbe (in Prozent)
          signal FoD_DTC_TopView_SideView_XIX_Rear_View_01_XIX_E3V_K2CANFD: start 39, 2 bit, little-endian, data-type-policy=OVERRIDE, i-signal-type=PRIMITIVE, init-value=0, base-type=BT_FoD_DTC_TopView_SideView, compu {0=Cx0_Kein_DTC (CM_FoD_DTC_TopView_SideView_Cx0_Kein_DTC), 1=Cx1_TopView_DTC_vorhanden (CM_FoD_DTC_TopView_SideView_Cx1_TopView_DTC_vorhanden), 2=Cx2_SideView_DTC_vorhanden (CM_FoD_DTC_TopView_SideView_Cx2_SideView_DTC_vorhanden), 3=Cx3_TopV_und_SideV_DTC_vorhanden (CM_FoD_DTC_TopView_SideView_Cx3_TopV_und_SideV_DTC_vorhanden)}, range raw 0..3, transfer-property=PENDING  # Function on Demand DTC for TopView and SideView
      frame RHP_01_XIX_E3V_K2CANFD: id 0x6F95408, to SAM, frame-length=32, can-addressing-mode=EXTENDED, can-frame-rx-behavior=CAN-FD, can-frame-tx-behavior=CAN-FD
        pdu RHP_01_XIX_E3V_K2CANFD: length=32, transmission-mode-true-timing=cyclic-timing={time-offset=0, time-period=0.02}, unused-bit-pattern=0
          signal RHP_01_CRC_XIX_RHP_01_XIX_E3V_K2CANFD: start 0, 8 bit, little-endian, data-type-policy=OVERRIDE, i-signal-type=PRIMITIVE, init-value=0, base-type=BT_RHP_01_CRC, compu {phys=raw for raw 0..255}, range phys 0..255, raw 0..255, transfer-property=PENDING  # Für MLB: Berechnung siehe Lastenheft "Kommunikationsabsicherung für FlexRay und CAN" Ab MQB und MLBevo: Berechnung siehe Lastenheft "End-to-End Kommunikationsabsicherung" Endwerte siehe Begleitdokument "S-PDU Kennungsfolgen"
          signal RHP_01_BZ_XIX_RHP_01_XIX_E3V_K2CANFD: start 8, 4 bit, little-endian, data-type-policy=OVERRIDE, i-signal-type=PRIMITIVE, init-value=0, base-type=BT_RHP_01_BZ, compu {phys=raw for raw 0..15}, range phys 0..15, raw 0..15, transfer-property=PENDING  # 4bit Botschaftszähler, wird mit jeder Sendebotschaft inkrementiert
          signal RHP_QFK_AnfStat_XIX_RHP_01_XIX_E3V_K2CANFD: start 12, 4 bit, little-endian, data-type-policy=OVERRIDE, i-signal-type=PRIMITIVE, init-value=1, base-type=BT_RHP_QFK_AnfStat, compu {1=Cx1_Init (CM_RHP_QFK_AnfStat_Cx1_Init), 2=Cx2_Bereit (CM_RHP_QFK_AnfStat_Cx2_Bereit), 4=Cx4_Eingriff (CM_RHP_QFK_AnfStat_Cx4_Eingriff), 13=Cxd_Eingriff_HandsOff (CM_RHP_QFK_AnfStat_Cxd_Eingriff_HandsOff)}, range raw 1..13, transfer-property=PENDING  # Statusinformationen des Anforderers
          signal RHP_QFK_Spuerb_XIX_RHP_01_XIX_E3V_K2CANFD: start 16, 8 bit, little-endian, data-type-policy=OVERRIDE, i-signal-type=PRIMITIVE, init-value=0, base-type=BT_RHP_QFK_Spuerb, compu {phys=raw*0.4 for raw 0..250; unit Unit_PerCent}, range phys 0..100 Unit_PerCent, raw 0..250, unit=Unit_PerCent, transfer-property=PENDING  # Spürbarkeitsanforderung. Legt fest, mit welchem Handmoment die angeforderte Krümmung überlenkt werden muss.
          signal RHP_QFK_KruemmSoll_XIX_RHP_01_XIX_E3V_K2CANFD: start 24, 15 bit, little-endian, data-type-policy=OVERRIDE, i-signal-type=PRIMITIVE, init-value=0, base-type=BT_RHP_QFK_KruemmSoll, compu {phys=raw*6.7e-06 for raw 0..32767; unit Unit_MeterInver}, range phys 0..0.2195389 Unit_MeterInver, raw 0..32767, unit=Unit_MeterInver, transfer-property=PENDING  # Krümmungsanforderung
          signal RHP_TV_Trigger_XIX_RHP_01_XIX_E3V_K2CANFD: start 39, 1 bit, little-endian, data-type-policy=OVERRIDE, i-signal-type=PRIMITIVE, init-value=0, base-type=BT_RHP_TV_Trigger, compu {0=Cx0_No_Request (CM_RHP_TV_Trigger_Cx0_No_Request), 1=Cx1_Request (CM_RHP_TV_Trigger_Cx1_Request)}, range raw 0..1, transfer-property=PENDING  # This signal is used for switching on/off TVeMid stream data output for RHP parking function.
          signal RHP_QFK_Signal1_XIX_RHP_01_XIX_E3V_K2CANFD: start 40, 10 bit, little-endian, data-type-policy=OVERRIDE, i-signal-type=PRIMITIVE, init-value=0, base-type=BT_RHP_QFK_Signal1, compu {phys=raw for raw 0..1023}, range phys 0..1023, raw 0..1023, transfer-property=PENDING  # Inhalt RHP_QFK_Signal1 wird durch das Signal RHP_QFK_Art1 gesteuert. Nähere Informationen im LAH Querführungskoordinator.
          signal RHP_QFK_Art1_XIX_RHP_01_XIX_E3V_K2CANFD: start 50, 3 bit, little-endian, data-type-policy=OVERRIDE, i-signal-type=PRIMITIVE, init-value=0, base-type=BT_RHP_QFK_Art1, compu {phys=raw for raw 0..7}, range phys 0..7, raw 0..7, transfer-property=PENDING  # Auswahlsignal für RHP_QFK_Signal1
          signal RHP_QFK_Art2_XIX_RHP_01_XIX_E3V_K2CANFD: start 53, 3 bit, little-endian, data-type-policy=OVERRIDE, i-signal-type=PRIMITIVE, init-value=0, base-type=BT_RHP_QFK_Art2, compu {phys=raw for raw 0..7}, range phys 0..7, raw 0..7, transfer-property=PENDING  # Auswahlsignal für RHP_QFK_Signal2
          signal RHP_QFK_Signal2_XIX_RHP_01_XIX_E3V_K2CANFD: start 56, 10 bit, little-endian, data-type-policy=OVERRIDE, i-signal-type=PRIMITIVE, init-value=0, base-type=BT_RHP_QFK_Signal2, compu {phys=raw for raw 0..1023}, range phys 0..1023, raw 0..1023, transfer-property=PENDING  # Inhalt RHP_QFK_Signal2 wird durch das Signal RHP_QFK_Art2 gesteuert. Nähere Informationen im LAH Querführungskoordinator.
          signal RHP_QFK_KruemmSoll_VZ_XIX_RHP_01_XIX_E3V_K2CANFD: start 66, 1 bit, little-endian, data-type-policy=OVERRIDE, i-signal-type=PRIMITIVE, init-value=0, base-type=BT_RHP_QFK_KruemmSoll_VZ, compu {0=Cx0_positiv (CM_RHP_QFK_KruemmSoll_VZ_Cx0_positiv), 1=Cx1_negativ (CM_RHP_QFK_KruemmSoll_VZ_Cx1_negativ)}, range raw 0..1, transfer-property=PENDING  # Vorzeichen für die Krümmungsanforderung
          signal RHP_Status_Long_XIX_RHP_01_XIX_E3V_K2CANFD: start 67, 3 bit, little-endian, data-type-policy=OVERRIDE, i-signal-type=PRIMITIVE, init-value=0, base-type=BT_RHP_Status_Long, compu {0=Cx0_off (CM_RHP_Status_Long_Cx0_off), 1=Cx1_standby (CM_RHP_Status_Long_Cx1_standby), 2=Cx2_active (CM_RHP_Status_Long_Cx2_active), 3=Cx3_reserve (CM_RHP_Status_Long_Cx3_reserve), 4=Cx4_driver_override (CM_RHP_Status_Long_Cx4_driver_override), 5=Cx5_reserve (CM_RHP_Status_Long_Cx5_reserve), 6=Cx6_reserve (CM_RHP_Status_Long_Cx6_reserve), 7=Cx7_failure (CM_RHP_Status_Long_Cx7_failure)}, range raw 0..7, transfer-property=PENDING  # RHP status signal for the longitudinal control
          signal RHP_Ruckfreigabe_XIX_RHP_01_XIX_E3V_K2CANFD: start 70, 1 bit, little-endian, data-type-policy=OVERRIDE, i-signal-type=PRIMITIVE, init-value=0, base-type=BT_RHP_Ruckfreigabe, compu {0=Cx0_keine_Freigabe (CM_RHP_Ruckfreigabe_Cx0_keine_Freigabe), 1=Cx1_Freigabe (CM_RHP_Ruckfreigabe_Cx1_Freigabe)}, range raw 0..1, transfer-property=PENDING  # Anforderung Bremsruck für Funktion Rush Hour Pilot
          signal RHP_Warnruckeln_Anf_XIX_RHP_01_XIX_E3V_K2CANFD: start 71, 3 bit, little-endian, data-type-policy=OVERRIDE, i-signal-type=PRIMITIVE, init-value=0, base-type=BT_RHP_Warnruckeln_Anf, compu {0=Cx0_keine_Anforderung (CM_RHP_Warnruckeln_Anf_Cx0_keine_Anforderung), 1=Cx1_schwaches_Warnruckeln (CM_RHP_Warnruckeln_Anf_Cx1_schwaches_Warnruckeln), 2=Cx2_mittleres_Warnruckeln (CM_RHP_Warnruckeln_Anf_Cx2_mittleres_Warnruckeln), 3=Cx3_starkes_Warnruckeln (CM_RHP_Warnruckeln_Anf_Cx3_starkes_Warnruckeln)}, range raw 0..3, transfer-property=PENDING  # Anforderung an VZM, welches Warnruckeln umgesetzt werden soll.
          signal RHP_Anf_ASIL_XIX_RHP_01_XIX_E3V_K2CANFD: start 74, 3 bit, little-endian, data-type-policy=OVERRIDE, i-signal-type=PRIMITIVE, init-value=0, base-type=BT_RHP_Anf_ASIL, compu {0=Cx0_QM (CM_RHP_Anf_ASIL_Cx0_QM), 1=Cx1_A (CM_RHP_Anf_ASIL_Cx1_A), 2=Cx2_B (CM_RHP_Anf_ASIL_Cx2_B), 3=Cx3_C (CM_RHP_Anf_ASIL_Cx3_C)}, range raw 0..3, transfer-property=PENDING  # Definiert das Anforderungssignal von RHP an VZM mit dem dynamischen ASIL
          signal RHP_Anforderung_HMS_XIX_RHP_01_XIX_E3V_K2CANFD: start 77, 3 bit, little-endian, data-type-policy=OVERRIDE, i-signal-type=PRIMITIVE, init-value=0, base-type=BT_RHP_Anforderung_HMS, compu {0=Cx0_keine_Anforderung (CM_RHP_Anforderung_HMS_Cx0_keine_Anforderung), 1=Cx1_halten (CM_RHP_Anforderung_HMS_Cx1_halten), 2=Cx2_parken (CM_RHP_Anforderung_HMS_Cx2_parken), 3=Cx3_halten_Standby (CM_RHP_Anforderung_HMS_Cx3_halten_Standby), 4=Cx4_anfahren (CM_RHP_Anforderung_HMS_Cx4_anfahren), 5=Cx5_loesen_ueber_Rampe (CM_RHP_Anforderung_HMS_Cx5_loesen_ueber_Rampe), 7=Cx7_HMS_uebernehmen (CM_RHP_Anforderung_HMS_Cx7_HMS_uebernehmen)}, range raw 0..7, transfer-property=PENDING  # Bremsanforderung an den Haltemanager
          signal RHP_pos_Sollbeschl_Grad_XIX_RHP_01_XIX_E3V_K2CANFD: start 80, 8 bit, little-endian, data-type-policy=OVERRIDE, i-signal-type=PRIMITIVE, init-value=0, base-type=BT_RHP_pos_Sollbeschl_Grad, compu {phys=raw*0.05 for raw 0..255; unit Unit_MeterPerCubicSecon}, range phys 0..12.75 Unit_MeterPerCubicSecon, raw 0..255, unit=Unit_MeterPerCubicSecon, transfer-property=PENDING  # Empfehlung an den Triebstrangkoordinator , mit welchem betragsmäßig maximalen positiven Gradienten eine RHP-Anforderung 'RHP_Sollbeschleunigung' einzuregeln ist.
          signal RHP_neg_Sollbeschl_Grad_XIX_RHP_01_XIX_E3V_K2CANFD: start 88, 8 bit, little-endian, data-type-policy=OVERRIDE, i-signal-type=PRIMITIVE, init-value=0, base-type=BT_RHP_neg_Sollbeschl_Grad, compu {phys=raw*0.05 for raw 0..255; unit Unit_MeterPerCubicSecon}, range phys 0..12.75 Unit_MeterPerCubicSecon, raw 0..255, unit=Unit_MeterPerCubicSecon, transfer-property=PENDING  # Empfehlung an den Triebstrangkoordinator , mit welchem betragsmäßig maximalen negativen Gradienten eine RHP-Anforderung 'RHP_Sollbeschleunigung' einzuregeln ist.
          signal RHP_Sollbeschleunigung_XIX_RHP_01_XIX_E3V_K2CANFD: start 96, 11 bit, little-endian, data-type-policy=OVERRIDE, i-signal-type=PRIMITIVE, init-value=2046, base-type=BT_RHP_Sollbeschleunigung, invalid-value=Invalid_RHP_Sollbeschleunigung_XIX_RHP_01_XIX_E3V_K2CANFD:2047, compu {phys=raw*0.005-7.22 for raw 0..2045, 2046=Cx7fe_Neutralwert (CM_RHP_Sollbeschleunigung_Cx7fe_Neutralwert), 2047=Cx7ff_Fehler (CM_RHP_Sollbeschleunigung_Cx7ff_Fehler); unit Unit_MeterPerSeconSquar}, range phys -7.22..3.005 Unit_MeterPerSeconSquar, raw 0..2047, unit=Unit_MeterPerSeconSquar, transfer-property=PENDING  # Anforderung an den Triebstrangkoordinator , eine 'RHP_Sollbeschleunigung' umzusetzen.
          signal RHP_zul_Regelabw_oben_XIX_RHP_01_XIX_E3V_K2CANFD: start 107, 5 bit, little-endian, data-type-policy=OVERRIDE, i-signal-type=PRIMITIVE, init-value=0, base-type=BT_RHP_zul_Regelabw_oben, compu {phys=raw*0.0625 for raw 0..31; unit Unit_MeterPerSeconSquar}, range phys 0..1.9375 Unit_MeterPerSeconSquar, raw 0..31, unit=Unit_MeterPerSeconSquar, transfer-property=PENDING  # Anforderung an den Triebstrangkoordinator. Zulässiger Betrag der Abweichung zwischen angeforderter 'RHP_Sollbeschleunigung' und umzusetzender Sollbeschleunigung im TSK. Im TSK wird, abhängig vom Arbeitspunkt die Toleranz und die Sollbeschleunigung für das Getriebe und die Bremse beeinflusst. Ziel ist, unnötige Rückschaltungen und Bremseneingriffe zu vermeiden. Die beiden Signale "RHP_zul_Regelabw_unten" und "RHP_zul_Regelabw_oben" bilden ein Toleranzband um die RHP-Sollbeschleunigung.
          signal RHP_zul_Regelabw_unten_XIX_RHP_01_XIX_E3V_K2CANFD: start 112, 6 bit, little-endian, data-type-policy=OVERRIDE, i-signal-type=PRIMITIVE, init-value=0, base-type=BT_RHP_zul_Regelabw_unten, compu {phys=raw*0.024 for raw 0..63; unit Unit_MeterPerSeconSquar}, range phys 0..1.512 Unit_MeterPerSeconSquar, raw 0..63, unit=Unit_MeterPerSeconSquar, transfer-property=PENDING  # Anforderung an den Triebstrangkoordinator. Zulässiger Betrag der Abweichung zwischen angeforderter 'RHP_Sollbeschleunigung' und umzusetzender Sollbeschleunigung im TSK. Im TSK wird, abhängig vom Arbeitspunkt die Toleranz und die Sollbeschleunigung für das Getriebe und die Bremse beeinflusst. Ziel ist, unnötige Rückschaltungen und Bremseneingriffe zu vermeiden. Die beiden Signale "RHP_zul_Regelabw_unten" und "RHP_zul_Regelabw_oben" bilden ein Toleranzband um die RHP-Sollbeschleunigung.
          signal RHP_TSK_Status_XIX_RHP_01_XIX_E3V_K2CANFD: start 118, 3 bit, little-endian, data-type-policy=OVERRIDE, i-signal-type=PRIMITIVE, init-value=1, base-type=BT_RHP_TSK_Status, compu {0=Cx0_off (CM_RHP_TSK_Status_Cx0_off), 1=Cx1_init (CM_RHP_TSK_Status_Cx1_init), 2=Cx2_standby (CM_RHP_TSK_Status_Cx2_standby), 3=Cx3_active (CM_RHP_TSK_Status_Cx3_active), 4=Cx4_driver_override (CM_RHP_TSK_Status_Cx4_driver_override), 5=Cx5_shutdown (CM_RHP_TSK_Status_Cx5_shutdown), 6=Cx6_reversible_failure (CM_RHP_TSK_Status_Cx6_reversible_failure), 7=Cx7_irreversible_failure (CM_RHP_TSK_Status_Cx7_irreversible_failure)}, range raw 0..7, transfer-property=PENDING  # RHP status signal to TSK
          signal RHP_Minimale_Bremsung_XIX_RHP_01_XIX_E3V_K2CANFD: start 121, 1 bit, little-endian, data-type-policy=OVERRIDE, i-signal-type=PRIMITIVE, init-value=0, base-type=BT_RHP_Minimale_Bremsung, compu {0=Cx0_Anf_Min_Bremsung_nicht_aktiv (CM_RHP_Minimale_Bremsung_Cx0_Anf_Min_Bremsung_nicht_aktiv), 1=Cx1_Anf_Min_Bremsung_aktiv (CM_RHP_Minimale_Bremsung_Cx1_Anf_Min_Bremsung_aktiv)}, range raw 0..1, transfer-property=PENDING  # Im Falle eines gesetzten Bits wird vom RHP dem TSK angezeigt, dass es sich im Resume_Suspend_Mode befindet. In diesem Mode darf der TSK keine ECD-Bremsung anfordern, unabhängig von der 'RHP_Sollbeschleunigungsanforderung'. Eine Fahrzeugverzögerung darf nur über die Schleppverzögerung erfolgen. Sollte die Schleppverzögerung nicht ausreichen, um das Fahrzeug moderat zu verzögern, dann ist eine ECD-Verzögerung erlaubt. Die Höhe der dann vom TSK anzufordernden ECD-Verzögerung ergibt sich aus den RHP-Signalen 'RHP_Sollbeschleunigung' und ' RHP_zul_Regelabw_oben'.
          signal RHP_Uss_Anforderung_XIX_RHP_01_XIX_E3V_K2CANFD: start 122, 2 bit, little-endian, data-type-policy=OVERRIDE, i-signal-type=PRIMITIVE, init-value=0, base-type=BT_RHP_Uss_Anforderung, compu {0=Cx0_UltraschallsensorenAus (CM_RHP_Uss_Anforderung_Cx0_UltraschallsensorenAus), 1=Cx1_UltraschallsensorenAn (CM_RHP_Uss_Anforderung_Cx1_UltraschallsensorenAn)}, range raw 0..1, transfer-property=PENDING  # Control signal from RHP to front side PLA (VLS, VRS) and APS (VL, VR) sensors
          signal RHP_Verz_Anf_XIX_RHP_01_XIX_E3V_K2CANFD: start 124, 10 bit, little-endian, data-type-policy=OVERRIDE, i-signal-type=PRIMITIVE, init-value=1023, base-type=BT_RHP_Verz_Anf, compu {phys=raw*0.024-20.016 for raw 0..1022, 1023=Cx3ff_keine_Anforderung (CM_RHP_Verz_Anf_Cx3ff_keine_Anforderung); unit Unit_MeterPerSeconSquar}, range phys -20.016..4.512 Unit_MeterPerSeconSquar, raw 0..1023, unit=Unit_MeterPerSeconSquar, transfer-property=PENDING  # Verzögerungsanforderung der Funktionen Zielbremsung und Teilbremsung an das VZM
          signal RHP_Verz_Freigabe_XIX_RHP_01_XIX_E3V_K2CANFD: start 134, 1 bit, little-endian, data-type-policy=OVERRIDE, i-signal-type=PRIMITIVE, init-value=0, base-type=BT_RHP_Verz_Freigabe, compu {0=Cx0_Verzoegerung_nicht_freigeben (CM_RHP_Verz_Freigabe_Cx0_Verzoegerung_nicht_freigeben), 1=Cx1_Verzoegerung_freigeben (CM_RHP_Verz_Freigabe_Cx1_Verzoegerung_freigeben)}, range raw 0..1, transfer-property=PENDING  # Freigabe-Bit der RHP Verzögerung an das VZM
          signal RHP_Status_Lat_XIX_RHP_01_XIX_E3V_K2CANFD: start 135, 3 bit, little-endian, data-type-policy=OVERRIDE, i-signal-type=PRIMITIVE, init-value=0, base-type=BT_RHP_Status_Lat, compu {0=Cx0_off (CM_RHP_Status_Lat_Cx0_off), 1=Cx1_standby (CM_RHP_Status_Lat_Cx1_standby), 2=Cx2_active (CM_RHP_Status_Lat_Cx2_active), 3=Cx3_reserve (CM_RHP_Status_Lat_Cx3_reserve), 4=Cx4_driver_oversteer (CM_RHP_Status_Lat_Cx4_driver_oversteer), 5=Cx5_reserve (CM_RHP_Status_Lat_Cx5_reserve), 6=Cx6_reserve (CM_RHP_Status_Lat_Cx6_reserve), 7=Cx7_failure (CM_RHP_Status_Lat_Cx7_failure)}, range raw 0..7, transfer-property=PENDING  # RHP status signal for the lateral control
          signal RHP_Freilaufstrategie_TSK_XIX_RHP_01_XIX_E3V_K2CANFD: start 141, 1 bit, little-endian, data-type-policy=OVERRIDE, i-signal-type=PRIMITIVE, init-value=0, base-type=BT_RHP_Freilaufstrategie_TSK, compu {0=Cx0_Freilaufstr_nicht_angefordert (CM_RHP_Freilaufstrategie_TSK_Cx0_Freilaufstr_nicht_angefordert), 1=Cx1_Freilaufstr_angefordert (CM_RHP_Freilaufstrategie_TSK_Cx1_Freilaufstr_angefordert)}, range raw 0..1, transfer-property=PENDING  # Das Signal definiert im aktiven RHP - Betrieb, ob ein Freilauf direkt über das RHP angefordert wird oder ein Freilauf über den Triebstrangkoordinator (TSK) angefordert wird, falls das RHP den Freilauf freigibt.
          signal RHP_SCAM_HeatingRequest_XIX_RHP_01_XIX_E3V_K2CANFD: start 142, 2 bit, little-endian, data-type-policy=OVERRIDE, i-signal-type=PRIMITIVE, init-value=0, base-type=BT_RHP_SCAM_HeatingRequest, compu {0=Cx0_init (CM_RHP_SCAM_HeatingRequest_Cx0_init), 1=Cx1_not_ready (CM_RHP_SCAM_HeatingRequest_Cx1_not_ready), 2=Cx2_no_heating_request (CM_RHP_SCAM_HeatingRequest_Cx2_no_heating_request), 3=Cx3_heating_request (CM_RHP_SCAM_HeatingRequest_Cx3_heating_request)}, range raw 0..3, transfer-property=PENDING  # Gibt an, ob eine Beeinträchtigung der Kamerasicht durch Eis oder Beschlag vorliegt und diese durch Anschalten der Scheibenheizung behoben werden kann.
          signal RHP_Fahrzeughupe_Anf_XIX_RHP_01_XIX_E3V_K2CANFD: start 144, 1 bit, little-endian, data-type-policy=OVERRIDE, i-signal-type=PRIMITIVE, init-value=0, base-type=BT_RHP_Fahrzeughupe_Anf, compu {0=Cx0_Keine_Anforderung (CM_RHP_Fahrzeughupe_Anf_Cx0_Keine_Anforderung), 1=Cx1_Anforderung_Fahrzeughupe (CM_RHP_Fahrzeughupe_Anf_Cx1_Anforderung_Fahrzeughupe)}, range raw 0..1, transfer-property=PENDING, to SAM(timeout 0.5 s)  # Rush Hour Pilot Anforderung Fahrzeughupe
          signal RHP_HOS_XIX_RHP_01_XIX_E3V_K2CANFD: start 145, 2 bit, little-endian, data-type-policy=OVERRIDE, i-signal-type=PRIMITIVE, init-value=0, base-type=BT_RHP_HOS, compu {0=Cx0_not_active (CM_RHP_HOS_Cx0_not_active), 1=Cx1_hands_on (CM_RHP_HOS_Cx1_hands_on), 2=Cx2_hands_off (CM_RHP_HOS_Cx2_hands_off), 3=Cx3_hands_on_request (CM_RHP_HOS_Cx3_hands_on_request)}, range raw 0..3, transfer-property=PENDING  # Rush Hour Pilot hands-off status
          signal RHP_Status_Function_XIX_RHP_01_XIX_E3V_K2CANFD: start 147, 3 bit, little-endian, data-type-policy=OVERRIDE, i-signal-type=PRIMITIVE, init-value=0, base-type=BT_RHP_Status_Function, compu {0=Cx0_off (CM_RHP_Status_Function_Cx0_off), 1=Cx1_standby (CM_RHP_Status_Function_Cx1_standby), 2=Cx2_ready (CM_RHP_Status_Function_Cx2_ready), 3=Cx3_active (CM_RHP_Status_Function_Cx3_active), 4=Cx4_reserve (CM_RHP_Status_Function_Cx4_reserve), 5=Cx5_reserve (CM_RHP_Status_Function_Cx5_reserve), 6=Cx6_reserve (CM_RHP_Status_Function_Cx6_reserve), 7=Cx7_failure (CM_RHP_Status_Function_Cx7_failure)}, range raw 0..7, transfer-property=PENDING  # RHP status signal
          signal RHP_EA_AnfStat_XIX_RHP_01_XIX_E3V_K2CANFD: start 150, 2 bit, little-endian, data-type-policy=OVERRIDE, i-signal-type=PRIMITIVE, init-value=0, base-type=BT_RHP_EA_AnfStat, compu {0=Cx0_init (CM_RHP_EA_AnfStat_Cx0_init), 1=Cx1_ready (CM_RHP_EA_AnfStat_Cx1_ready), 2=Cx2_interference_PHASE3 (CM_RHP_EA_AnfStat_Cx2_interference_PHASE3)}, range raw 0..2, transfer-property=PENDING  # This signal indicates the activation status information from RHP to EA
          signal RHP_QFK_KrSoll_XIX_RHP_01_XIX_E3V_K2CANFD: start 152, 16 bit, little-endian, data-type-policy=OVERRIDE, i-signal-type=PRIMITIVE, init-value=0, base-type=BT_RHP_QFK_KrSoll, compu {phys=raw*6.7e-06 for raw 0..65535; unit Unit_MeterInver}, range phys 0..0.4390845 Unit_MeterInver, raw 0..65535, unit=Unit_MeterInver, transfer-property=PENDING  # Krümmungsanforderung
          signal RHP_QFK_KrSoll_VZ_XIX_RHP_01_XIX_E3V_K2CANFD: start 168, 1 bit, little-endian, data-type-policy=OVERRIDE, i-signal-type=PRIMITIVE, init-value=0, base-type=BT_RHP_QFK_KrSoll_VZ, compu {0=Cx0_positiv (CM_RHP_QFK_KrSoll_VZ_Cx0_positiv), 1=Cx1_negativ (CM_RHP_QFK_KrSoll_VZ_Cx1_negativ)}, range raw 0..1, transfer-property=PENDING  # Vorzeichen für die Krümmungsanforderung
          signal RHP_Warnblinken_XIX_RHP_01_XIX_E3V_K2CANFD: start 169, 1 bit, little-endian, data-type-policy=OVERRIDE, i-signal-type=PRIMITIVE, init-value=0, base-type=BT_RHP_Warnblinken, compu {0=Cx0_kein_Blinken (CM_RHP_Warnblinken_Cx0_kein_Blinken), 1=Cx1_Warnblinken_Taster (CM_RHP_Warnblinken_Cx1_Warnblinken_Taster)}, range raw 0..1, transfer-property=PENDING  # Ansteuerung des Warnblinkers für die Funktion Rush Hour Pilot
          signal RHP_Spurwechsel_Ready_XIX_RHP_01_XIX_E3V_K2CANFD: start 171, 3 bit, little-endian, data-type-policy=OVERRIDE, i-signal-type=PRIMITIVE, init-value=0, base-type=BT_RHP_Spurwechsel_Ready, compu {0=Cx0_nicht_moeglich (CM_RHP_Spurwechsel_Ready_Cx0_nicht_moeglich), 1=Cx1_links_moeglich (CM_RHP_Spurwechsel_Ready_Cx1_links_moeglich), 2=Cx2_rechts_moeglich (CM_RHP_Spurwechsel_Ready_Cx2_rechts_moeglich), 3=Cx3_links_rechts_moeglich (CM_RHP_Spurwechsel_Ready_Cx3_links_rechts_moeglich), 4=Cx4_links_blinken (CM_RHP_Spurwechsel_Ready_Cx4_links_blinken), 5=Cx5_rechts_blinken (CM_RHP_Spurwechsel_Ready_Cx5_rechts_blinken)}, range raw 0..5, transfer-property=PENDING  # Angabe der assistierten Spurwechselmöglichkeiten durch die Funktion "Rush Hour Pilot"
          signal RHP_RBF_Available_XIX_RHP_01_XIX_E3V_K2CANFD: start 174, 2 bit, little-endian, data-type-policy=OVERRIDE, i-signal-type=PRIMITIVE, init-value=0, base-type=BT_RHP_RBF_Available, compu {0=Cx0_Init (CM_RHP_RBF_Available_Cx0_Init), 1=Cx1_Available (CM_RHP_RBF_Available_Cx1_Available), 2=Cx2_NotAvailable (CM_RHP_RBF_Available_Cx2_NotAvailable), 3=Cx3_Reserved (CM_RHP_RBF_Available_Cx3_Reserved)}, range raw 0..3, transfer-property=PENDING  # This signal is used for info RBF for RHP can support RBF forward or not
          signal RHP_EA_PreCrash_XIX_RHP_01_XIX_E3V_K2CANFD: start 179, 3 bit, little-endian, data-type-policy=OVERRIDE, i-signal-type=PRIMITIVE, init-value=0, base-type=BT_RHP_EA_PreCrash, compu {0=Cx0_Keine_Anforderung (CM_RHP_EA_PreCrash_Cx0_Keine_Anforderung), 1=Cx1_Aktionsgenerierte_Warnung_1 (CM_RHP_EA_PreCrash_Cx1_Aktionsgenerierte_Warnung_1), 2=Cx2_Aktionsgenerierte_Warnung_2 (CM_RHP_EA_PreCrash_Cx2_Aktionsgenerierte_Warnung_2), 3=Cx3_Aktionsgenerierte_Warnung_3 (CM_RHP_EA_PreCrash_Cx3_Aktionsgenerierte_Warnung_3), 4=Cx4_Aktionsgenerierte_Warnung_4 (CM_RHP_EA_PreCrash_Cx4_Aktionsgenerierte_Warnung_4), 5=Cx5_Aktionsgenerierte_Warnung_5 (CM_RHP_EA_PreCrash_Cx5_Aktionsgenerierte_Warnung_5), 6=Cx6_Aktionsgenerierte_Warnung_6 (CM_RHP_EA_PreCrash_Cx6_Aktionsgenerierte_Warnung_6), 7=Cx7_Aktionsgenerierte_Warnung_7 (CM_RHP_EA_PreCrash_Cx7_Aktionsgenerierte_Warnung_7)}, range raw 0..7, transfer-property=PENDING  # RHP triggers PreCrash via sending the requirements on EA
          signal RHP_OPSEnable_XIX_RHP_01_XIX_E3V_K2CANFD: start 186, 2 bit, little-endian, data-type-policy=OVERRIDE, i-signal-type=PRIMITIVE, init-value=0, base-type=BT_RHP_OPSEnable, compu {0=Cx0_Initial (CM_RHP_OPSEnable_Cx0_Initial), 1=Cx1_Not_enable (CM_RHP_OPSEnable_Cx1_Not_enable), 2=Cx2_Enable (CM_RHP_OPSEnable_Cx2_Enable)}, range raw 0..2, transfer-property=PENDING  # The OPS function receives the following signal to enable the function
          signal RHP_Tempolimitassistent_EIN_XIX_RHP_01_XIX_E3V_K2CANFD: start 192, 1 bit, little-endian, data-type-policy=OVERRIDE, i-signal-type=PRIMITIVE, base-type=BT_RHP_Tempolimitassistent_EIN, compu {0=Cx0_Deactivate (CM_RHP_Tempolimitassistent_EIN_Cx0_Deactivate), 1=Cx1_Activate (CM_RHP_Tempolimitassistent_EIN_Cx1_Activate)}, range raw 0..1, transfer-property=PENDING  # This signal is created to disable VZE overspeed warning, when RHP2.0 is activated with speed offset (max +10%), for better customer experience.
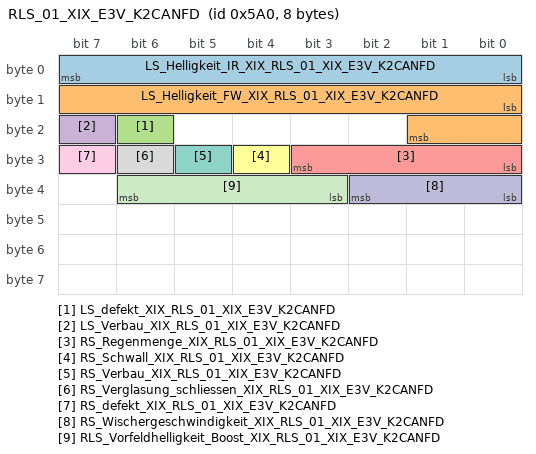
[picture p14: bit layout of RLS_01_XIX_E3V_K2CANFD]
      frame RLS_01_XIX_E3V_K2CANFD: id 0x5A0, from SAM, frame-length=8, can-addressing-mode=STANDARD, can-frame-rx-behavior=CAN-FD, can-frame-tx-behavior=CAN-FD
        pdu RLS_01_XIX_E3V_K2CANFD: length=8, transmission-mode-true-timing=cyclic-timing={time-offset=0.0, time-period=0.2}, unused-bit-pattern=0  # 8Byte ab MLBevo LIN-CAN (1:1) Botschaften werden geroutet - wenn entsprechender Slave codiert ist - wenn fehlerfreie Kommunikation zum Slave besteht - bei fehlerhafter Kommunikation zum Slave wird die Botschaft für 4s mit den letzten gültigen Werten versendet
          signal LS_Helligkeit_IR_XIX_RLS_01_XIX_E3V_K2CANFD: start 0, 8 bit, little-endian, data-type-policy=OVERRIDE, i-signal-type=PRIMITIVE, init-value=254, base-type=BT_LS_Helligkeit_IR, invalid-value=Invalid_LS_Helligkeit_IR_XIX_RLS_01_XIX_E3V_K2CANFD:255, compu {phys=raw*400 for raw 0..253, 254=Cxfe_Init (CM_LS_Helligkeit_IR_Cxfe_Init), 255=Cxff_Fehler (CM_LS_Helligkeit_IR_Cxff_Fehler); unit Unit_Lux}, range phys 0..101200 Unit_Lux, raw 0..255, unit=Unit_Lux, transfer-property=PENDING  # Globalfeldhelligkeit
          signal LS_Helligkeit_FW_XIX_RLS_01_XIX_E3V_K2CANFD: start 8, 10 bit, little-endian, data-type-policy=OVERRIDE, i-signal-type=PRIMITIVE, init-value=1022, base-type=BT_LS_Helligkeit_FW, invalid-value=Invalid_LS_Helligkeit_FW_XIX_RLS_01_XIX_E3V_K2CANFD:1023, compu {phys=raw*6 for raw 0..1021, 1022=Cx3fe_Init (CM_LS_Helligkeit_FW_Cx3fe_Init), 1023=Cx3ff_Fehler (CM_LS_Helligkeit_FW_Cx3ff_Fehler); unit Unit_Lux}, range phys 0..6126 Unit_Lux, raw 0..1023, unit=Unit_Lux, transfer-property=PENDING  # Vorfeldhelligkeit
          signal LS_defekt_XIX_RLS_01_XIX_E3V_K2CANFD: start 22, 1 bit, little-endian, data-type-policy=OVERRIDE, i-signal-type=PRIMITIVE, init-value=0, base-type=BT_LS_defekt, compu {0=Cx0_OK (CM_LS_defekt_Cx0_OK), 1=Cx1_defekt (CM_LS_defekt_Cx1_defekt)}, range raw 0..1, transfer-property=PENDING  # Fehlererkennung Lichtsensor
          signal LS_Verbau_XIX_RLS_01_XIX_E3V_K2CANFD: start 23, 1 bit, little-endian, data-type-policy=OVERRIDE, i-signal-type=PRIMITIVE, init-value=0, base-type=BT_LS_Verbau, compu {0=Cx0_Init (CM_LS_Verbau_Cx0_Init), 1=Cx1_Lichtsensor_verbaut (CM_LS_Verbau_Cx1_Lichtsensor_verbaut)}, range raw 0..1, transfer-property=PENDING  # Verbauinfo Lichtsensor
          signal RS_Regenmenge_XIX_RLS_01_XIX_E3V_K2CANFD: start 24, 4 bit, little-endian, data-type-policy=OVERRIDE, i-signal-type=PRIMITIVE, init-value=14, base-type=BT_RS_Regenmenge, invalid-value=Invalid_RS_Regenmenge_XIX_RLS_01_XIX_E3V_K2CANFD:15, compu {0=Cx0_0 (CM_RS_Regenmenge_Cx0_0), 1=Cx1_0_0_bis_0_3 (CM_RS_Regenmenge_Cx1_0_0_bis_0_3) (0,0_bis_0,3), 2=Cx2_0_31_bis_1_4 (CM_RS_Regenmenge_Cx2_0_31_bis_1_4) (0,31_bis_1,4), 3=Cx3_1_41_bis_2_0 (CM_RS_Regenmenge_Cx3_1_41_bis_2_0) (1,41_bis_2,0), 4=Cx4_2_01_bis_2_8 (CM_RS_Regenmenge_Cx4_2_01_bis_2_8) (2,01_bis_2,8), 5=Cx5_2_81_bis_3_3 (CM_RS_Regenmenge_Cx5_2_81_bis_3_3) (2,81_bis_3,3), 6=Cx6_3_31_bis_4_0 (CM_RS_Regenmenge_Cx6_3_31_bis_4_0) (3,31_bis_4,0), 7=Cx7_4_01_bis_5_0 (CM_RS_Regenmenge_Cx7_4_01_bis_5_0) (4,01_bis_5,0), 8=Cx8_5_01_bis_7_0 (CM_RS_Regenmenge_Cx8_5_01_bis_7_0) (5,01_bis_7,0), 9=Cx9_7_01_bis_9_0 (CM_RS_Regenmenge_Cx9_7_01_bis_9_0) (7,01_bis_9,0), 10=Cxa_9_01_bis_11_0 (CM_RS_Regenmenge_Cxa_9_01_bis_11_0) (9,01_bis_11,0), 11=Cxb_11_01_bis_15_0 (CM_RS_Regenmenge_Cxb_11_01_bis_15_0) (11,01_bis_15,0), 12=Cxc_15_01_bis_22_0 (CM_RS_Regenmenge_Cxc_15_01_bis_22_0) (15,01_bis_22,0), 13=Cxd_22_01 (CM_RS_Regenmenge_Cxd_22_01) (>22,01), 14=Cxe_Init (CM_RS_Regenmenge_Cxe_Init), 15=Cxf_Fehler (CM_RS_Regenmenge_Cxf_Fehler)}, range raw 0..15, transfer-property=PENDING  # Regenmenge
          signal RS_Schwall_XIX_RLS_01_XIX_E3V_K2CANFD: start 28, 1 bit, little-endian, data-type-policy=OVERRIDE, i-signal-type=PRIMITIVE, init-value=0, base-type=BT_RS_Schwall, compu {0=Cx0_Aus (CM_RS_Schwall_Cx0_Aus), 1=Cx1_Ein (CM_RS_Schwall_Cx1_Ein)}, range raw 0..1, transfer-property=PENDING  # Schwallereignis
          signal RS_Verbau_XIX_RLS_01_XIX_E3V_K2CANFD: start 29, 1 bit, little-endian, data-type-policy=OVERRIDE, i-signal-type=PRIMITIVE, init-value=0, base-type=BT_RS_Verbau, compu {0=Cx0_Init (CM_RS_Verbau_Cx0_Init), 1=Cx1_Regensensor_verbaut (CM_RS_Verbau_Cx1_Regensensor_verbaut) (Regensensor verbaut)}, range raw 0..1, transfer-property=PENDING  # Verbauinfo Regensensor
          signal RS_Verglasung_schliessen_XIX_RLS_01_XIX_E3V_K2CANFD: start 30, 1 bit, little-endian, data-type-policy=OVERRIDE, i-signal-type=PRIMITIVE, init-value=0, base-type=BT_RS_Verglasung_schliessen, compu {0=Cx0_Verglasung_nicht_schliessen (CM_RS_Verglasung_schliessen_Cx0_Verglasung_nicht_schliessen) (Verglasung nicht schliessen), 1=Cx1_Verglasung_schliessen (CM_RS_Verglasung_schliessen_Cx1_Verglasung_schliessen) (Verglasung schliessen)}, range raw 0..1, transfer-property=PENDING  # Anforderung: Verglasung schliessen
          signal RS_defekt_XIX_RLS_01_XIX_E3V_K2CANFD: start 31, 1 bit, little-endian, data-type-policy=OVERRIDE, i-signal-type=PRIMITIVE, init-value=0, base-type=BT_RS_defekt, compu {0=Cx0_OK (CM_RS_defekt_Cx0_OK), 1=Cx1_defekt (CM_RS_defekt_Cx1_defekt)}, range raw 0..1, transfer-property=PENDING  # Fehlererkennung Regensensor
          signal RS_Wischergeschwindigkeit_XIX_RLS_01_XIX_E3V_K2CANFD: start 32, 3 bit, little-endian, data-type-policy=OVERRIDE, i-signal-type=PRIMITIVE, init-value=0, base-type=BT_RS_Wischergeschwindigkeit, compu {0=Cx0_kein_Wischen (CM_RS_Wischergeschwindigkeit_Cx0_kein_Wischen) (kein Wischen), 1=Cx1_42_Huebe_min (CM_RS_Wischergeschwindigkeit_Cx1_42_Huebe_min) (42 Huebe/min), 2=Cx2_45_Huebe_min (CM_RS_Wischergeschwindigkeit_Cx2_45_Huebe_min) (45 Huebe/min), 3=Cx3_48_Huebe_min (CM_RS_Wischergeschwindigkeit_Cx3_48_Huebe_min) (48 Huebe/min), 4=Cx4_51_Huebe_min (CM_RS_Wischergeschwindigkeit_Cx4_51_Huebe_min) (51 Huebe/min), 5=Cx5_54_Huebe_min (CM_RS_Wischergeschwindigkeit_Cx5_54_Huebe_min) (54 Huebe/min), 6=Cx6_57_Huebe_min (CM_RS_Wischergeschwindigkeit_Cx6_57_Huebe_min) (57 Huebe/min), 7=Cx7_60_Huebe_min (CM_RS_Wischergeschwindigkeit_Cx7_60_Huebe_min) (60 Huebe/min)}, range raw 0..7, transfer-property=PENDING  # Wischergeschwindigkeit (Hübe/min)
          signal RLS_Vorfeldhelligkeit_Boost_XIX_RLS_01_XIX_E3V_K2CANFD: start 35, 4 bit, little-endian, data-type-policy=OVERRIDE, i-signal-type=PRIMITIVE, init-value=15, base-type=BT_RLS_Vorfeldhelligkeit_Boost, compu {0=Cx0_groesser_24413_Lux (CM_RLS_Vorfeldhelligkeit_Boost_Cx0_groesser_24413_Lux), 1=Cx1_bis_24413_Lux (CM_RLS_Vorfeldhelligkeit_Boost_Cx1_bis_24413_Lux), 2=Cx2_bis_22193_Lux (CM_RLS_Vorfeldhelligkeit_Boost_Cx2_bis_22193_Lux), 3=Cx3_bis_20176_Lux (CM_RLS_Vorfeldhelligkeit_Boost_Cx3_bis_20176_Lux), 4=Cx4_bis_18342_Lux (CM_RLS_Vorfeldhelligkeit_Boost_Cx4_bis_18342_Lux), 5=Cx5_bis_16647_Lux (CM_RLS_Vorfeldhelligkeit_Boost_Cx5_bis_16647_Lux), 6=Cx6_bis_15158_Lux (CM_RLS_Vorfeldhelligkeit_Boost_Cx6_bis_15158_Lux), 7=Cx7_bis_13780_Lux (CM_RLS_Vorfeldhelligkeit_Boost_Cx7_bis_13780_Lux), 8=Cx8_bis_12527_Lux (CM_RLS_Vorfeldhelligkeit_Boost_Cx8_bis_12527_Lux), 9=Cx9_bis_11388_Lux (CM_RLS_Vorfeldhelligkeit_Boost_Cx9_bis_11388_Lux), 10=Cxa_bis_10353_Lux (CM_RLS_Vorfeldhelligkeit_Boost_Cxa_bis_10353_Lux), 11=Cxb_bis_9412_Lux (CM_RLS_Vorfeldhelligkeit_Boost_Cxb_bis_9412_Lux), 12=Cxc_bis_8556_Lux (CM_RLS_Vorfeldhelligkeit_Boost_Cxc_bis_8556_Lux), 13=Cxd_bis_7778_Lux (CM_RLS_Vorfeldhelligkeit_Boost_Cxd_bis_7778_Lux), 14=Cxe_bis_7071_Lux (CM_RLS_Vorfeldhelligkeit_Boost_Cxe_bis_7071_Lux), 15=Cxf_bis_6428_Lux (CM_RLS_Vorfeldhelligkeit_Boost_Cxf_bis_6428_Lux)}, range raw 0..15, transfer-property=PENDING  # erweiterte Helligkeitssensierung für HUD
      frame RLS_02_XIX_E3V_K2CANFD: id 0x16A954B5, from SAM, frame-length=8, can-addressing-mode=EXTENDED, can-frame-rx-behavior=CAN-FD, can-frame-tx-behavior=CAN-FD
        pdu RLS_02_XIX_E3V_K2CANFD_E2E: length=8, transmission-mode-true-timing=event-controlled-timing={number-of-repetitions=0, repetition-period=0.0}, unused-bit-pattern=0  # Fuer die Botschaft ist das Cyclic-Timing 0.08 zu verwenden.
          signal RLS_02_CRC_XIX_RLS_02_XIX_E3V_K2CANFD: start 0, 8 bit, little-endian, data-type-policy=OVERRIDE, i-signal-type=PRIMITIVE, init-value=0, base-type=BT_RLS_02_CRC, compu {phys=raw for raw 0..255}, range phys 0..255, raw 0..255  # Für MLB: Berechnung siehe Lastenheft "Kommunikationsabsicherung für FlexRay und CAN" Ab MQB und MLBevo: Berechnung siehe Lastenheft "End-to-End Kommunikationsabsicherung" Endwerte siehe Begleitdokument "S-PDU Kennungsfolgen"
          signal RLS_02_BZ_XIX_RLS_02_XIX_E3V_K2CANFD: start 8, 4 bit, little-endian, data-type-policy=OVERRIDE, i-signal-type=PRIMITIVE, init-value=0, base-type=BT_RLS_02_BZ, compu {phys=raw for raw 0..15}, range phys 0..15, raw 0..15  # 4bit Botschaftszähler, wird mit jeder Sendebotschaft inkrementiert
          signal RLS_Qualifizierungsbit_XIX_RLS_02_XIX_E3V_K2CANFD: start 12, 1 bit, little-endian, data-type-policy=OVERRIDE, i-signal-type=PRIMITIVE, init-value=0, base-type=BT_RLS_Qualifizierungsbit, compu {0=Cx0_ungueltig (CM_RLS_Qualifizierungsbit_Cx0_ungueltig), 1=Cx1_gueltig (CM_RLS_Qualifizierungsbit_Cx1_gueltig)}, range raw 0..1  # Qualifizierungsbit für die Signale "LS_Licht_ein" und "LS_Licht_ein_invers"
          signal RS_Wischergeschwindigkeit_XIX_RLS_02_XIX_E3V_K2CANFD: start 13, 3 bit, little-endian, data-type-policy=OVERRIDE, i-signal-type=PRIMITIVE, init-value=0, base-type=BT_RS_Wischergeschwindigkeit, compu {0=Cx0_kein_Wischen (CM_RS_Wischergeschwindigkeit_Cx0_kein_Wischen) (kein Wischen), 1=Cx1_42_Huebe_min (CM_RS_Wischergeschwindigkeit_Cx1_42_Huebe_min) (42 Huebe/min), 2=Cx2_45_Huebe_min (CM_RS_Wischergeschwindigkeit_Cx2_45_Huebe_min) (45 Huebe/min), 3=Cx3_48_Huebe_min (CM_RS_Wischergeschwindigkeit_Cx3_48_Huebe_min) (48 Huebe/min), 4=Cx4_51_Huebe_min (CM_RS_Wischergeschwindigkeit_Cx4_51_Huebe_min) (51 Huebe/min), 5=Cx5_54_Huebe_min (CM_RS_Wischergeschwindigkeit_Cx5_54_Huebe_min) (54 Huebe/min), 6=Cx6_57_Huebe_min (CM_RS_Wischergeschwindigkeit_Cx6_57_Huebe_min) (57 Huebe/min), 7=Cx7_60_Huebe_min (CM_RS_Wischergeschwindigkeit_Cx7_60_Huebe_min) (60 Huebe/min)}, range raw 0..7  # Wischergeschwindigkeit (Hübe/min)
          signal RS_Schwall_XIX_RLS_02_XIX_E3V_K2CANFD: start 16, 1 bit, little-endian, data-type-policy=OVERRIDE, i-signal-type=PRIMITIVE, init-value=0, base-type=BT_RS_Schwall, compu {0=Cx0_Aus (CM_RS_Schwall_Cx0_Aus), 1=Cx1_Ein (CM_RS_Schwall_Cx1_Ein)}, range raw 0..1  # Schwallereignis
          signal RS_Verglasung_schliessen_XIX_RLS_02_XIX_E3V_K2CANFD: start 17, 1 bit, little-endian, data-type-policy=OVERRIDE, i-signal-type=PRIMITIVE, init-value=0, base-type=BT_RS_Verglasung_schliessen, compu {0=Cx0_Verglasung_nicht_schliessen (CM_RS_Verglasung_schliessen_Cx0_Verglasung_nicht_schliessen) (Verglasung nicht schliessen), 1=Cx1_Verglasung_schliessen (CM_RS_Verglasung_schliessen_Cx1_Verglasung_schliessen) (Verglasung schliessen)}, range raw 0..1  # Anforderung: Verglasung schliessen
          signal RS_versParklage_Wischer_XIX_RLS_02_XIX_E3V_K2CANFD: start 18, 1 bit, little-endian, data-type-policy=OVERRIDE, i-signal-type=PRIMITIVE, init-value=0, base-type=BT_RS_versParklage_Wischer, compu {0=Cx0_Aus (CM_RS_versParklage_Wischer_Cx0_Aus), 1=Cx1_Ein (CM_RS_versParklage_Wischer_Cx1_Ein)}, range raw 0..1  # versenkte Parklage Wischer
          signal LS_Licht_ein_XIX_RLS_02_XIX_E3V_K2CANFD: start 19, 1 bit, little-endian, data-type-policy=OVERRIDE, i-signal-type=PRIMITIVE, init-value=0, base-type=BT_LS_Licht_ein, compu {0=Cx0_Aus (CM_LS_Licht_ein_Cx0_Aus), 1=Cx1_Ein (CM_LS_Licht_ein_Cx1_Ein)}, range raw 0..1  # Anfoderung Fahrlicht
          signal LS_Licht_ein_invers_XIX_RLS_02_XIX_E3V_K2CANFD: start 20, 1 bit, little-endian, data-type-policy=OVERRIDE, i-signal-type=PRIMITIVE, init-value=1, base-type=BT_LS_Licht_ein_invers, compu {0=Cx0_Aus (CM_LS_Licht_ein_invers_Cx0_Aus), 1=Cx1_Ein (CM_LS_Licht_ein_invers_Cx1_Ein)}, range raw 0..1  # Inversbit Anforderung Fahrlicht
          signal LS_Dunkel_XIX_RLS_02_XIX_E3V_K2CANFD: start 21, 1 bit, little-endian, data-type-policy=OVERRIDE, i-signal-type=PRIMITIVE, init-value=0, base-type=BT_LS_Dunkel, compu {0=Cx0_Hell (CM_LS_Dunkel_Cx0_Hell), 1=Cx1_Dunkel (CM_LS_Dunkel_Cx1_Dunkel)}, range raw 0..1  # Regen- / Lichtsensor
          signal LS_TFL_mit_SL_ein_XIX_RLS_02_XIX_E3V_K2CANFD: start 22, 1 bit, little-endian, data-type-policy=OVERRIDE, i-signal-type=PRIMITIVE, init-value=1, base-type=BT_LS_TFL_mit_SL_ein, compu {0=Cx0_TFL_mit_SL_aus (CM_LS_TFL_mit_SL_ein_Cx0_TFL_mit_SL_aus), 1=Cx1_TFL_mit_SL_ein (CM_LS_TFL_mit_SL_ein_Cx1_TFL_mit_SL_ein)}, range raw 0..1  # Anforderung Tagfahrlich mit Schlusslicht
          signal RS_Regenfahrlicht_XIX_RLS_02_XIX_E3V_K2CANFD: start 23, 1 bit, little-endian, data-type-policy=OVERRIDE, i-signal-type=PRIMITIVE, init-value=0, base-type=BT_RS_Regenfahrlicht, compu {0=Cx0_Aus (CM_RS_Regenfahrlicht_Cx0_Aus), 1=Cx1_Ein (CM_RS_Regenfahrlicht_Cx1_Ein)}, range raw 0..1  # Regenlicht Anforderung
          signal RS_AdaptierungError_XIX_RLS_02_XIX_E3V_K2CANFD: start 24, 1 bit, little-endian, data-type-policy=OVERRIDE, i-signal-type=PRIMITIVE, init-value=0, base-type=BT_RS_AdaptierungError, invalid-value=Invalid_RS_AdaptierungError_XIX_RLS_02_XIX_E3V_K2CANFD:1, compu {0=Cx0_normal (CM_RS_AdaptierungError_Cx0_normal), 1=Cx1_Fehler (CM_RS_AdaptierungError_Cx1_Fehler)}, range raw 0..1  # Adaptierungsfehler Regensensor
          signal RS_Error_XIX_RLS_02_XIX_E3V_K2CANFD: start 25, 1 bit, little-endian, data-type-policy=OVERRIDE, i-signal-type=PRIMITIVE, init-value=0, base-type=BT_RS_Error, invalid-value=Invalid_RS_Error_XIX_RLS_02_XIX_E3V_K2CANFD:1, compu {0=Cx0_normal (CM_RS_Error_Cx0_normal), 1=Cx1_Fehler (CM_RS_Error_Cx1_Fehler)}, range raw 0..1  # Fehler/Defekt Regensensorik
          signal LS_Error_XIX_RLS_02_XIX_E3V_K2CANFD: start 26, 1 bit, little-endian, data-type-policy=OVERRIDE, i-signal-type=PRIMITIVE, init-value=0, base-type=BT_LS_Error, invalid-value=Invalid_LS_Error_XIX_RLS_02_XIX_E3V_K2CANFD:1, compu {0=Cx0_normal (CM_LS_Error_Cx0_normal), 1=Cx1_Fehler (CM_LS_Error_Cx1_Fehler)}, range raw 0..1  # Fehler/Defekt Lichtsensorik
          signal RLS_ResponseError_XIX_RLS_02_XIX_E3V_K2CANFD: start 27, 1 bit, little-endian, data-type-policy=OVERRIDE, i-signal-type=PRIMITIVE, init-value=0, base-type=BT_RLS_ResponseError, invalid-value=Invalid_RLS_ResponseError_XIX_RLS_02_XIX_E3V_K2CANFD:1, compu {0=Cx0_normal (CM_RLS_ResponseError_Cx0_normal), 1=Cx1_Fehler (CM_RLS_ResponseError_Cx1_Fehler)}, range raw 0..1  # siehe LIN2.0-Specification (Darf nicht über ein Fehlergueltigkeitsbit abgesichtert werden!)
          signal RLS_Vorfeldhelligkeit_Boost_XIX_RLS_02_XIX_E3V_K2CANFD: start 28, 4 bit, little-endian, data-type-policy=OVERRIDE, i-signal-type=PRIMITIVE, init-value=15, base-type=BT_RLS_Vorfeldhelligkeit_Boost, compu {0=Cx0_groesser_24413_Lux (CM_RLS_Vorfeldhelligkeit_Boost_Cx0_groesser_24413_Lux), 1=Cx1_bis_24413_Lux (CM_RLS_Vorfeldhelligkeit_Boost_Cx1_bis_24413_Lux), 2=Cx2_bis_22193_Lux (CM_RLS_Vorfeldhelligkeit_Boost_Cx2_bis_22193_Lux), 3=Cx3_bis_20176_Lux (CM_RLS_Vorfeldhelligkeit_Boost_Cx3_bis_20176_Lux), 4=Cx4_bis_18342_Lux (CM_RLS_Vorfeldhelligkeit_Boost_Cx4_bis_18342_Lux), 5=Cx5_bis_16647_Lux (CM_RLS_Vorfeldhelligkeit_Boost_Cx5_bis_16647_Lux), 6=Cx6_bis_15158_Lux (CM_RLS_Vorfeldhelligkeit_Boost_Cx6_bis_15158_Lux), 7=Cx7_bis_13780_Lux (CM_RLS_Vorfeldhelligkeit_Boost_Cx7_bis_13780_Lux), 8=Cx8_bis_12527_Lux (CM_RLS_Vorfeldhelligkeit_Boost_Cx8_bis_12527_Lux), 9=Cx9_bis_11388_Lux (CM_RLS_Vorfeldhelligkeit_Boost_Cx9_bis_11388_Lux), 10=Cxa_bis_10353_Lux (CM_RLS_Vorfeldhelligkeit_Boost_Cxa_bis_10353_Lux), 11=Cxb_bis_9412_Lux (CM_RLS_Vorfeldhelligkeit_Boost_Cxb_bis_9412_Lux), 12=Cxc_bis_8556_Lux (CM_RLS_Vorfeldhelligkeit_Boost_Cxc_bis_8556_Lux), 13=Cxd_bis_7778_Lux (CM_RLS_Vorfeldhelligkeit_Boost_Cxd_bis_7778_Lux), 14=Cxe_bis_7071_Lux (CM_RLS_Vorfeldhelligkeit_Boost_Cxe_bis_7071_Lux), 15=Cxf_bis_6428_Lux (CM_RLS_Vorfeldhelligkeit_Boost_Cxf_bis_6428_Lux)}, range raw 0..15  # erweiterte Helligkeitssensierung für HUD
          signal LS_Helligkeit_IR_XIX_RLS_02_XIX_E3V_K2CANFD: start 32, 8 bit, little-endian, data-type-policy=OVERRIDE, i-signal-type=PRIMITIVE, init-value=254, base-type=BT_LS_Helligkeit_IR, invalid-value=Invalid_LS_Helligkeit_IR_XIX_RLS_02_XIX_E3V_K2CANFD:255, compu {phys=raw*400 for raw 0..253, 254=Cxfe_Init (CM_LS_Helligkeit_IR_Cxfe_Init), 255=Cxff_Fehler (CM_LS_Helligkeit_IR_Cxff_Fehler); unit Unit_Lux}, range phys 0..101200 Unit_Lux, raw 0..255, unit=Unit_Lux  # Globalfeldhelligkeit
          signal LS_Helligkeit_FW_XIX_RLS_02_XIX_E3V_K2CANFD: start 40, 10 bit, little-endian, data-type-policy=OVERRIDE, i-signal-type=PRIMITIVE, init-value=1022, base-type=BT_LS_Helligkeit_FW, invalid-value=Invalid_LS_Helligkeit_FW_XIX_RLS_02_XIX_E3V_K2CANFD:1023, compu {phys=raw*6 for raw 0..1021, 1022=Cx3fe_Init (CM_LS_Helligkeit_FW_Cx3fe_Init), 1023=Cx3ff_Fehler (CM_LS_Helligkeit_FW_Cx3ff_Fehler); unit Unit_Lux}, range phys 0..6126 Unit_Lux, raw 0..1023, unit=Unit_Lux  # Vorfeldhelligkeit
          signal ISignalVoid_RLS_02_XIX_E3V_K2CANFD_0: start 50, 2 bit, little-endian, system signal SignalVoid_RLS_02_0, data-type-policy=OVERRIDE, i-signal-type=PRIMITIVE, base-type=BT_SignalVoid
          signal RS_Regenmenge_XIX_RLS_02_XIX_E3V_K2CANFD: start 52, 4 bit, little-endian, data-type-policy=OVERRIDE, i-signal-type=PRIMITIVE, init-value=14, base-type=BT_RS_Regenmenge, invalid-value=Invalid_RS_Regenmenge_XIX_RLS_02_XIX_E3V_K2CANFD:15, compu {0=Cx0_0 (CM_RS_Regenmenge_Cx0_0), 1=Cx1_0_0_bis_0_3 (CM_RS_Regenmenge_Cx1_0_0_bis_0_3) (0,0_bis_0,3), 2=Cx2_0_31_bis_1_4 (CM_RS_Regenmenge_Cx2_0_31_bis_1_4) (0,31_bis_1,4), 3=Cx3_1_41_bis_2_0 (CM_RS_Regenmenge_Cx3_1_41_bis_2_0) (1,41_bis_2,0), 4=Cx4_2_01_bis_2_8 (CM_RS_Regenmenge_Cx4_2_01_bis_2_8) (2,01_bis_2,8), 5=Cx5_2_81_bis_3_3 (CM_RS_Regenmenge_Cx5_2_81_bis_3_3) (2,81_bis_3,3), 6=Cx6_3_31_bis_4_0 (CM_RS_Regenmenge_Cx6_3_31_bis_4_0) (3,31_bis_4,0), 7=Cx7_4_01_bis_5_0 (CM_RS_Regenmenge_Cx7_4_01_bis_5_0) (4,01_bis_5,0), 8=Cx8_5_01_bis_7_0 (CM_RS_Regenmenge_Cx8_5_01_bis_7_0) (5,01_bis_7,0), 9=Cx9_7_01_bis_9_0 (CM_RS_Regenmenge_Cx9_7_01_bis_9_0) (7,01_bis_9,0), 10=Cxa_9_01_bis_11_0 (CM_RS_Regenmenge_Cxa_9_01_bis_11_0) (9,01_bis_11,0), 11=Cxb_11_01_bis_15_0 (CM_RS_Regenmenge_Cxb_11_01_bis_15_0) (11,01_bis_15,0), 12=Cxc_15_01_bis_22_0 (CM_RS_Regenmenge_Cxc_15_01_bis_22_0) (15,01_bis_22,0), 13=Cxd_22_01 (CM_RS_Regenmenge_Cxd_22_01) (>22,01), 14=Cxe_Init (CM_RS_Regenmenge_Cxe_Init), 15=Cxf_Fehler (CM_RS_Regenmenge_Cxf_Fehler)}, range raw 0..15  # Regenmenge
          signal ISignalVoid_RLS_02_XIX_E3V_K2CANFD_1: start 56, 8 bit, little-endian, system signal SignalVoid_RLS_02_1, data-type-policy=OVERRIDE, i-signal-type=PRIMITIVE, base-type=BT_SignalVoid
          mapping SG_RLS_02_XIX_E3V_K2CANFD: i-signal-group=SG_RLS_02_XIX_E3V_K2CANFD, transfer-property=TRIGGERED-WITHOUT-REPETITION
      frame RLSs_01_XIX_E3V_K2CANFD: id 0x27E, from SAM, frame-length=8, can-addressing-mode=STANDARD, can-frame-rx-behavior=CAN-FD, can-frame-tx-behavior=CAN-FD
        pdu RLSs_01_XIX_E3V_K2CANFD: length=8, transmission-mode-true-timing=cyclic-timing={time-offset=0, time-period=0.08}, unused-bit-pattern=0
          signal RLS_Zaehler_XIX_RLSs_01_XIX_E3V_K2CANFD: start 0, 4 bit, little-endian, data-type-policy=OVERRIDE, i-signal-type=PRIMITIVE, base-type=BT_RLS_Zaehler, compu {phys=raw for raw 0..15}, range phys 0..15, raw 0..15
          signal RLS_Qualifizierungsbit_XIX_RLSs_01_XIX_E3V_K2CANFD: start 4, 1 bit, little-endian, data-type-policy=OVERRIDE, i-signal-type=PRIMITIVE, init-value=0, base-type=BT_RLS_Qualifizierungsbit, compu {0=Cx0_ungueltig (CM_RLS_Qualifizierungsbit_Cx0_ungueltig), 1=Cx1_gueltig (CM_RLS_Qualifizierungsbit_Cx1_gueltig)}, range raw 0..1  # Qualifizierungsbit für die Signale "LS_Licht_ein" und "LS_Licht_ein_invers"
          signal RS_Wischergeschwindigkeit_XIX_RLSs_01_XIX_E3V_K2CANFD: start 5, 3 bit, little-endian, data-type-policy=OVERRIDE, i-signal-type=PRIMITIVE, init-value=0, base-type=BT_RS_Wischergeschwindigkeit, compu {0=Cx0_kein_Wischen (CM_RS_Wischergeschwindigkeit_Cx0_kein_Wischen) (kein Wischen), 1=Cx1_42_Huebe_min (CM_RS_Wischergeschwindigkeit_Cx1_42_Huebe_min) (42 Huebe/min), 2=Cx2_45_Huebe_min (CM_RS_Wischergeschwindigkeit_Cx2_45_Huebe_min) (45 Huebe/min), 3=Cx3_48_Huebe_min (CM_RS_Wischergeschwindigkeit_Cx3_48_Huebe_min) (48 Huebe/min), 4=Cx4_51_Huebe_min (CM_RS_Wischergeschwindigkeit_Cx4_51_Huebe_min) (51 Huebe/min), 5=Cx5_54_Huebe_min (CM_RS_Wischergeschwindigkeit_Cx5_54_Huebe_min) (54 Huebe/min), 6=Cx6_57_Huebe_min (CM_RS_Wischergeschwindigkeit_Cx6_57_Huebe_min) (57 Huebe/min), 7=Cx7_60_Huebe_min (CM_RS_Wischergeschwindigkeit_Cx7_60_Huebe_min) (60 Huebe/min)}, range raw 0..7  # Wischergeschwindigkeit (Hübe/min)
          signal RS_Schwall_XIX_RLSs_01_XIX_E3V_K2CANFD: start 8, 1 bit, little-endian, data-type-policy=OVERRIDE, i-signal-type=PRIMITIVE, init-value=0, base-type=BT_RS_Schwall, compu {0=Cx0_Aus (CM_RS_Schwall_Cx0_Aus), 1=Cx1_Ein (CM_RS_Schwall_Cx1_Ein)}, range raw 0..1  # Schwallereignis
          signal RS_Verglasung_schliessen_XIX_RLSs_01_XIX_E3V_K2CANFD: start 9, 1 bit, little-endian, data-type-policy=OVERRIDE, i-signal-type=PRIMITIVE, init-value=0, base-type=BT_RS_Verglasung_schliessen, compu {0=Cx0_Verglasung_nicht_schliessen (CM_RS_Verglasung_schliessen_Cx0_Verglasung_nicht_schliessen) (Verglasung nicht schliessen), 1=Cx1_Verglasung_schliessen (CM_RS_Verglasung_schliessen_Cx1_Verglasung_schliessen) (Verglasung schliessen)}, range raw 0..1  # Anforderung: Verglasung schliessen
          signal RS_versParklage_Wischer_XIX_RLSs_01_XIX_E3V_K2CANFD: start 10, 1 bit, little-endian, data-type-policy=OVERRIDE, i-signal-type=PRIMITIVE, init-value=0, base-type=BT_RS_versParklage_Wischer, compu {0=Cx0_Aus (CM_RS_versParklage_Wischer_Cx0_Aus), 1=Cx1_Ein (CM_RS_versParklage_Wischer_Cx1_Ein)}, range raw 0..1  # versenkte Parklage Wischer
          signal LS_Licht_ein_XIX_RLSs_01_XIX_E3V_K2CANFD: start 11, 1 bit, little-endian, data-type-policy=OVERRIDE, i-signal-type=PRIMITIVE, init-value=0, base-type=BT_LS_Licht_ein, compu {0=Cx0_Aus (CM_LS_Licht_ein_Cx0_Aus), 1=Cx1_Ein (CM_LS_Licht_ein_Cx1_Ein)}, range raw 0..1  # Anfoderung Fahrlicht
          signal LS_Licht_ein_invers_XIX_RLSs_01_XIX_E3V_K2CANFD: start 12, 1 bit, little-endian, data-type-policy=OVERRIDE, i-signal-type=PRIMITIVE, init-value=1, base-type=BT_LS_Licht_ein_invers, compu {0=Cx0_Aus (CM_LS_Licht_ein_invers_Cx0_Aus), 1=Cx1_Ein (CM_LS_Licht_ein_invers_Cx1_Ein)}, range raw 0..1  # Inversbit Anforderung Fahrlicht
          signal LS_Dunkel_XIX_RLSs_01_XIX_E3V_K2CANFD: start 13, 1 bit, little-endian, data-type-policy=OVERRIDE, i-signal-type=PRIMITIVE, init-value=0, base-type=BT_LS_Dunkel, compu {0=Cx0_Hell (CM_LS_Dunkel_Cx0_Hell), 1=Cx1_Dunkel (CM_LS_Dunkel_Cx1_Dunkel)}, range raw 0..1  # Regen- / Lichtsensor
          signal LS_TFL_mit_SL_ein_XIX_RLSs_01_XIX_E3V_K2CANFD: start 14, 1 bit, little-endian, data-type-policy=OVERRIDE, i-signal-type=PRIMITIVE, init-value=1, base-type=BT_LS_TFL_mit_SL_ein, compu {0=Cx0_TFL_mit_SL_aus (CM_LS_TFL_mit_SL_ein_Cx0_TFL_mit_SL_aus), 1=Cx1_TFL_mit_SL_ein (CM_LS_TFL_mit_SL_ein_Cx1_TFL_mit_SL_ein)}, range raw 0..1  # Anforderung Tagfahrlich mit Schlusslicht
          signal RS_Regenfahrlicht_XIX_RLSs_01_XIX_E3V_K2CANFD: start 15, 1 bit, little-endian, data-type-policy=OVERRIDE, i-signal-type=PRIMITIVE, init-value=0, base-type=BT_RS_Regenfahrlicht, compu {0=Cx0_Aus (CM_RS_Regenfahrlicht_Cx0_Aus), 1=Cx1_Ein (CM_RS_Regenfahrlicht_Cx1_Ein)}, range raw 0..1  # Regenlicht Anforderung
          signal RS_AdaptierungError_XIX_RLSs_01_XIX_E3V_K2CANFD: start 16, 1 bit, little-endian, data-type-policy=OVERRIDE, i-signal-type=PRIMITIVE, init-value=0, base-type=BT_RS_AdaptierungError, invalid-value=Invalid_RS_AdaptierungError_XIX_RLSs_01_XIX_E3V_K2CANFD:1, compu {0=Cx0_normal (CM_RS_AdaptierungError_Cx0_normal), 1=Cx1_Fehler (CM_RS_AdaptierungError_Cx1_Fehler)}, range raw 0..1  # Adaptierungsfehler Regensensor
          signal RS_Error_XIX_RLSs_01_XIX_E3V_K2CANFD: start 17, 1 bit, little-endian, data-type-policy=OVERRIDE, i-signal-type=PRIMITIVE, init-value=0, base-type=BT_RS_Error, invalid-value=Invalid_RS_Error_XIX_RLSs_01_XIX_E3V_K2CANFD:1, compu {0=Cx0_normal (CM_RS_Error_Cx0_normal), 1=Cx1_Fehler (CM_RS_Error_Cx1_Fehler)}, range raw 0..1  # Fehler/Defekt Regensensorik
          signal LS_Error_XIX_RLSs_01_XIX_E3V_K2CANFD: start 18, 1 bit, little-endian, data-type-policy=OVERRIDE, i-signal-type=PRIMITIVE, init-value=0, base-type=BT_LS_Error, invalid-value=Invalid_LS_Error_XIX_RLSs_01_XIX_E3V_K2CANFD:1, compu {0=Cx0_normal (CM_LS_Error_Cx0_normal), 1=Cx1_Fehler (CM_LS_Error_Cx1_Fehler)}, range raw 0..1  # Fehler/Defekt Lichtsensorik
          signal RLS_ResponseError_XIX_RLSs_01_XIX_E3V_K2CANFD: start 19, 1 bit, little-endian, data-type-policy=OVERRIDE, i-signal-type=PRIMITIVE, init-value=0, base-type=BT_RLS_ResponseError, invalid-value=Invalid_RLS_ResponseError_XIX_RLSs_01_XIX_E3V_K2CANFD:1, compu {0=Cx0_normal (CM_RLS_ResponseError_Cx0_normal), 1=Cx1_Fehler (CM_RLS_ResponseError_Cx1_Fehler)}, range raw 0..1  # siehe LIN2.0-Specification (Darf nicht über ein Fehlergueltigkeitsbit abgesichtert werden!)
          signal RLS_Vorfeldhelligkeit_Boost_XIX_RLSs_01_XIX_E3V_K2CANFD: start 20, 4 bit, little-endian, data-type-policy=OVERRIDE, i-signal-type=PRIMITIVE, init-value=15, base-type=BT_RLS_Vorfeldhelligkeit_Boost, compu {0=Cx0_groesser_24413_Lux (CM_RLS_Vorfeldhelligkeit_Boost_Cx0_groesser_24413_Lux), 1=Cx1_bis_24413_Lux (CM_RLS_Vorfeldhelligkeit_Boost_Cx1_bis_24413_Lux), 2=Cx2_bis_22193_Lux (CM_RLS_Vorfeldhelligkeit_Boost_Cx2_bis_22193_Lux), 3=Cx3_bis_20176_Lux (CM_RLS_Vorfeldhelligkeit_Boost_Cx3_bis_20176_Lux), 4=Cx4_bis_18342_Lux (CM_RLS_Vorfeldhelligkeit_Boost_Cx4_bis_18342_Lux), 5=Cx5_bis_16647_Lux (CM_RLS_Vorfeldhelligkeit_Boost_Cx5_bis_16647_Lux), 6=Cx6_bis_15158_Lux (CM_RLS_Vorfeldhelligkeit_Boost_Cx6_bis_15158_Lux), 7=Cx7_bis_13780_Lux (CM_RLS_Vorfeldhelligkeit_Boost_Cx7_bis_13780_Lux), 8=Cx8_bis_12527_Lux (CM_RLS_Vorfeldhelligkeit_Boost_Cx8_bis_12527_Lux), 9=Cx9_bis_11388_Lux (CM_RLS_Vorfeldhelligkeit_Boost_Cx9_bis_11388_Lux), 10=Cxa_bis_10353_Lux (CM_RLS_Vorfeldhelligkeit_Boost_Cxa_bis_10353_Lux), 11=Cxb_bis_9412_Lux (CM_RLS_Vorfeldhelligkeit_Boost_Cxb_bis_9412_Lux), 12=Cxc_bis_8556_Lux (CM_RLS_Vorfeldhelligkeit_Boost_Cxc_bis_8556_Lux), 13=Cxd_bis_7778_Lux (CM_RLS_Vorfeldhelligkeit_Boost_Cxd_bis_7778_Lux), 14=Cxe_bis_7071_Lux (CM_RLS_Vorfeldhelligkeit_Boost_Cxe_bis_7071_Lux), 15=Cxf_bis_6428_Lux (CM_RLS_Vorfeldhelligkeit_Boost_Cxf_bis_6428_Lux)}, range raw 0..15  # erweiterte Helligkeitssensierung für HUD
          signal LS_Helligkeit_IR_XIX_RLSs_01_XIX_E3V_K2CANFD: start 24, 8 bit, little-endian, data-type-policy=OVERRIDE, i-signal-type=PRIMITIVE, init-value=254, base-type=BT_LS_Helligkeit_IR, invalid-value=Invalid_LS_Helligkeit_IR_XIX_RLSs_01_XIX_E3V_K2CANFD:255, compu {phys=raw*400 for raw 0..253, 254=Cxfe_Init (CM_LS_Helligkeit_IR_Cxfe_Init), 255=Cxff_Fehler (CM_LS_Helligkeit_IR_Cxff_Fehler); unit Unit_Lux}, range phys 0..101200 Unit_Lux, raw 0..255, unit=Unit_Lux  # Globalfeldhelligkeit
          signal LS_Helligkeit_FW_XIX_RLSs_01_XIX_E3V_K2CANFD: start 32, 10 bit, little-endian, data-type-policy=OVERRIDE, i-signal-type=PRIMITIVE, init-value=1022, base-type=BT_LS_Helligkeit_FW, invalid-value=Invalid_LS_Helligkeit_FW_XIX_RLSs_01_XIX_E3V_K2CANFD:1023, compu {phys=raw*6 for raw 0..1021, 1022=Cx3fe_Init (CM_LS_Helligkeit_FW_Cx3fe_Init), 1023=Cx3ff_Fehler (CM_LS_Helligkeit_FW_Cx3ff_Fehler); unit Unit_Lux}, range phys 0..6126 Unit_Lux, raw 0..1023, unit=Unit_Lux  # Vorfeldhelligkeit
          signal RS_Regenmenge_XIX_RLSs_01_XIX_E3V_K2CANFD: start 44, 4 bit, little-endian, data-type-policy=OVERRIDE, i-signal-type=PRIMITIVE, init-value=14, base-type=BT_RS_Regenmenge, invalid-value=Invalid_RS_Regenmenge_XIX_RLSs_01_XIX_E3V_K2CANFD:15, compu {0=Cx0_0 (CM_RS_Regenmenge_Cx0_0), 1=Cx1_0_0_bis_0_3 (CM_RS_Regenmenge_Cx1_0_0_bis_0_3) (0,0_bis_0,3), 2=Cx2_0_31_bis_1_4 (CM_RS_Regenmenge_Cx2_0_31_bis_1_4) (0,31_bis_1,4), 3=Cx3_1_41_bis_2_0 (CM_RS_Regenmenge_Cx3_1_41_bis_2_0) (1,41_bis_2,0), 4=Cx4_2_01_bis_2_8 (CM_RS_Regenmenge_Cx4_2_01_bis_2_8) (2,01_bis_2,8), 5=Cx5_2_81_bis_3_3 (CM_RS_Regenmenge_Cx5_2_81_bis_3_3) (2,81_bis_3,3), 6=Cx6_3_31_bis_4_0 (CM_RS_Regenmenge_Cx6_3_31_bis_4_0) (3,31_bis_4,0), 7=Cx7_4_01_bis_5_0 (CM_RS_Regenmenge_Cx7_4_01_bis_5_0) (4,01_bis_5,0), 8=Cx8_5_01_bis_7_0 (CM_RS_Regenmenge_Cx8_5_01_bis_7_0) (5,01_bis_7,0), 9=Cx9_7_01_bis_9_0 (CM_RS_Regenmenge_Cx9_7_01_bis_9_0) (7,01_bis_9,0), 10=Cxa_9_01_bis_11_0 (CM_RS_Regenmenge_Cxa_9_01_bis_11_0) (9,01_bis_11,0), 11=Cxb_11_01_bis_15_0 (CM_RS_Regenmenge_Cxb_11_01_bis_15_0) (11,01_bis_15,0), 12=Cxc_15_01_bis_22_0 (CM_RS_Regenmenge_Cxc_15_01_bis_22_0) (15,01_bis_22,0), 13=Cxd_22_01 (CM_RS_Regenmenge_Cxd_22_01) (>22,01), 14=Cxe_Init (CM_RS_Regenmenge_Cxe_Init), 15=Cxf_Fehler (CM_RS_Regenmenge_Cxf_Fehler)}, range raw 0..15  # Regenmenge
          signal RLS_CRC_XIX_RLSs_01_XIX_E3V_K2CANFD: start 56, 8 bit, little-endian, data-type-policy=OVERRIDE, i-signal-type=PRIMITIVE, base-type=BT_RLS_CRC, compu {phys=raw for raw 0..255}, range phys 0..255, raw 0..255  # Für MLB: Berechnung siehe Lastenheft "Kommunikationsabsicherung für FlexRay und CAN" Ab MQB und MLBevo: Berechnung siehe Lastenheft "End-to-End Kommunikationsabsicherung" Endwerte siehe Begleitdokument "S-PDU Kennungsfolgen"
          mapping SG_RLSs_01_XIX_E3V_K2CANFD: i-signal-group=SG_RLSs_01_XIX_E3V_K2CANFD, transfer-property=PENDING
          signal ISignalVoid_RLSs_01_XIX_E3V_K2CANFD_0: start 42, 2 bit, little-endian, system signal SignalVoid_RLSs_01_0, data-type-policy=OVERRIDE, i-signal-type=PRIMITIVE, base-type=BT_SignalVoid
          signal ISignalVoid_RLSs_01_XIX_E3V_K2CANFD_1: start 48, 8 bit, little-endian, system signal SignalVoid_RLSs_01_1, data-type-policy=OVERRIDE, i-signal-type=PRIMITIVE, base-type=BT_SignalVoid
